VERSION ""

NS_ :

BS_:

BU_: PowertrainControlModule AtmosphericSensor SafetyRestraintSystem2 Aftertreatment_2_GasOutlet Aftertreatment_2_GasIntake DieselParticulateFilterControl Turbocharger SafetyRestraintSystem1 CabDisplay2 Aftertreatment_1_GasOutlet Aftertreatment_1_GasIntake OnBoardDataLogger OffBoardDiagnosticTool2 OffBoardDiagnosticTool1 FileServer ParkingBrakeController SeatController2 FanDriveController SteeringColumnUnit CommunicationUnitRadio CommunicationUnitSatellite CommunicationUnitCellular PropulsionBatteryCharger ChassisController2 ChassisController1 EngineValveControl AuxiliaryHeater2 AuxiliaryHeater1 ClutchUnit RampControl InformationSystem1 SuspensionSystemController2 OilSensor VehicleDynamicStability ExhaustEmissionController TransmissionDisplay2 TransmissionDisplay1 ClimateControl2 WaterPumpController RearAxleSteeringController LightingOperatorControl SeatController1 IgnitionController2 IgnitionController1 TirePressureController CabController2 CabController1 PneumaticSystemController SuspensionSystemController1 HydraulicPumpController EnduranceBrakingSystem RetarderExhaustEngine2 OnBoardDiagnosticUnit HeadwayController RetarderExhaustEngine1 CabDisplay1 ManagementComputer VirtualTerminal OffVehicleGateway PowerTakeOffFront HitchControl AuxiliaryValveControl BodyController TractorTrailerBridge1 StarterSystem ElectricalSystem VehicleSecurity VehicleNavigation AerodynamicControl ElectricalChargingSystem ClimateControl1 TripRecorder InstrumentCluster SuspensionDriveAxle2 SuspensionDriveAxle1 SuspensionSteerAxle SteeringController FuelSystem CruiseControl RetarderDriveline RetarderEngine BrakesDriveAxle2 BrakesDriveAxle1 BrakesSystemController BrakesSteerAxle AxleDrive2 AxleDrive1 AxleSteering PowerTakeOff ShiftConsoleSecondary ShiftConsolePrimary Transmission2 Transmission1 Engine2 Engine1

BO_ 2364712446 HVESP16MS1: 8 Vector__XXX
 SG_ Module32OperationalStatus : 62|2@1+ (1,0) [0|3] "" Vector__XXX
 SG_ Module31OperationalStatus : 60|2@1+ (1,0) [0|3] "" Vector__XXX
 SG_ Module30OperationalStatus : 58|2@1+ (1,0) [0|3] "" Vector__XXX
 SG_ Module29OperationalStatus : 56|2@1+ (1,0) [0|3] "" Vector__XXX
 SG_ Module28OperationalStatus : 54|2@1+ (1,0) [0|3] "" Vector__XXX
 SG_ Module27OperationalStatus : 52|2@1+ (1,0) [0|3] "" Vector__XXX
 SG_ Module26OperationalStatus : 50|2@1+ (1,0) [0|3] "" Vector__XXX
 SG_ Module25OperationalStatus : 48|2@1+ (1,0) [0|3] "" Vector__XXX
 SG_ Module24OperationalStatus : 46|2@1+ (1,0) [0|3] "" Vector__XXX
 SG_ Module23OperationalStatus : 44|2@1+ (1,0) [0|3] "" Vector__XXX
 SG_ Module22OperationalStatus : 42|2@1+ (1,0) [0|3] "" Vector__XXX
 SG_ Module21OperationalStatus : 40|2@1+ (1,0) [0|3] "" Vector__XXX
 SG_ Module20OperationalStatus : 38|2@1+ (1,0) [0|3] "" Vector__XXX
 SG_ Module19OperationalStatus : 36|2@1+ (1,0) [0|3] "" Vector__XXX
 SG_ Module18OperationalStatus : 34|2@1+ (1,0) [0|3] "" Vector__XXX
 SG_ Module17OperationalStatus : 32|2@1+ (1,0) [0|3] "" Vector__XXX
 SG_ Module16OperationalStatus : 30|2@1+ (1,0) [0|3] "" Vector__XXX
 SG_ Module15OperationalStatus : 28|2@1+ (1,0) [0|3] "" Vector__XXX
 SG_ Module14OperationalStatus : 26|2@1+ (1,0) [0|3] "" Vector__XXX
 SG_ Module13OperationalStatus : 24|2@1+ (1,0) [0|3] "" Vector__XXX
 SG_ Module12OperationalStatus : 22|2@1+ (1,0) [0|3] "" Vector__XXX
 SG_ Module11OperationalStatus : 20|2@1+ (1,0) [0|3] "" Vector__XXX
 SG_ Module10OperationalStatus : 18|2@1+ (1,0) [0|3] "" Vector__XXX
 SG_ Module9OperationalStatus : 16|2@1+ (1,0) [0|3] "" Vector__XXX
 SG_ Module8OperationalStatus : 14|2@1+ (1,0) [0|3] "" Vector__XXX
 SG_ Module7OperationalStatus : 12|2@1+ (1,0) [0|3] "" Vector__XXX
 SG_ Module6OperationalStatus : 10|2@1+ (1,0) [0|3] "" Vector__XXX
 SG_ Module5OperationalStatus : 8|2@1+ (1,0) [0|3] "" Vector__XXX
 SG_ Module4OperationalStatus : 6|2@1+ (1,0) [0|3] "" Vector__XXX
 SG_ Module3OperationalStatus : 4|2@1+ (1,0) [0|3] "" Vector__XXX
 SG_ Module2OperationalStatus : 2|2@1+ (1,0) [0|3] "" Vector__XXX
 SG_ Module1OperationalStatus : 0|2@1+ (1,0) [0|3] "" Vector__XXX

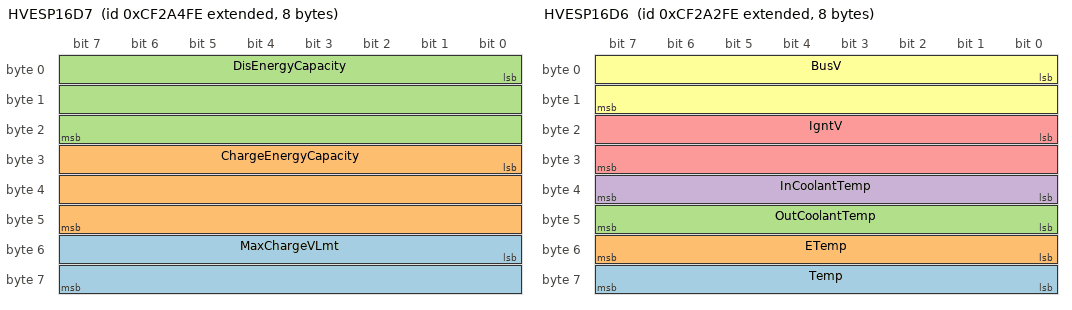
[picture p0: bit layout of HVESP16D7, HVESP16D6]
BO_ 2364712190 HVESP16D7: 8 Vector__XXX
 SG_ MaxChargeVLmt : 48|16@1+ (0.05,0) [0|3212.75] "V" Vector__XXX
 SG_ ChargeEnergyCapacity : 24|24@1+ (0.001,0) [0|16449.535] "kWh" Vector__XXX
 SG_ DisEnergyCapacity : 0|24@1+ (0.001,0) [0|16449.535] "kWh" Vector__XXX

BO_ 2364711934 HVESP16S1: 8 Vector__XXX
 SG_ Status1CRC : 56|8@1+ (1,0) [0|255] "" Vector__XXX
 SG_ Status1Counter : 52|4@1+ (1,0) [0|15] "" Vector__XXX
 SG_ OperationalStatus : 44|4@1+ (1,0) [0|15] "" Vector__XXX
 SG_ HVBusConnectionStatus : 40|4@1+ (1,0) [0|15] "" Vector__XXX
 SG_ InternalChargerStatus : 32|2@1+ (1,0) [0|3] "" Vector__XXX
 SG_ CellBalancingActive : 30|2@1+ (1,0) [0|3] "" Vector__XXX
 SG_ CellBalanceStatus : 28|2@1+ (1,0) [0|3] "" Vector__XXX
 SG_ StOfChargeStatus : 24|4@1+ (1,0) [0|15] "" Vector__XXX
 SG_ InertiaSwStatus : 22|2@1+ (1,0) [0|3] "" Vector__XXX
 SG_ HVILStatus : 20|2@1+ (1,0) [0|3] "" Vector__XXX
 SG_ HVBusPassiveIsolTestStatus : 16|4@1+ (1,0) [0|15] "" Vector__XXX
 SG_ HVBusActiveIsolTestStatus : 12|4@1+ (1,0) [0|15] "" Vector__XXX
 SG_ CenterOfPackContactorSt : 10|2@1+ (1,0) [0|3] "" Vector__XXX
 SG_ HVBusPreChargeRelaySt : 8|2@1+ (1,0) [0|3] "" Vector__XXX
 SG_ HVBusDisconnectForewarning : 4|4@1+ (1,0) [0|15] "" Vector__XXX
 SG_ HVBusContactorSt16028 : 2|2@1+ (1,0) [0|3] "" Vector__XXX
 SG_ HVBusContactorSt : 0|2@1+ (1,0) [0|3] "" Vector__XXX

BO_ 2364711678 HVESP16D6: 8 Vector__XXX
 SG_ Temp : 56|8@1+ (1,-40) [-40|210] "°C" Vector__XXX
 SG_ ETemp : 48|8@1+ (1,-40) [-40|210] "°C" Vector__XXX
 SG_ OutCoolantTemp : 40|8@1+ (1,-40) [-40|210] "°C" Vector__XXX
 SG_ InCoolantTemp : 32|8@1+ (1,-40) [-40|210] "°C" Vector__XXX
 SG_ IgntV : 16|16@1+ (0.01,0) [0|642.55] "V" Vector__XXX
 SG_ BusV : 0|16@1+ (0.05,0) [0|3212.75] "V" Vector__XXX

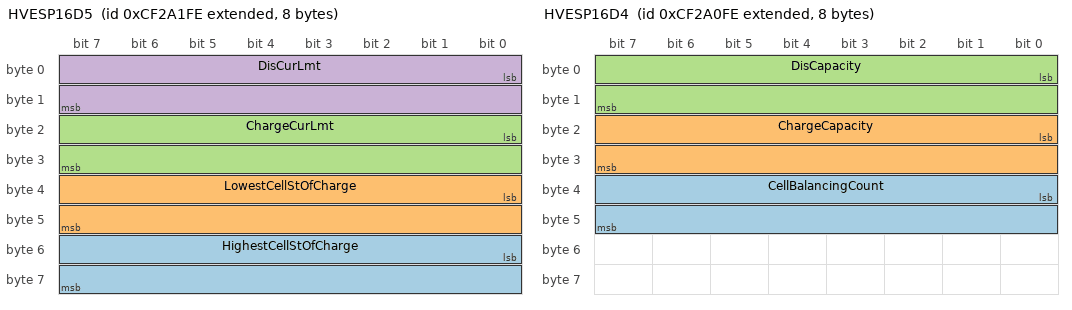
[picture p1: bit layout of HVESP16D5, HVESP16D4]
BO_ 2364711422 HVESP16D5: 8 Vector__XXX
 SG_ HighestCellStOfCharge : 48|16@1+ (0.0015625,0) [0|100.3984375] "%" Vector__XXX
 SG_ LowestCellStOfCharge : 32|16@1+ (0.0015625,0) [0|100.3984375] "%" Vector__XXX
 SG_ ChargeCurLmt : 16|16@1+ (0.05,-1600) [0|1612.75] "A" Vector__XXX
 SG_ DisCurLmt : 0|16@1+ (0.05,-1600) [-1600|0] "A" Vector__XXX

BO_ 2364711166 HVESP16D4: 8 Vector__XXX
 SG_ CellBalancingCount : 32|16@1+ (1,0) [0|64255] "" Vector__XXX
 SG_ ChargeCapacity : 16|16@1+ (0.01,0) [0|642.55] "Ah" Vector__XXX
 SG_ DisCapacity : 0|16@1+ (0.01,0) [0|642.55] "Ah" Vector__XXX

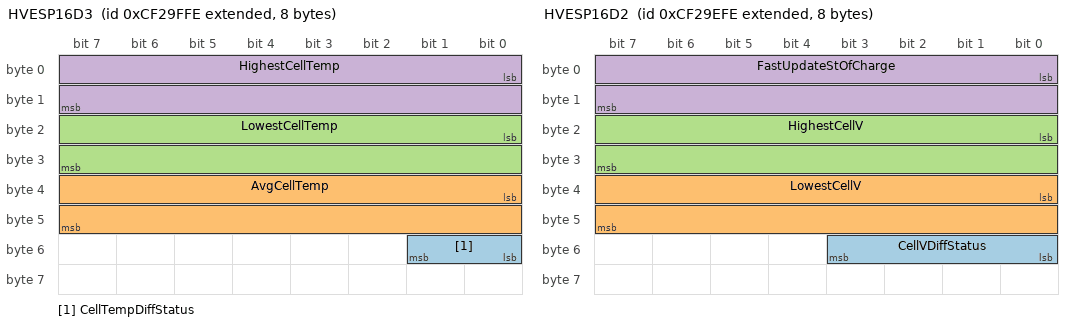
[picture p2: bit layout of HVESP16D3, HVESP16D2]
BO_ 2364710910 HVESP16D3: 8 Vector__XXX
 SG_ CellTempDiffStatus : 48|2@1+ (1,0) [0|3] "" Vector__XXX
 SG_ AvgCellTemp : 32|16@1+ (0.03125,-273) [-273|1734.96875] "°C" Vector__XXX
 SG_ LowestCellTemp : 16|16@1+ (0.03125,-273) [-273|1734.96875] "°C" Vector__XXX
 SG_ HighestCellTemp : 0|16@1+ (0.03125,-273) [-273|1734.96875] "°C" Vector__XXX

BO_ 2364710654 HVESP16D2: 8 Vector__XXX
 SG_ CellVDiffStatus : 48|4@1+ (1,0) [0|15] "" Vector__XXX
 SG_ LowestCellV : 32|16@1+ (0.001,0) [0|64.255] "V" Vector__XXX
 SG_ HighestCellV : 16|16@1+ (0.001,0) [0|64.255] "V" Vector__XXX
 SG_ FastUpdateStOfCharge : 0|16@1+ (0.0015625,0) [0|100.3984375] "%" Vector__XXX

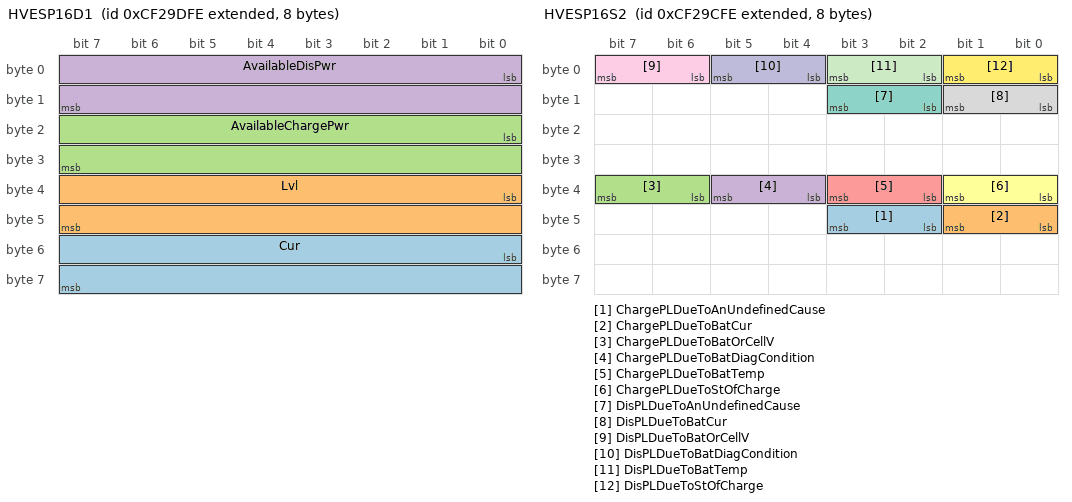
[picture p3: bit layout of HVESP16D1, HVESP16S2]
BO_ 2364710398 HVESP16D1: 8 Vector__XXX
 SG_ Cur : 48|16@1+ (0.05,-1600) [-1600|1612.75] "A" Vector__XXX
 SG_ Lvl : 32|16@1+ (0.05,0) [0|3212.75] "V" Vector__XXX
 SG_ AvailableChargePwr : 16|16@1+ (0.05,0) [0|3212.75] "kW" Vector__XXX
 SG_ AvailableDisPwr : 0|16@1+ (0.05,0) [0|3212.75] "kW" Vector__XXX

BO_ 2364710142 HVESP16S2: 8 Vector__XXX
 SG_ ChargePLDueToAnUndefinedCause : 42|2@1+ (1,0) [0|3] "" Vector__XXX
 SG_ ChargePLDueToBatCur : 40|2@1+ (1,0) [0|3] "" Vector__XXX
 SG_ ChargePLDueToBatOrCellV : 38|2@1+ (1,0) [0|3] "" Vector__XXX
 SG_ ChargePLDueToBatDiagCondition : 36|2@1+ (1,0) [0|3] "" Vector__XXX
 SG_ ChargePLDueToBatTemp : 34|2@1+ (1,0) [0|3] "" Vector__XXX
 SG_ ChargePLDueToStOfCharge : 32|2@1+ (1,0) [0|3] "" Vector__XXX
 SG_ DisPLDueToAnUndefinedCause : 10|2@1+ (1,0) [0|3] "" Vector__XXX
 SG_ DisPLDueToBatCur : 8|2@1+ (1,0) [0|3] "" Vector__XXX
 SG_ DisPLDueToBatOrCellV : 6|2@1+ (1,0) [0|3] "" Vector__XXX
 SG_ DisPLDueToBatDiagCondition : 4|2@1+ (1,0) [0|3] "" Vector__XXX
 SG_ DisPLDueToBatTemp : 2|2@1+ (1,0) [0|3] "" Vector__XXX
 SG_ DisPLDueToStOfCharge : 0|2@1+ (1,0) [0|3] "" Vector__XXX

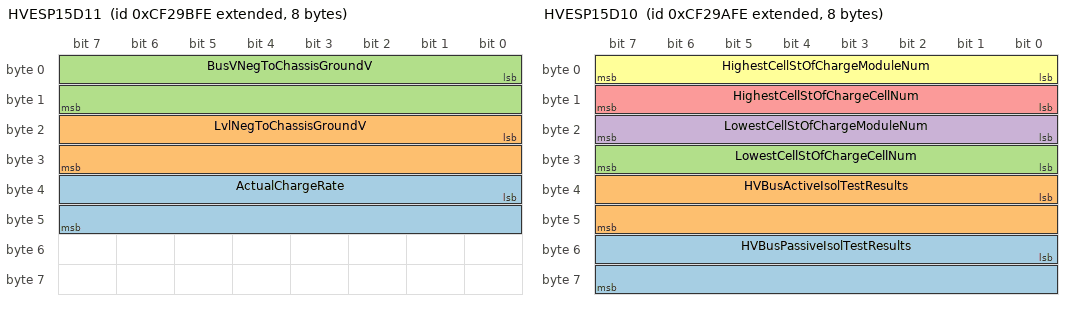
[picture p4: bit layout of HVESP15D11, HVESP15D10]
BO_ 2364709886 HVESP15D11: 8 Vector__XXX
 SG_ ActualChargeRate : 32|16@1+ (0.05,0) [0|3212.75] "kW" Vector__XXX
 SG_ LvlNegToChassisGroundV : 16|16@1+ (0.05,0) [0|3212.75] "V" Vector__XXX
 SG_ BusVNegToChassisGroundV : 0|16@1+ (0.05,0) [0|3212.75] "V" Vector__XXX

BO_ 2364709630 HVESP15D10: 8 Vector__XXX
 SG_ HVBusPassiveIsolTestResults : 48|16@1+ (0.1,0) [0|6425.5] "Ohm/V" Vector__XXX
 SG_ HVBusActiveIsolTestResults : 32|16@1+ (0.1,0) [0|6425.5] "Ohm/V" Vector__XXX
 SG_ LowestCellStOfChargeCellNum : 24|8@1+ (1,0) [0|250] "" Vector__XXX
 SG_ LowestCellStOfChargeModuleNum : 16|8@1+ (1,0) [0|250] "" Vector__XXX
 SG_ HighestCellStOfChargeCellNum : 8|8@1+ (1,0) [0|250] "" Vector__XXX
 SG_ HighestCellStOfChargeModuleNum : 0|8@1+ (1,0) [0|250] "" Vector__XXX

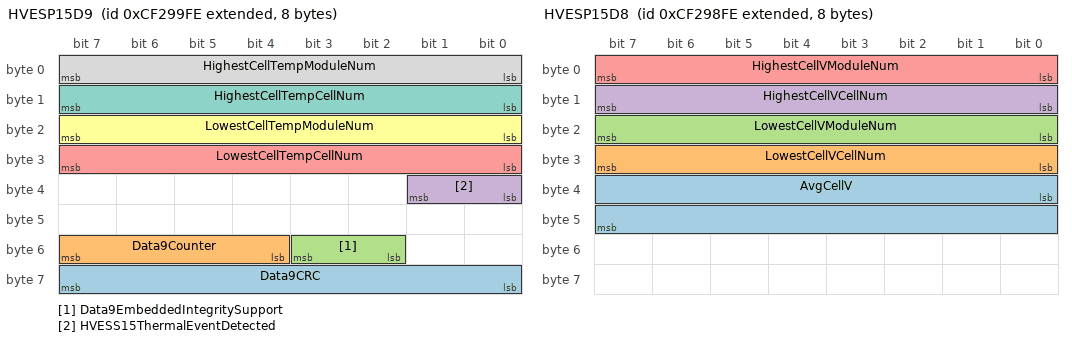
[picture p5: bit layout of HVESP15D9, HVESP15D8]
BO_ 2364709374 HVESP15D9: 8 Vector__XXX
 SG_ Data9CRC : 56|8@1+ (1,0) [0|255] "" Vector__XXX
 SG_ Data9Counter : 52|4@1+ (1,0) [0|15] "" Vector__XXX
 SG_ Data9EmbeddedIntegritySupport : 50|2@1+ (1,0) [0|3] "" Vector__XXX
 SG_ HVESS15ThermalEventDetected : 32|2@1+ (1,0) [0|3] "" Vector__XXX
 SG_ LowestCellTempCellNum : 24|8@1+ (1,0) [0|250] "" Vector__XXX
 SG_ LowestCellTempModuleNum : 16|8@1+ (1,0) [0|250] "" Vector__XXX
 SG_ HighestCellTempCellNum : 8|8@1+ (1,0) [0|250] "" Vector__XXX
 SG_ HighestCellTempModuleNum : 0|8@1+ (1,0) [0|250] "" Vector__XXX

BO_ 2364709118 HVESP15D8: 8 Vector__XXX
 SG_ AvgCellV : 32|16@1+ (0.001,0) [0|64.255] "V" Vector__XXX
 SG_ LowestCellVCellNum : 24|8@1+ (1,0) [0|250] "" Vector__XXX
 SG_ LowestCellVModuleNum : 16|8@1+ (1,0) [0|250] "" Vector__XXX
 SG_ HighestCellVCellNum : 8|8@1+ (1,0) [0|250] "" Vector__XXX
 SG_ HighestCellVModuleNum : 0|8@1+ (1,0) [0|250] "" Vector__XXX

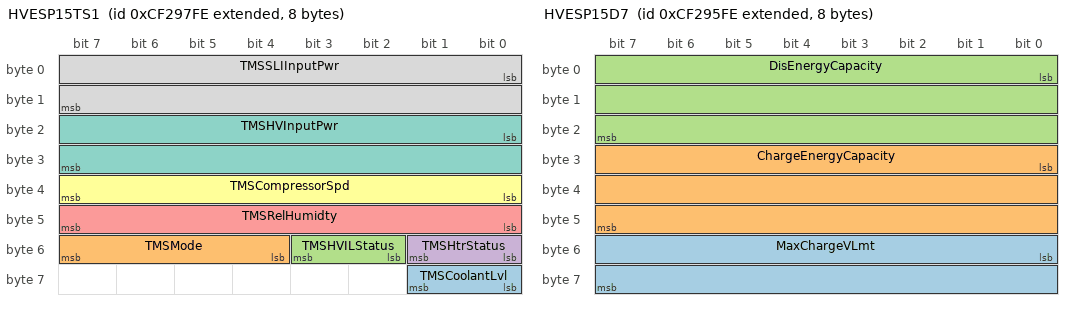
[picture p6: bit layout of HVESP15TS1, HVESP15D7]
BO_ 2364708862 HVESP15TS1: 8 Vector__XXX
 SG_ TMSCoolantLvl : 56|2@1+ (1,0) [0|3] "" Vector__XXX
 SG_ TMSMode : 52|4@1+ (1,0) [0|15] "" Vector__XXX
 SG_ TMSHVILStatus : 50|2@1+ (1,0) [0|3] "" Vector__XXX
 SG_ TMSHtrStatus : 48|2@1+ (1,0) [0|3] "" Vector__XXX
 SG_ TMSRelHumidty : 40|8@1+ (0.4,0) [0|100] "%" Vector__XXX
 SG_ TMSCompressorSpd : 32|8@1+ (32,0) [0|8000] "rpm" Vector__XXX
 SG_ TMSHVInputPwr : 16|16@1+ (0.5,0) [0|32127.5] "W" Vector__XXX
 SG_ TMSSLIInputPwr : 0|16@1+ (0.5,0) [0|32127.5] "W" Vector__XXX

BO_ 2364708606 HVESP15MS1: 8 Vector__XXX
 SG_ Module32OperationalStatus : 62|2@1+ (1,0) [0|3] "" Vector__XXX
 SG_ Module31OperationalStatus : 60|2@1+ (1,0) [0|3] "" Vector__XXX
 SG_ Module30OperationalStatus : 58|2@1+ (1,0) [0|3] "" Vector__XXX
 SG_ Module29OperationalStatus : 56|2@1+ (1,0) [0|3] "" Vector__XXX
 SG_ Module28OperationalStatus : 54|2@1+ (1,0) [0|3] "" Vector__XXX
 SG_ Module27OperationalStatus : 52|2@1+ (1,0) [0|3] "" Vector__XXX
 SG_ Module26OperationalStatus : 50|2@1+ (1,0) [0|3] "" Vector__XXX
 SG_ Module25OperationalStatus : 48|2@1+ (1,0) [0|3] "" Vector__XXX
 SG_ Module24OperationalStatus : 46|2@1+ (1,0) [0|3] "" Vector__XXX
 SG_ Module23OperationalStatus : 44|2@1+ (1,0) [0|3] "" Vector__XXX
 SG_ Module22OperationalStatus : 42|2@1+ (1,0) [0|3] "" Vector__XXX
 SG_ Module21OperationalStatus : 40|2@1+ (1,0) [0|3] "" Vector__XXX
 SG_ Module20OperationalStatus : 38|2@1+ (1,0) [0|3] "" Vector__XXX
 SG_ Module19OperationalStatus : 36|2@1+ (1,0) [0|3] "" Vector__XXX
 SG_ Module18OperationalStatus : 34|2@1+ (1,0) [0|3] "" Vector__XXX
 SG_ Module17OperationalStatus : 32|2@1+ (1,0) [0|3] "" Vector__XXX
 SG_ Module16OperationalStatus : 30|2@1+ (1,0) [0|3] "" Vector__XXX
 SG_ Module15OperationalStatus : 28|2@1+ (1,0) [0|3] "" Vector__XXX
 SG_ Module14OperationalStatus : 26|2@1+ (1,0) [0|3] "" Vector__XXX
 SG_ Module13OperationalStatus : 24|2@1+ (1,0) [0|3] "" Vector__XXX
 SG_ Module12OperationalStatus : 22|2@1+ (1,0) [0|3] "" Vector__XXX
 SG_ Module11OperationalStatus : 20|2@1+ (1,0) [0|3] "" Vector__XXX
 SG_ Module10OperationalStatus : 18|2@1+ (1,0) [0|3] "" Vector__XXX
 SG_ Module9OperationalStatus : 16|2@1+ (1,0) [0|3] "" Vector__XXX
 SG_ Module8OperationalStatus : 14|2@1+ (1,0) [0|3] "" Vector__XXX
 SG_ Module7OperationalStatus : 12|2@1+ (1,0) [0|3] "" Vector__XXX
 SG_ Module6OperationalStatus : 10|2@1+ (1,0) [0|3] "" Vector__XXX
 SG_ Module5OperationalStatus : 8|2@1+ (1,0) [0|3] "" Vector__XXX
 SG_ Module4OperationalStatus : 6|2@1+ (1,0) [0|3] "" Vector__XXX
 SG_ Module3OperationalStatus : 4|2@1+ (1,0) [0|3] "" Vector__XXX
 SG_ Module2OperationalStatus : 2|2@1+ (1,0) [0|3] "" Vector__XXX
 SG_ Module1OperationalStatus : 0|2@1+ (1,0) [0|3] "" Vector__XXX

BO_ 2364708350 HVESP15D7: 8 Vector__XXX
 SG_ MaxChargeVLmt : 48|16@1+ (0.05,0) [0|3212.75] "V" Vector__XXX
 SG_ ChargeEnergyCapacity : 24|24@1+ (0.001,0) [0|16449.535] "kWh" Vector__XXX
 SG_ DisEnergyCapacity : 0|24@1+ (0.001,0) [0|16449.535] "kWh" Vector__XXX

BO_ 2364708094 HVESP15S1: 8 Vector__XXX
 SG_ Status1CRC : 56|8@1+ (1,0) [0|255] "" Vector__XXX
 SG_ Status1Counter : 52|4@1+ (1,0) [0|15] "" Vector__XXX
 SG_ OperationalStatus : 44|4@1+ (1,0) [0|15] "" Vector__XXX
 SG_ HVBusConnectionStatus : 40|4@1+ (1,0) [0|15] "" Vector__XXX
 SG_ InternalChargerStatus : 32|2@1+ (1,0) [0|3] "" Vector__XXX
 SG_ CellBalancingActive : 30|2@1+ (1,0) [0|3] "" Vector__XXX
 SG_ CellBalanceStatus : 28|2@1+ (1,0) [0|3] "" Vector__XXX
 SG_ StOfChargeStatus : 24|4@1+ (1,0) [0|15] "" Vector__XXX
 SG_ InertiaSwStatus : 22|2@1+ (1,0) [0|3] "" Vector__XXX
 SG_ HVILStatus : 20|2@1+ (1,0) [0|3] "" Vector__XXX
 SG_ HVBusPassiveIsolTestStatus : 16|4@1+ (1,0) [0|15] "" Vector__XXX
 SG_ HVBusActiveIsolTestStatus : 12|4@1+ (1,0) [0|15] "" Vector__XXX
 SG_ CenterOfPackContactorSt : 10|2@1+ (1,0) [0|3] "" Vector__XXX
 SG_ HVBusPreChargeRelaySt : 8|2@1+ (1,0) [0|3] "" Vector__XXX
 SG_ HVBusDisconnectForewarning : 4|4@1+ (1,0) [0|15] "" Vector__XXX
 SG_ HVBusContactorSt15886 : 2|2@1+ (1,0) [0|3] "" Vector__XXX
 SG_ HVBusContactorSt : 0|2@1+ (1,0) [0|3] "" Vector__XXX

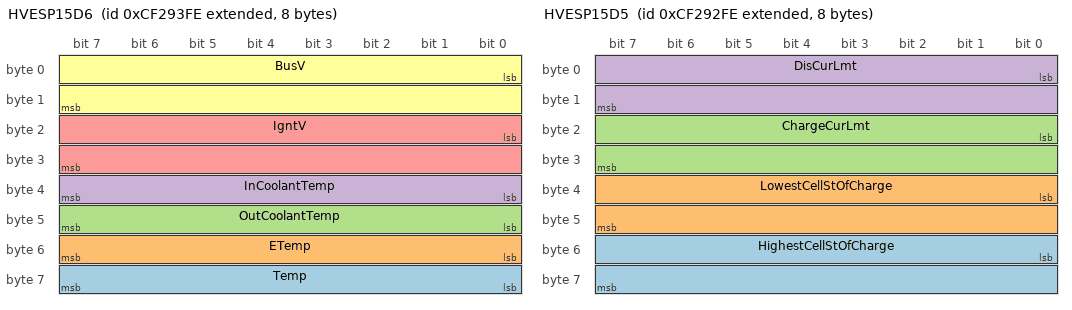
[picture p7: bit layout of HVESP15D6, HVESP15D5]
BO_ 2364707838 HVESP15D6: 8 Vector__XXX
 SG_ Temp : 56|8@1+ (1,-40) [-40|210] "°C" Vector__XXX
 SG_ ETemp : 48|8@1+ (1,-40) [-40|210] "°C" Vector__XXX
 SG_ OutCoolantTemp : 40|8@1+ (1,-40) [-40|210] "°C" Vector__XXX
 SG_ InCoolantTemp : 32|8@1+ (1,-40) [-40|210] "°C" Vector__XXX
 SG_ IgntV : 16|16@1+ (0.01,0) [0|642.55] "V" Vector__XXX
 SG_ BusV : 0|16@1+ (0.05,0) [0|3212.75] "V" Vector__XXX

BO_ 2364707582 HVESP15D5: 8 Vector__XXX
 SG_ HighestCellStOfCharge : 48|16@1+ (0.0015625,0) [0|100.3984375] "%" Vector__XXX
 SG_ LowestCellStOfCharge : 32|16@1+ (0.0015625,0) [0|100.3984375] "%" Vector__XXX
 SG_ ChargeCurLmt : 16|16@1+ (0.05,-1600) [0|1612.75] "A" Vector__XXX
 SG_ DisCurLmt : 0|16@1+ (0.05,-1600) [-1600|0] "A" Vector__XXX

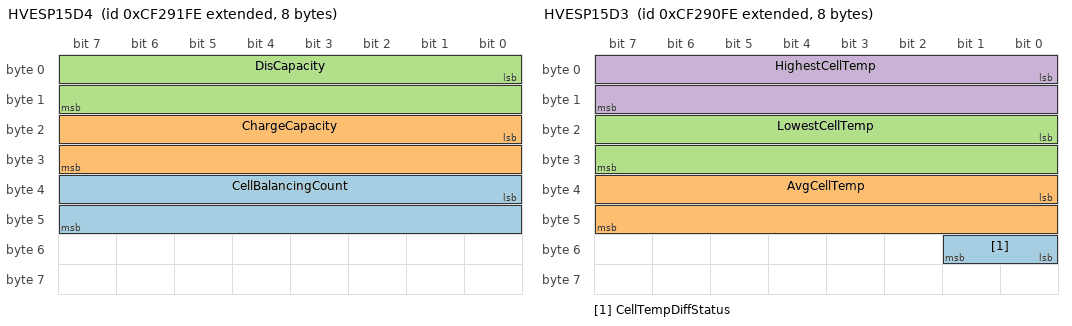
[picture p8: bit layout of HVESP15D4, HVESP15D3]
BO_ 2364707326 HVESP15D4: 8 Vector__XXX
 SG_ CellBalancingCount : 32|16@1+ (1,0) [0|64255] "" Vector__XXX
 SG_ ChargeCapacity : 16|16@1+ (0.01,0) [0|642.55] "Ah" Vector__XXX
 SG_ DisCapacity : 0|16@1+ (0.01,0) [0|642.55] "Ah" Vector__XXX

BO_ 2364707070 HVESP15D3: 8 Vector__XXX
 SG_ CellTempDiffStatus : 48|2@1+ (1,0) [0|3] "" Vector__XXX
 SG_ AvgCellTemp : 32|16@1+ (0.03125,-273) [-273|1734.96875] "°C" Vector__XXX
 SG_ LowestCellTemp : 16|16@1+ (0.03125,-273) [-273|1734.96875] "°C" Vector__XXX
 SG_ HighestCellTemp : 0|16@1+ (0.03125,-273) [-273|1734.96875] "°C" Vector__XXX

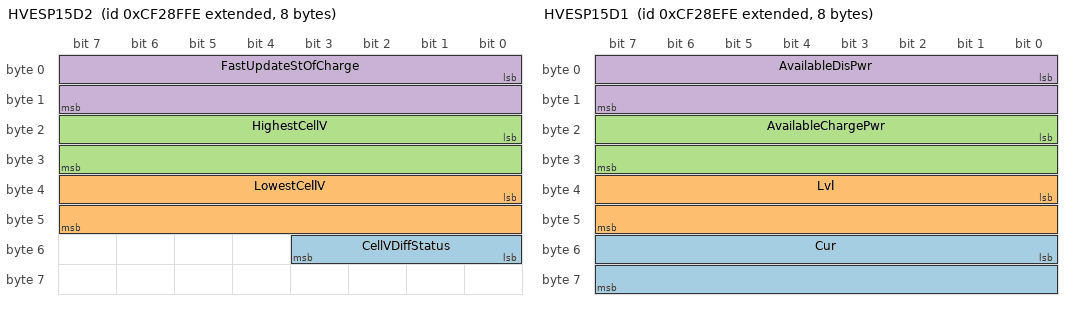
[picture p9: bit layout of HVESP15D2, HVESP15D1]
BO_ 2364706814 HVESP15D2: 8 Vector__XXX
 SG_ CellVDiffStatus : 48|4@1+ (1,0) [0|15] "" Vector__XXX
 SG_ LowestCellV : 32|16@1+ (0.001,0) [0|64.255] "V" Vector__XXX
 SG_ HighestCellV : 16|16@1+ (0.001,0) [0|64.255] "V" Vector__XXX
 SG_ FastUpdateStOfCharge : 0|16@1+ (0.0015625,0) [0|100.3984375] "%" Vector__XXX

BO_ 2364706558 HVESP15D1: 8 Vector__XXX
 SG_ Cur : 48|16@1+ (0.05,-1600) [-1600|1612.75] "A" Vector__XXX
 SG_ Lvl : 32|16@1+ (0.05,0) [0|3212.75] "V" Vector__XXX
 SG_ AvailableChargePwr : 16|16@1+ (0.05,0) [0|3212.75] "kW" Vector__XXX
 SG_ AvailableDisPwr : 0|16@1+ (0.05,0) [0|3212.75] "kW" Vector__XXX

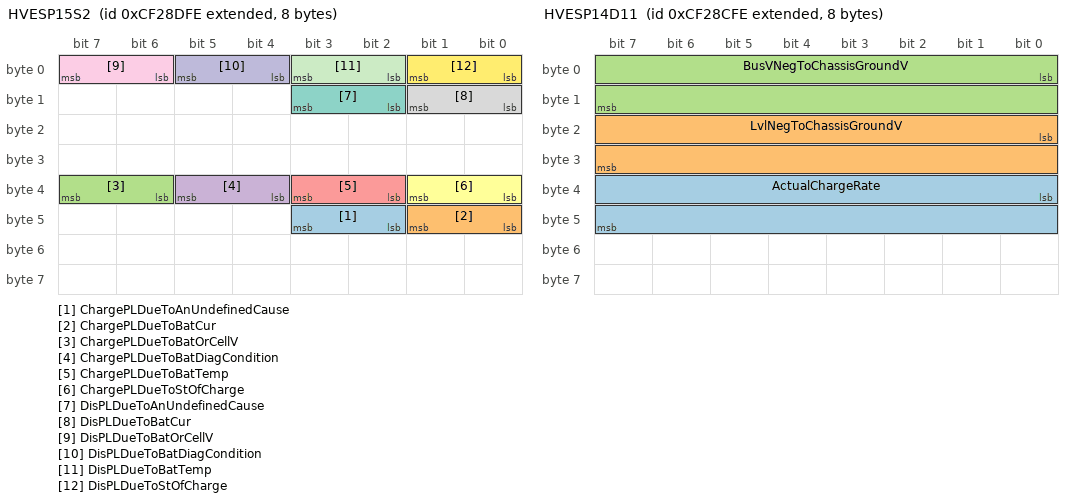
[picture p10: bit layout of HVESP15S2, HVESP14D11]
BO_ 2364706302 HVESP15S2: 8 Vector__XXX
 SG_ ChargePLDueToAnUndefinedCause : 42|2@1+ (1,0) [0|3] "" Vector__XXX
 SG_ ChargePLDueToBatCur : 40|2@1+ (1,0) [0|3] "" Vector__XXX
 SG_ ChargePLDueToBatOrCellV : 38|2@1+ (1,0) [0|3] "" Vector__XXX
 SG_ ChargePLDueToBatDiagCondition : 36|2@1+ (1,0) [0|3] "" Vector__XXX
 SG_ ChargePLDueToBatTemp : 34|2@1+ (1,0) [0|3] "" Vector__XXX
 SG_ ChargePLDueToStOfCharge : 32|2@1+ (1,0) [0|3] "" Vector__XXX
 SG_ DisPLDueToAnUndefinedCause : 10|2@1+ (1,0) [0|3] "" Vector__XXX
 SG_ DisPLDueToBatCur : 8|2@1+ (1,0) [0|3] "" Vector__XXX
 SG_ DisPLDueToBatOrCellV : 6|2@1+ (1,0) [0|3] "" Vector__XXX
 SG_ DisPLDueToBatDiagCondition : 4|2@1+ (1,0) [0|3] "" Vector__XXX
 SG_ DisPLDueToBatTemp : 2|2@1+ (1,0) [0|3] "" Vector__XXX
 SG_ DisPLDueToStOfCharge : 0|2@1+ (1,0) [0|3] "" Vector__XXX

BO_ 2364706046 HVESP14D11: 8 Vector__XXX
 SG_ ActualChargeRate : 32|16@1+ (0.05,0) [0|3212.75] "kW" Vector__XXX
 SG_ LvlNegToChassisGroundV : 16|16@1+ (0.05,0) [0|3212.75] "V" Vector__XXX
 SG_ BusVNegToChassisGroundV : 0|16@1+ (0.05,0) [0|3212.75] "V" Vector__XXX

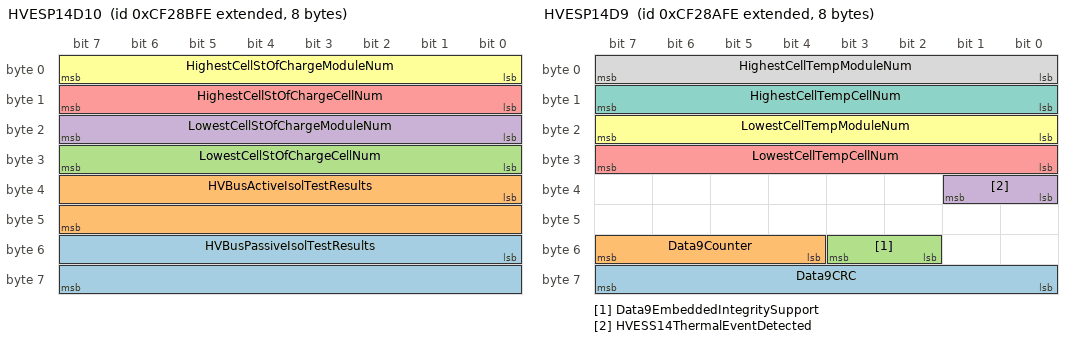
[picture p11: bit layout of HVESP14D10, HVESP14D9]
BO_ 2364705790 HVESP14D10: 8 Vector__XXX
 SG_ HVBusPassiveIsolTestResults : 48|16@1+ (0.1,0) [0|6425.5] "Ohm/V" Vector__XXX
 SG_ HVBusActiveIsolTestResults : 32|16@1+ (0.1,0) [0|6425.5] "Ohm/V" Vector__XXX
 SG_ LowestCellStOfChargeCellNum : 24|8@1+ (1,0) [0|250] "" Vector__XXX
 SG_ LowestCellStOfChargeModuleNum : 16|8@1+ (1,0) [0|250] "" Vector__XXX
 SG_ HighestCellStOfChargeCellNum : 8|8@1+ (1,0) [0|250] "" Vector__XXX
 SG_ HighestCellStOfChargeModuleNum : 0|8@1+ (1,0) [0|250] "" Vector__XXX

BO_ 2364705534 HVESP14D9: 8 Vector__XXX
 SG_ Data9CRC : 56|8@1+ (1,0) [0|255] "" Vector__XXX
 SG_ Data9Counter : 52|4@1+ (1,0) [0|15] "" Vector__XXX
 SG_ Data9EmbeddedIntegritySupport : 50|2@1+ (1,0) [0|3] "" Vector__XXX
 SG_ HVESS14ThermalEventDetected : 32|2@1+ (1,0) [0|3] "" Vector__XXX
 SG_ LowestCellTempCellNum : 24|8@1+ (1,0) [0|250] "" Vector__XXX
 SG_ LowestCellTempModuleNum : 16|8@1+ (1,0) [0|250] "" Vector__XXX
 SG_ HighestCellTempCellNum : 8|8@1+ (1,0) [0|250] "" Vector__XXX
 SG_ HighestCellTempModuleNum : 0|8@1+ (1,0) [0|250] "" Vector__XXX

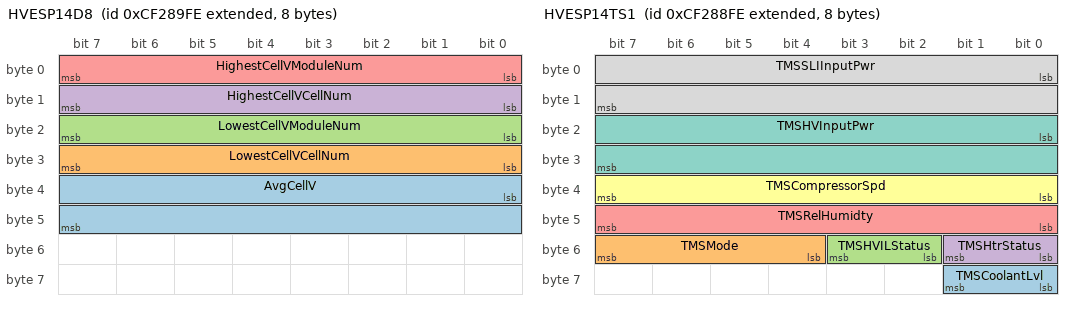
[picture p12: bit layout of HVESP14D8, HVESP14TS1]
BO_ 2364705278 HVESP14D8: 8 Vector__XXX
 SG_ AvgCellV : 32|16@1+ (0.001,0) [0|64.255] "V" Vector__XXX
 SG_ LowestCellVCellNum : 24|8@1+ (1,0) [0|250] "" Vector__XXX
 SG_ LowestCellVModuleNum : 16|8@1+ (1,0) [0|250] "" Vector__XXX
 SG_ HighestCellVCellNum : 8|8@1+ (1,0) [0|250] "" Vector__XXX
 SG_ HighestCellVModuleNum : 0|8@1+ (1,0) [0|250] "" Vector__XXX

BO_ 2364705022 HVESP14TS1: 8 Vector__XXX
 SG_ TMSCoolantLvl : 56|2@1+ (1,0) [0|3] "" Vector__XXX
 SG_ TMSMode : 52|4@1+ (1,0) [0|15] "" Vector__XXX
 SG_ TMSHVILStatus : 50|2@1+ (1,0) [0|3] "" Vector__XXX
 SG_ TMSHtrStatus : 48|2@1+ (1,0) [0|3] "" Vector__XXX
 SG_ TMSRelHumidty : 40|8@1+ (0.4,0) [0|100] "%" Vector__XXX
 SG_ TMSCompressorSpd : 32|8@1+ (32,0) [0|8000] "rpm" Vector__XXX
 SG_ TMSHVInputPwr : 16|16@1+ (0.5,0) [0|32127.5] "W" Vector__XXX
 SG_ TMSSLIInputPwr : 0|16@1+ (0.5,0) [0|32127.5] "W" Vector__XXX

BO_ 2364704766 HVESP14MS1: 8 Vector__XXX
 SG_ Module32OperationalStatus : 62|2@1+ (1,0) [0|3] "" Vector__XXX
 SG_ Module31OperationalStatus : 60|2@1+ (1,0) [0|3] "" Vector__XXX
 SG_ Module30OperationalStatus : 58|2@1+ (1,0) [0|3] "" Vector__XXX
 SG_ Module29OperationalStatus : 56|2@1+ (1,0) [0|3] "" Vector__XXX
 SG_ Module28OperationalStatus : 54|2@1+ (1,0) [0|3] "" Vector__XXX
 SG_ Module27OperationalStatus : 52|2@1+ (1,0) [0|3] "" Vector__XXX
 SG_ Module26OperationalStatus : 50|2@1+ (1,0) [0|3] "" Vector__XXX
 SG_ Module25OperationalStatus : 48|2@1+ (1,0) [0|3] "" Vector__XXX
 SG_ Module24OperationalStatus : 46|2@1+ (1,0) [0|3] "" Vector__XXX
 SG_ Module23OperationalStatus : 44|2@1+ (1,0) [0|3] "" Vector__XXX
 SG_ Module22OperationalStatus : 42|2@1+ (1,0) [0|3] "" Vector__XXX
 SG_ Module21OperationalStatus : 40|2@1+ (1,0) [0|3] "" Vector__XXX
 SG_ Module20OperationalStatus : 38|2@1+ (1,0) [0|3] "" Vector__XXX
 SG_ Module19OperationalStatus : 36|2@1+ (1,0) [0|3] "" Vector__XXX
 SG_ Module18OperationalStatus : 34|2@1+ (1,0) [0|3] "" Vector__XXX
 SG_ Module17OperationalStatus : 32|2@1+ (1,0) [0|3] "" Vector__XXX
 SG_ Module16OperationalStatus : 30|2@1+ (1,0) [0|3] "" Vector__XXX
 SG_ Module15OperationalStatus : 28|2@1+ (1,0) [0|3] "" Vector__XXX
 SG_ Module14OperationalStatus : 26|2@1+ (1,0) [0|3] "" Vector__XXX
 SG_ Module13OperationalStatus : 24|2@1+ (1,0) [0|3] "" Vector__XXX
 SG_ Module12OperationalStatus : 22|2@1+ (1,0) [0|3] "" Vector__XXX
 SG_ Module11OperationalStatus : 20|2@1+ (1,0) [0|3] "" Vector__XXX
 SG_ Module10OperationalStatus : 18|2@1+ (1,0) [0|3] "" Vector__XXX
 SG_ Module9OperationalStatus : 16|2@1+ (1,0) [0|3] "" Vector__XXX
 SG_ Module8OperationalStatus : 14|2@1+ (1,0) [0|3] "" Vector__XXX
 SG_ Module7OperationalStatus : 12|2@1+ (1,0) [0|3] "" Vector__XXX
 SG_ Module6OperationalStatus : 10|2@1+ (1,0) [0|3] "" Vector__XXX
 SG_ Module5OperationalStatus : 8|2@1+ (1,0) [0|3] "" Vector__XXX
 SG_ Module4OperationalStatus : 6|2@1+ (1,0) [0|3] "" Vector__XXX
 SG_ Module3OperationalStatus : 4|2@1+ (1,0) [0|3] "" Vector__XXX
 SG_ Module2OperationalStatus : 2|2@1+ (1,0) [0|3] "" Vector__XXX
 SG_ Module1OperationalStatus : 0|2@1+ (1,0) [0|3] "" Vector__XXX

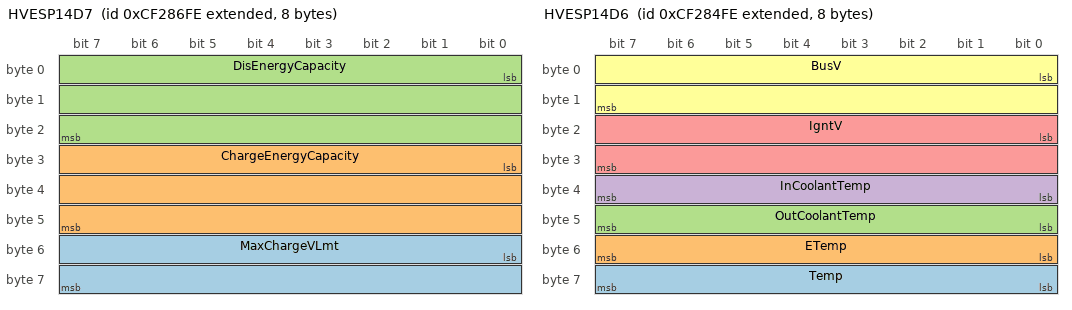
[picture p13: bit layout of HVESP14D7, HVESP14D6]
BO_ 2364704510 HVESP14D7: 8 Vector__XXX
 SG_ MaxChargeVLmt : 48|16@1+ (0.05,0) [0|3212.75] "V" Vector__XXX
 SG_ ChargeEnergyCapacity : 24|24@1+ (0.001,0) [0|16449.535] "kWh" Vector__XXX
 SG_ DisEnergyCapacity : 0|24@1+ (0.001,0) [0|16449.535] "kWh" Vector__XXX

BO_ 2364704254 HVESP14S1: 8 Vector__XXX
 SG_ Status1CRC : 56|8@1+ (1,0) [0|255] "" Vector__XXX
 SG_ Status1Counter : 52|4@1+ (1,0) [0|15] "" Vector__XXX
 SG_ OperationalStatus : 44|4@1+ (1,0) [0|15] "" Vector__XXX
 SG_ HVBusConnectionStatus : 40|4@1+ (1,0) [0|15] "" Vector__XXX
 SG_ InternalChargerStatus : 32|2@1+ (1,0) [0|3] "" Vector__XXX
 SG_ CellBalancingActive : 30|2@1+ (1,0) [0|3] "" Vector__XXX
 SG_ CellBalanceStatus : 28|2@1+ (1,0) [0|3] "" Vector__XXX
 SG_ StOfChargeStatus : 24|4@1+ (1,0) [0|15] "" Vector__XXX
 SG_ InertiaSwStatus : 22|2@1+ (1,0) [0|3] "" Vector__XXX
 SG_ HVILStatus : 20|2@1+ (1,0) [0|3] "" Vector__XXX
 SG_ HVBusPassiveIsolTestStatus : 16|4@1+ (1,0) [0|15] "" Vector__XXX
 SG_ HVBusActiveIsolTestStatus : 12|4@1+ (1,0) [0|15] "" Vector__XXX
 SG_ CenterOfPackContactorSt : 10|2@1+ (1,0) [0|3] "" Vector__XXX
 SG_ HVBusPreChargeRelaySt : 8|2@1+ (1,0) [0|3] "" Vector__XXX
 SG_ HVBusDisconnectForewarning : 4|4@1+ (1,0) [0|15] "" Vector__XXX
 SG_ HVBusContactorSt15744 : 2|2@1+ (1,0) [0|3] "" Vector__XXX
 SG_ HVBusContactorSt : 0|2@1+ (1,0) [0|3] "" Vector__XXX

BO_ 2364703998 HVESP14D6: 8 Vector__XXX
 SG_ Temp : 56|8@1+ (1,-40) [-40|210] "°C" Vector__XXX
 SG_ ETemp : 48|8@1+ (1,-40) [-40|210] "°C" Vector__XXX
 SG_ OutCoolantTemp : 40|8@1+ (1,-40) [-40|210] "°C" Vector__XXX
 SG_ InCoolantTemp : 32|8@1+ (1,-40) [-40|210] "°C" Vector__XXX
 SG_ IgntV : 16|16@1+ (0.01,0) [0|642.55] "V" Vector__XXX
 SG_ BusV : 0|16@1+ (0.05,0) [0|3212.75] "V" Vector__XXX

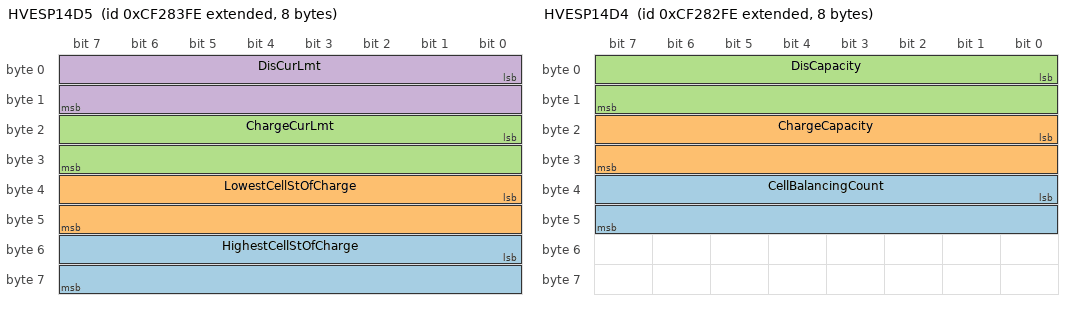
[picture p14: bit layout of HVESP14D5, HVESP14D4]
BO_ 2364703742 HVESP14D5: 8 Vector__XXX
 SG_ HighestCellStOfCharge : 48|16@1+ (0.0015625,0) [0|100.3984375] "%" Vector__XXX
 SG_ LowestCellStOfCharge : 32|16@1+ (0.0015625,0) [0|100.3984375] "%" Vector__XXX
 SG_ ChargeCurLmt : 16|16@1+ (0.05,-1600) [0|1612.75] "A" Vector__XXX
 SG_ DisCurLmt : 0|16@1+ (0.05,-1600) [-1600|0] "A" Vector__XXX

BO_ 2364703486 HVESP14D4: 8 Vector__XXX
 SG_ CellBalancingCount : 32|16@1+ (1,0) [0|64255] "" Vector__XXX
 SG_ ChargeCapacity : 16|16@1+ (0.01,0) [0|642.55] "Ah" Vector__XXX
 SG_ DisCapacity : 0|16@1+ (0.01,0) [0|642.55] "Ah" Vector__XXX

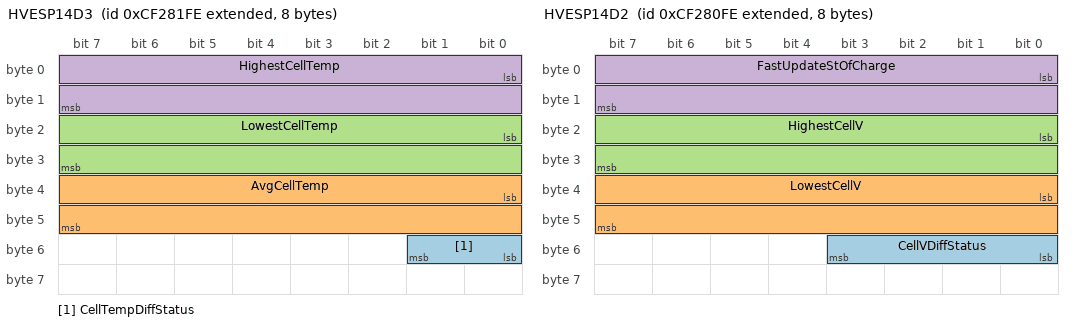
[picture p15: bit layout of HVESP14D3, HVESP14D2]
BO_ 2364703230 HVESP14D3: 8 Vector__XXX
 SG_ CellTempDiffStatus : 48|2@1+ (1,0) [0|3] "" Vector__XXX
 SG_ AvgCellTemp : 32|16@1+ (0.03125,-273) [-273|1734.96875] "°C" Vector__XXX
 SG_ LowestCellTemp : 16|16@1+ (0.03125,-273) [-273|1734.96875] "°C" Vector__XXX
 SG_ HighestCellTemp : 0|16@1+ (0.03125,-273) [-273|1734.96875] "°C" Vector__XXX

BO_ 2364702974 HVESP14D2: 8 Vector__XXX
 SG_ CellVDiffStatus : 48|4@1+ (1,0) [0|15] "" Vector__XXX
 SG_ LowestCellV : 32|16@1+ (0.001,0) [0|64.255] "V" Vector__XXX
 SG_ HighestCellV : 16|16@1+ (0.001,0) [0|64.255] "V" Vector__XXX
 SG_ FastUpdateStOfCharge : 0|16@1+ (0.0015625,0) [0|100.3984375] "%" Vector__XXX

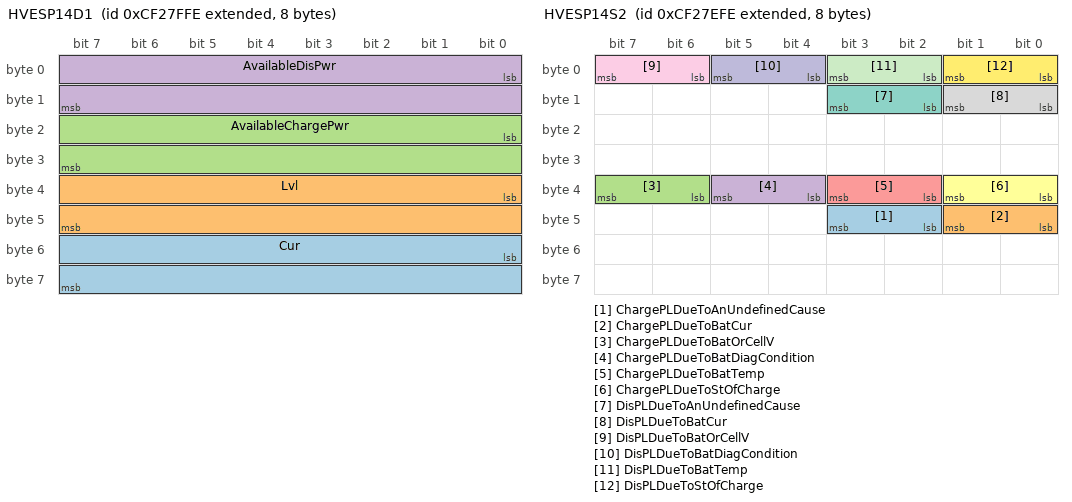
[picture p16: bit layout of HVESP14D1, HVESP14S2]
BO_ 2364702718 HVESP14D1: 8 Vector__XXX
 SG_ Cur : 48|16@1+ (0.05,-1600) [-1600|1612.75] "A" Vector__XXX
 SG_ Lvl : 32|16@1+ (0.05,0) [0|3212.75] "V" Vector__XXX
 SG_ AvailableChargePwr : 16|16@1+ (0.05,0) [0|3212.75] "kW" Vector__XXX
 SG_ AvailableDisPwr : 0|16@1+ (0.05,0) [0|3212.75] "kW" Vector__XXX

BO_ 2364702462 HVESP14S2: 8 Vector__XXX
 SG_ ChargePLDueToAnUndefinedCause : 42|2@1+ (1,0) [0|3] "" Vector__XXX
 SG_ ChargePLDueToBatCur : 40|2@1+ (1,0) [0|3] "" Vector__XXX
 SG_ ChargePLDueToBatOrCellV : 38|2@1+ (1,0) [0|3] "" Vector__XXX
 SG_ ChargePLDueToBatDiagCondition : 36|2@1+ (1,0) [0|3] "" Vector__XXX
 SG_ ChargePLDueToBatTemp : 34|2@1+ (1,0) [0|3] "" Vector__XXX
 SG_ ChargePLDueToStOfCharge : 32|2@1+ (1,0) [0|3] "" Vector__XXX
 SG_ DisPLDueToAnUndefinedCause : 10|2@1+ (1,0) [0|3] "" Vector__XXX
 SG_ DisPLDueToBatCur : 8|2@1+ (1,0) [0|3] "" Vector__XXX
 SG_ DisPLDueToBatOrCellV : 6|2@1+ (1,0) [0|3] "" Vector__XXX
 SG_ DisPLDueToBatDiagCondition : 4|2@1+ (1,0) [0|3] "" Vector__XXX
 SG_ DisPLDueToBatTemp : 2|2@1+ (1,0) [0|3] "" Vector__XXX
 SG_ DisPLDueToStOfCharge : 0|2@1+ (1,0) [0|3] "" Vector__XXX

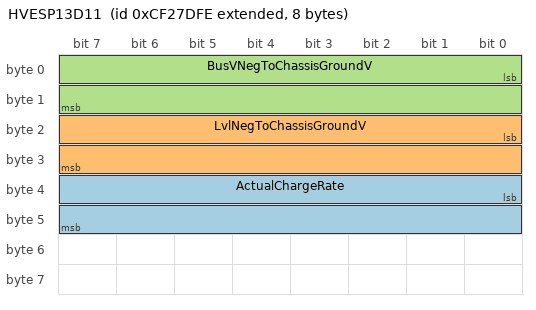
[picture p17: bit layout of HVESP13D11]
BO_ 2364702206 HVESP13D11: 8 Vector__XXX
 SG_ ActualChargeRate : 32|16@1+ (0.05,0) [0|3212.75] "kW" Vector__XXX
 SG_ LvlNegToChassisGroundV : 16|16@1+ (0.05,0) [0|3212.75] "V" Vector__XXX
 SG_ BusVNegToChassisGroundV : 0|16@1+ (0.05,0) [0|3212.75] "V" Vector__XXX

CM_ BO_ 2364712446 "High Voltage Energy Storage Pack 16 Module Status 1
Module Status message 1 for High Voltage Energy Storage Pack 16.";
CM_ SG_ 2364712446 Module32OperationalStatus "Operational Status of Module 32 in this High Voltage Energy Storage Pack Instance.  Not Operational is used when the module is initializing or not able to function (e.g. internal module level monitors have failed).  Operational indicates that the ...";
CM_ SG_ 2364712446 Module31OperationalStatus "Operational Status of Module 31 in this High Voltage Energy Storage Pack Instance.  Not Operational is used when the module is initializing or not able to function (e.g. internal module level monitors have failed).  Operational indicates that the ...";
CM_ SG_ 2364712446 Module30OperationalStatus "Operational Status of Module 30 in this High Voltage Energy Storage Pack Instance.  Not Operational is used when the module is initializing or not able to function (e.g. internal module level monitors have failed).  Operational indicates that the ...";
CM_ SG_ 2364712446 Module29OperationalStatus "Operational Status of Module 29 in this High Voltage Energy Storage Pack Instance.  Not Operational is used when the module is initializing or not able to function (e.g. internal module level monitors have failed).  Operational indicates that the ...";
CM_ SG_ 2364712446 Module28OperationalStatus "Operational Status of Module 28 in this High Voltage Energy Storage Pack Instance.  Not Operational is used when the module is initializing or not able to function (e.g. internal module level monitors have failed).  Operational indicates that the ...";
CM_ SG_ 2364712446 Module27OperationalStatus "Operational Status of Module 27 in this High Voltage Energy Storage Pack Instance.  Not Operational is used when the module is initializing or not able to function (e.g. internal module level monitors have failed).  Operational indicates that the ...";
CM_ SG_ 2364712446 Module26OperationalStatus "Operational Status of Module 26 in this High Voltage Energy Storage Pack Instance.  Not Operational is used when the module is initializing or not able to function (e.g. internal module level monitors have failed).  Operational indicates that the ...";
CM_ SG_ 2364712446 Module25OperationalStatus "Operational Status of Module 25 in this High Voltage Energy Storage Pack Instance.  Not Operational is used when the module is initializing or not able to function (e.g. internal module level monitors have failed).  Operational indicates that the ...";
CM_ SG_ 2364712446 Module24OperationalStatus "Operational Status of Module 24 in this High Voltage Energy Storage Pack Instance.  Not Operational is used when the module is initializing or not able to function (e.g. internal module level monitors have failed).  Operational indicates that the ...";
CM_ SG_ 2364712446 Module23OperationalStatus "Operational Status of Module 23 in this High Voltage Energy Storage Pack Instance.  Not Operational is used when the module is initializing or not able to function (e.g. internal module level monitors have failed).  Operational indicates that the ...";
CM_ SG_ 2364712446 Module22OperationalStatus "Operational Status of Module 22 in this High Voltage Energy Storage Pack Instance.  Not Operational is used when the module is initializing or not able to function (e.g. internal module level monitors have failed).  Operational indicates that the ...";
CM_ SG_ 2364712446 Module21OperationalStatus "Operational Status of Module 21 in this High Voltage Energy Storage Pack Instance.  Not Operational is used when the module is initializing or not able to function (e.g. internal module level monitors have failed).  Operational indicates that the ...";
CM_ SG_ 2364712446 Module20OperationalStatus "Operational Status of Module 20 in this High Voltage Energy Storage Pack Instance.  Not Operational is used when the module is initializing or not able to function (e.g. internal module level monitors have failed).  Operational indicates that the ...";
CM_ SG_ 2364712446 Module19OperationalStatus "Operational Status of Module 19 in this High Voltage Energy Storage Pack Instance.  Not Operational is used when the module is initializing or not able to function (e.g. internal module level monitors have failed).  Operational indicates that the ...";
CM_ SG_ 2364712446 Module18OperationalStatus "Operational Status of Module 18 in this High Voltage Energy Storage Pack Instance.  Not Operational is used when the module is initializing or not able to function (e.g. internal module level monitors have failed).  Operational indicates that the ...";
CM_ SG_ 2364712446 Module17OperationalStatus "Operational Status of Module 17 in this High Voltage Energy Storage Pack Instance.  Not Operational is used when the module is initializing or not able to function (e.g. internal module level monitors have failed).  Operational indicates that the ...";
CM_ SG_ 2364712446 Module16OperationalStatus "Operational Status of Module 16 in this High Voltage Energy Storage Pack Instance.  Not Operational is used when the module is initializing or not able to function (e.g. internal module level monitors have failed).  Operational indicates that the ...";
CM_ SG_ 2364712446 Module15OperationalStatus "Operational Status of Module 15 in this High Voltage Energy Storage Pack Instance.  Not Operational is used when the module is initializing or not able to function (e.g. internal module level monitors have failed).  Operational indicates that the ...";
CM_ SG_ 2364712446 Module14OperationalStatus "Operational Status of Module 14 in this High Voltage Energy Storage Pack Instance.  Not Operational is used when the module is initializing or not able to function (e.g. internal module level monitors have failed).  Operational indicates that the ...";
CM_ SG_ 2364712446 Module13OperationalStatus "Operational Status of Module 13 in this High Voltage Energy Storage Pack Instance.  Not Operational is used when the module is initializing or not able to function (e.g. internal module level monitors have failed).  Operational indicates that the ...";
CM_ SG_ 2364712446 Module12OperationalStatus "Operational Status of Module 12 in this High Voltage Energy Storage Pack Instance.  Not Operational is used when the module is initializing or not able to function (e.g. internal module level monitors have failed).  Operational indicates that the ...";
CM_ SG_ 2364712446 Module11OperationalStatus "Operational Status of Module 11 in this High Voltage Energy Storage Pack Instance.  Not Operational is used when the module is initializing or not able to function (e.g. internal module level monitors have failed).  Operational indicates that the ...";
CM_ SG_ 2364712446 Module10OperationalStatus "Operational Status of Module 10 in this High Voltage Energy Storage Pack Instance.  Not Operational is used when the module is initializing or not able to function (e.g. internal module level monitors have failed).  Operational indicates that the ...";
CM_ SG_ 2364712446 Module9OperationalStatus "Operational Status of Module 9 in this High Voltage Energy Storage Pack Instance.  Not Operational is used when the module is initializing or not able to function (e.g. internal module level monitors have failed).  Operational indicates that the ...";
CM_ SG_ 2364712446 Module8OperationalStatus "Operational Status of Module 8 in this High Voltage Energy Storage Pack Instance.  Not Operational is used when the module is initializing or not able to function (e.g. internal module level monitors have failed).  Operational indicates that the ...";
CM_ SG_ 2364712446 Module7OperationalStatus "Operational Status of Module 7 in this High Voltage Energy Storage Pack Instance.  Not Operational is used when the module is initializing or not able to function (e.g. internal module level monitors have failed).  Operational indicates that the ...";
CM_ SG_ 2364712446 Module6OperationalStatus "Operational Status of Module 6 in this High Voltage Energy Storage Pack Instance.  Not Operational is used when the module is initializing or not able to function (e.g. internal module level monitors have failed).  Operational indicates that the ...";
CM_ SG_ 2364712446 Module5OperationalStatus "Operational Status of Module 5 in this High Voltage Energy Storage Pack Instance.  Not Operational is used when the module is initializing or not able to function (e.g. internal module level monitors have failed).  Operational indicates that the ...";
CM_ SG_ 2364712446 Module4OperationalStatus "Operational Status of Module 4 in this High Voltage Energy Storage Pack Instance.  Not Operational is used when the module is initializing or not able to function (e.g. internal module level monitors have failed).  Operational indicates that the ...";
CM_ SG_ 2364712446 Module3OperationalStatus "Operational Status of Module 3 in this High Voltage Energy Storage Pack Instance.  Not Operational is used when the module is initializing or not able to function (e.g. internal module level monitors have failed).  Operational indicates that the ...";
CM_ SG_ 2364712446 Module2OperationalStatus "Operational Status of Module 2 in this High Voltage Energy Storage Pack Instance.  Not Operational is used when the module is initializing or not able to function (e.g. internal module level monitors have failed).  Operational indicates that the ...";
CM_ SG_ 2364712446 Module1OperationalStatus "Operational Status of Module 1 in this High Voltage Energy Storage Pack Instance.  Not Operational is used when the module is initializing or not able to function (e.g. internal module level monitors have failed).  Operational indicates that the ...";
CM_ BO_ 2364712190 "High Voltage Energy Storage Pack 16 Data 7
Data set 7 (electrical) for High Voltage Energy Storage Pack 16.";
CM_ SG_ 2364712190 MaxChargeVLmt "The maximum voltage level not to be exceeded while charging this High Voltage Energy Storage Pack instance. If this parameter is not supported, the maximum charge voltage should be limited to SPN 16113 (HVESP16 Recommended Maximum Operating ...";
CM_ SG_ 2364712190 ChargeEnergyCapacity "The amount of unused electrical energy storage available to be filled by charging this High Voltage Energy Storage Pack instance, i.e. “how much empty space is remaining in the tank”. See SPN 16015 (HVESP16 Charge Capacity) for Ampere-hours (Ah).
 ...";
CM_ SG_ 2364712190 DisEnergyCapacity "The amount of stored electrical energy in this High Voltage Energy Storage Pack instance that is available for use by the hybrid system, i.e. “how full is the tank”. See SPN 16014 (HVESP16 Discharge Capacity) for Ampere-hours (Ah).
This parameter ...";
CM_ BO_ 2364711934 "High Voltage Energy Storage Pack 16 Status 1
Status data set 1 for High Voltage Energy Storage Pack 16.";
CM_ SG_ 2364711934 Status1CRC "The CRC is defined as follows:
• Length: 8 bits
• Polynomial: x^8+x^5+x^3+x^2+x+1
• Initial Value: FFh
• Input Data Reflection: Not reflected
• Result Data Reflection: Not reflected
• XOR value: FFh
SAE makes no claim of the functional safety ...";
CM_ SG_ 2364711934 Status1Counter "The message counter is used to detect situations where the transmitting ECU malfunction repeats the same frame all the time. The receiver of the information may use the counter parameter to detect this situation. The transmitting device will ...";
CM_ SG_ 2364711934 OperationalStatus "Provides feedback on where this High Voltage Energy Storage Pack instance is in its operating spectrum, and includes feedback in response to the Operation Consent [i.e. SPN 15985 (HVESP16 Operation Consent)] and Power Down Command [i.e. SPN 15980 ...";
CM_ SG_ 2364711934 HVBusConnectionStatus "This parameter provides high level feedback on this High Voltage Energy Storage Pack instance high voltage bus connection. For specific contactor information, see SPN 16027 (HVESP16 High-Voltage Bus (Positive) Contactor State), SPN 16028 (HVESP16 ...";
CM_ SG_ 2364711934 InternalChargerStatus "Indicates that the charger in this HVES instance is on.  External chargers may use the External Energy Source Connection Status (SPN 7898) and related SPs.
This parameter is for one of multiple packs in an HVESS. If there is only one pack in the ...";
CM_ SG_ 2364711934 CellBalancingActive "Indicates whether or not the cells in this High Voltage Energy Storage Pack instance are currently being balanced.
This parameter is for one of multiple packs in an HVESS.  If there is only one pack in the system, the HVESS parameters should be ...";
CM_ SG_ 2364711934 CellBalanceStatus "Indicates whether or not the cells in this High Voltage Energy Storage Pack instance are balanced.
This parameter is for one of multiple packs in an HVESS.  If there is only one pack in the system, the HVESS parameters should be used. If there are ...";
CM_ SG_ 2364711934 StOfChargeStatus "Status of this High Voltage Energy Storage Pack instance State of Charge (SOC).  Note:  A given HVES controller may not support all of the states.
This parameter is for one of multiple packs in an HVESS.  If there is only one pack in the system, ...";
CM_ SG_ 2364711934 InertiaSwStatus "Switch indicating that an impact has been sensed by this High Voltage Energy Storage Pack instance. The impact indication may require action by another controller, or by this HVES instance itself.  For example, a controller may elect to take this ...";
CM_ SG_ 2364711934 HVILStatus "Status of the High Voltage Interlock Loop from the viewpoint of this High Voltage Energy Storage Pack instance.
This parameter is for one of multiple packs in an HVESS. If there is only one pack in the system, the HVESS parameters should be used ...";
CM_ SG_ 2364711934 HVBusPassiveIsolTestStatus "Status of the high-voltage bus electrical passive isolation test as performed by this High Voltage Energy Storage Pack instance.
This parameter is for one of multiple packs in an HVESS. If there is only one pack in the system, the HVESS parameters ...";
CM_ SG_ 2364711934 HVBusActiveIsolTestStatus "Status of the high-voltage bus electrical active isolation test as performed by this High Voltage Energy Storage Pack instance.
This parameter is for one of multiple packs in an HVESS. If there is only one pack in the system, the HVESS parameters ...";
CM_ SG_ 2364711934 CenterOfPackContactorSt "Position of the center high-voltage contactor. When this contactor is closed, the positive half of this High Voltage Energy Storage Pack instance is connected to the negative half. If a system controls the positive, negative, and center contactors ...";
CM_ SG_ 2364711934 HVBusPreChargeRelaySt "Position of the high-voltage bus contactor pre-charge relay.  When this relay is closed, this High Voltage Energy Storage Pack instance is bringing the high-voltage bus up to its operating level.
This parameter is for one of multiple packs in an ...";
CM_ SG_ 2364711934 HVBusDisconnectForewarning "Indicates that this High Voltage Energy Storage Pack instance is about to disconnect from the high voltage bus due to unacceptable conditions.
This parameter is for one of multiple packs in an HVESS. If there is only one pack in the system, the ...";
CM_ SG_ 2364711934 HVBusContactorSt16028 "Position of this High Voltage Energy Storage Pack instance negative side bus contactor. When this contactor is closed, the negative side of this HVES instance is connected to the negative side of the high-voltage bus. If a system controls the ...";
CM_ SG_ 2364711934 HVBusContactorSt "Position of this High Voltage Energy Storage Pack instance positive side bus contactor.  When this contactor is closed, the positive side of this HVES instance is connected to the positive side of the high-voltage bus.  In systems where all ...";
CM_ BO_ 2364711678 "High Voltage Energy Storage Pack 16 Data 6
Data set 6 (external or interface data) for High Voltage Energy Storage Pack 16.";
CM_ SG_ 2364711678 Temp "The temperature of this High Voltage Energy Storage Pack instance. The value may be determined from a unique sensor specifically for this purpose, or by aggregating various temperature sensor readings within the pack.
This parameter is for one of ...";
CM_ SG_ 2364711678 ETemp "The temperature of the electronics or control modules in this High Voltage Energy Storage Pack instance.  If there are multiple temperature sensors then this parameter would be set to the maximum sensor reading.
This parameter is for one of ...";
CM_ SG_ 2364711678 OutCoolantTemp "The temperature of liquid coolant as it exits this High Voltage Energy Storage Pack instance.
This parameter is for one of multiple packs in an HVESS.  If there is only one pack in the system, the HVESS parameters should be used. If there are ...";
CM_ SG_ 2364711678 InCoolantTemp "The temperature of liquid coolant as it enters this High Voltage Energy Storage Pack instance.
This parameter is for one of multiple packs in an HVESS.  If there is only one pack in the system, the HVESS parameters should be used. If there are ...";
CM_ SG_ 2364711678 IgntV "The voltage level at the ignition input of this High Voltage Energy Storage Pack controller.
This parameter is for one of multiple packs in an HVESS.  If there is only one pack in the system, the HVESS parameters should be used.  If there are ...";
CM_ SG_ 2364711678 BusV "The voltage level of the high voltage bus, as measured by this High Voltage Energy Storage Pack instance on the bus side (not the battery side) of its contactors.
This parameter is for one of multiple packs in an HVESS.  If there is only one pack ...";
CM_ BO_ 2364711422 "High Voltage Energy Storage Pack 16 Data 5
Data set 5 (electrical data) for High Voltage Energy Storage Pack 16.";
CM_ SG_ 2364711422 HighestCellStOfCharge "Indicates the state of charge of the highest-charged cell in this High Voltage Energy Storage Pack instance. 0% means no charge remaining, 100% means the cell is fully charged. If a single state of charge value covers more than one cell, the value ...";
CM_ SG_ 2364711422 LowestCellStOfCharge "Indicates the state of charge of the lowest-charged cell in this High Voltage Energy Storage Pack instance. 0% means no charge remaining, 100% means the cell is fully charged. If a single state of charge value covers more than one cell, the value in ...";
CM_ SG_ 2364711422 ChargeCurLmt "The maximum instantaneous current flow limit into this High Voltage Energy Storage Pack instance. This parameter is defined from the high voltage energy storage pack's point of view and should reflect the instantaneous capability of the pack.  The ...";
CM_ SG_ 2364711422 DisCurLmt "The maximum instantaneous current flow limit out of this High Voltage Energy Storage Pack instance. This parameter is defined from the high voltage energy storage pack's point of view and should reflect the instantaneous capability of the pack.  The ...";
CM_ BO_ 2364711166 "High Voltage Energy Storage Pack 16 Data 4
Data set 4 (electrical data) for High Voltage Energy Storage Pack 16.";
CM_ SG_ 2364711166 CellBalancingCount "The number of cells that are currently being balanced in this High Voltage Energy Storage Pack instance.
This parameter is for one of multiple packs in an HVESS.  If there is only one pack in the system, the HVESS parameters should be used.  If ...";
CM_ SG_ 2364711166 ChargeCapacity "The amount of unused electrical charge storage in this High Voltage Energy Storage Pack instance that is available to be filled by charging, i.e. “how much empty space is remaining in the tank”. See SPN 16045 (HVESP16 Charge Energy Capacity) for ...";
CM_ SG_ 2364711166 DisCapacity "The amount of stored electrical charge in this High Voltage Energy Storage Pack instance that is available for use by the hybrid system, i.e. “how full is the tank”. See SPN 16044 (HVESP16 Discharge Energy Capacity) for kilowatt-hours (kWh).
This ...";
CM_ BO_ 2364710910 "High Voltage Energy Storage Pack 16 Data 3
Data set 3 (thermal data) for High Voltage Energy Storage Pack 16.";
CM_ SG_ 2364710910 CellTempDiffStatus "Indicates whether or not the differential between the highest and lowest cell temperatures are within acceptable limits per this High Voltage Energy Storage Pack instance. The actual temperature differential can be calculated by subtracting SPN ...";
CM_ SG_ 2364710910 AvgCellTemp "The average temperature level of all cells in this High Voltage Energy Storage Pack instance.
This parameter is for one of multiple packs in an HVESS.  If there is only one pack in the system, the HVESS parameters should be used.  If there are ...";
CM_ SG_ 2364710910 LowestCellTemp "The lowest temperature level reported by any cell in this High Voltage Energy Storage Pack instance. If a single temperature sensor covers more than one cell, the value in this parameter is for the smallest group of cells measured. See SPN 16094 ...";
CM_ SG_ 2364710910 HighestCellTemp "The highest temperature level reported by any cell in this High Voltage Energy Storage Pack instance. If a single temperature sensor covers more than one cell, the value in this parameter is for the smallest group of cells measured. See SPN 16092 ...";
CM_ BO_ 2364710654 "High Voltage Energy Storage Pack 16 Data 2
Data set 2 (electrical data) for High Voltage Energy Storage Pack 16.";
CM_ SG_ 2364710654 CellVDiffStatus "Indicates whether or not the differential between the highest and lowest cell voltages are within acceptable limits, according to this High Voltage Energy Storage Pack instance. The actual voltage differential can be calculated by subtracting SPN ...";
CM_ SG_ 2364710654 LowestCellV "The lowest voltage level reported by any cell in this High Voltage Energy Storage Pack instance. If a single voltage sensor covers more than one cell, the value in this parameter is for the smallest group of cells measured. See SPN 16089 (HVESP16 ...";
CM_ SG_ 2364710654 HighestCellV "The highest voltage level reported by any cell in this High Voltage Energy Storage Pack instance. If a single voltage sensor covers more than one cell, the value in this parameter is for the smallest group of cells measured. See SPN 16087 (HVESP16 ...";
CM_ SG_ 2364710654 FastUpdateStOfCharge "Indicates this High Voltage Energy Storage Pack instance state of charge. 0% means no charge remaining, 100% means the system is fully charged in terms of physical limits of this energy storage pack instance. Acceptable state of charge upper and ...";
CM_ BO_ 2364710398 "High Voltage Energy Storage Pack 16 Data 1
Data set 1 (electrical data) for High Voltage Energy Storage Pack 16.";
CM_ SG_ 2364710398 Cur "The current in or out of this High Voltage Energy Storage Pack instance. This parameter should be synchronized with SPN 16004 (HVESP16 Voltage Level) such that a realized power value can be calculated. This parameter is defined from the high voltage ...";
CM_ SG_ 2364710398 Lvl "The voltage level of this High Voltage Energy Storage Pack instance. This parameter should be synchronized with SPN 16005 (HVESP16 Current) such that a realized power value can be calculated. If the HVES component physically contains the contactors ...";
CM_ SG_ 2364710398 AvailableChargePwr "The rate at which this High Voltage Energy Storage Pack instance can currently receive energy from a regenerative or recharging system.
This parameter is for one of multiple packs in an HVESS.  If there is only one pack in the system, the HVESS ...";
CM_ SG_ 2364710398 AvailableDisPwr "The rate at which this High Voltage Energy Storage Pack instance can currently provide energy for propulsion or other uses.
This parameter is for one of multiple packs in an HVESS.  If there is only one pack in the system, the HVESS parameters ...";
CM_ BO_ 2364710142 "High Voltage Energy Storage Pack 16 Status 2
Status data set 2 for High Voltage Energy Storage Pack 16.";
CM_ SG_ 2364710142 ChargePLDueToAnUndefinedCause "Indicates whether or not charge power of this HVES instance is being limited due to an undefined cause.
This parameter is for one of multiple packs in an HVESS.  If there is only one pack in the system, the HVESS parameters should be used. If there ...";
CM_ SG_ 2364710142 ChargePLDueToBatCur "Indicates whether or not charge power of this HVES instance is being limited due to battery current.
This parameter is for one of multiple packs in an HVESS.  If there is only one pack in the system, the HVESS parameters should be used. If there ...";
CM_ SG_ 2364710142 ChargePLDueToBatOrCellV "Indicates whether or not charge power of this HVES instance is being limited due to a battery or cell voltage level.
This parameter is for one of multiple packs in an HVESS.  If there is only one pack in the system, the HVESS parameters should be ...";
CM_ SG_ 2364710142 ChargePLDueToBatDiagCondition "Indicates whether or not charge power of this HVES instance is being limited due to a battery diagnostic condition.
This parameter is for one of multiple packs in an HVESS.  If there is only one pack in the system, the HVESS parameters should be ...";
CM_ SG_ 2364710142 ChargePLDueToBatTemp "Indicates whether or not charge power of this HVES instance is being limited due to battery temperature.
This parameter is for one of multiple packs in an HVESS.  If there is only one pack in the system, the HVESS parameters should be used. If ...";
CM_ SG_ 2364710142 ChargePLDueToStOfCharge "Indicates whether or not charge power of this HVES instance is being limited due to state of charge.
This parameter is for one of multiple packs in an HVESS.  If there is only one pack in the system, the HVESS parameters should be used. If there ...";
CM_ SG_ 2364710142 DisPLDueToAnUndefinedCause "Indicates whether or not discharge power of this HVES instance is being limited due to an undefined cause.
This parameter is for one of multiple packs in an HVESS.  If there is only one pack in the system, the HVESS parameters should be used. If ...";
CM_ SG_ 2364710142 DisPLDueToBatCur "Indicates whether or not discharge power of this HVES instance is being limited due to battery current.
This parameter is for one of multiple packs in an HVESS.  If there is only one pack in the system, the HVESS parameters should be used. If there ...";
CM_ SG_ 2364710142 DisPLDueToBatOrCellV "Indicates whether or not discharge power of this HVES instance is being limited due to a battery or cell voltage level.
This parameter is for one of multiple packs in an HVESS.  If there is only one pack in the system, the HVESS parameters should ...";
CM_ SG_ 2364710142 DisPLDueToBatDiagCondition "Indicates whether or not discharge power of this HVES instance is being limited due to a battery diagnostic condition.
This parameter is for one of multiple packs in an HVESS.  If there is only one pack in the system, the HVESS parameters should be ...";
CM_ SG_ 2364710142 DisPLDueToBatTemp "Indicates whether or not discharge power of this HVES instance is being limited due to battery temperature.
This parameter is for one of multiple packs in an HVESS.  If there is only one pack in the system, the HVESS parameters should be used. If ...";
CM_ SG_ 2364710142 DisPLDueToStOfCharge "Indicates whether or not discharge power of this HVES instance is being limited due to state of charge.
This parameter is for one of multiple packs in an HVESS.  If there is only one pack in the system, the HVESS parameters should be used. If there ...";
CM_ BO_ 2364709886 "High Voltage Energy Storage Pack 15 Data 11
Data set 11 (electrical data) for High Voltage Energy Storage Pack 15.";
CM_ SG_ 2364709886 ActualChargeRate "This signal represents the actual present charge rate of this High Voltage Energy Storage Pack instance.
This parameter is for one of multiple packs in an HVESS. If there is only one pack in the system, the HVESS parameters should be used. If there ...";
CM_ SG_ 2364709886 LvlNegToChassisGroundV "Voltage difference between the most negative terminal of the HVES battery and chassis measured at the battery side of any HVES contained output contactor.  This voltage may be used for system level monitoring of battery shorts to chassis within the ...";
CM_ SG_ 2364709886 BusVNegToChassisGroundV "Voltage difference between the most negative terminal of the HVES battery and chassis measured on the hybrid system bus side (not the battery side) of any HVES contained output contactor.  This voltage may be used for system level monitoring of ...";
CM_ BO_ 2364709630 "High Voltage Energy Storage Pack 15 Data 10
Data set 10 (electrical) for High Voltage Energy Storage Pack 15.";
CM_ SG_ 2364709630 HVBusPassiveIsolTestResults "The isolation resistance expressed in Ohms per Volt that resulted from the High-Voltage Bus Passive Isolation Test.
See SPN 15891 (HVESP15 High-Voltage Bus Passive Isolation Test Status) for test status and SPN 15840 (HVESP15 High-Voltage Bus ...";
CM_ SG_ 2364709630 HVBusActiveIsolTestResults "The isolation resistance expressed in Ohms per Volt that resulted from the High-Voltage Bus Active Isolation Test.
See SPN 15890 (HVESP15 High-Voltage Bus Active Isolation Test Status) for test status and SPN 15839 (HVESP15 High-Voltage Bus Active ...";
CM_ SG_ 2364709630 LowestCellStOfChargeCellNum "Identifies the location of SPN 15877 (HVESP15 Lowest Cell State of Charge) within SPN 15956 (HVESP15 Lowest Cell State of Charge Module Number).
This parameter is for one of multiple packs in an HVESS. If there is only one pack in the system, the ...";
CM_ SG_ 2364709630 LowestCellStOfChargeModuleNum "Identifies the location of the module containing SPN 15877 (HVESP15 Lowest Cell State of Charge).
This parameter is for one of multiple packs in an HVESS. If there is only one pack in the system, the HVESS parameters should be used. If there are ...";
CM_ SG_ 2364709630 HighestCellStOfChargeCellNum "Identifies the location of SPN 15878 (HVESP15 Highest Cell State of Charge) within SPN 15954 (HVESP15 Highest Cell State of Charge Module Number).
This parameter is for one of multiple packs in an HVESS. If there is only one pack in the system, the ...";
CM_ SG_ 2364709630 HighestCellStOfChargeModuleNum "Identifies the location of the module containing SPN 15878 (HVESP15 Highest Cell State of Charge).
This parameter is for one of multiple packs in an HVESS. If there is only one pack in the system, the HVESS parameters should be used. If there are ...";
CM_ BO_ 2364709374 "High Voltage Energy Storage Pack 15 Data 9
Data set 9 (thermal) for High Voltage Energy Storage Pack 15.";
CM_ SG_ 2364709374 Data9CRC "The CRC is defined as follows:
• Length: 8 bits
• Polynomial: x^8+x^5+x^3+x^2+x+1
• Initial Value: FFh
• Input Data Reflection: Not reflected
• Result Data Reflection: Not reflected
• XOR value: FFh
SAE makes no claim of the functional safety ...";
CM_ SG_ 2364709374 Data9Counter "The message counter is used to detect situations where the transmitting ECU malfunction repeats the same frame all the time. The receiver of the information may use the counter parameter to detect this situation. The transmitting device will ...";
CM_ SG_ 2364709374 Data9EmbeddedIntegritySupport "Indicates SPN 23018 (HVESP15 Data 9 CRC) and SPN 23017 (HVESP15 Data 9 Counter) are supported by the sender.
00b = Embedded CRC and Counter are supported by the sender
01b = Protection is supported using J1939-76 SHM
10b = Reserved
11b = CRC and ...";
CM_ SG_ 2364709374 HVESS15ThermalEventDetected "A sensor has detected the presence of a thermal event at or near High Voltage Energy Storage Pack instance.
00b = No Thermal Event Detected
01b = Thermal Event Detected
10b = Error
11b = Not available
This parameter is for one of multiple packs ...";
CM_ SG_ 2364709374 LowestCellTempCellNum "Identifies the location of SPN 15869 (HVESP15 Lowest Cell Temperature) within SPN 15952 (HVESP15 Lowest Cell Temperature Module Number).
This parameter is for one of multiple packs in an HVESS. If there is only one pack in the system, the HVESS ...";
CM_ SG_ 2364709374 LowestCellTempModuleNum "Identifies the location of the module containing SPN 15869 (HVESP15 Lowest Cell Temperature).
This parameter is for one of multiple packs in an HVESS. If there is only one pack in the system, the HVESS parameters should be used. If there are ...";
CM_ SG_ 2364709374 HighestCellTempCellNum "Identifies the location of SPN 15868 (HVESP15 Highest Cell Temperature) within SPN 15950 (HVESP15 Highest Cell Temperature Module Number).
This parameter is for one of multiple packs in an HVESS. If there is only one pack in the system, the HVESS ...";
CM_ SG_ 2364709374 HighestCellTempModuleNum "Identifies the location of the module containing SPN 15868 (HVESP15 Highest Cell Temperature).
This parameter is for one of multiple packs in an HVESS. If there is only one pack in the system, the HVESS parameters should be used. If there are ...";
CM_ BO_ 2364709118 "High Voltage Energy Storage Pack 15 Data 8
Data set 8 (electrical data) for High Voltage Energy Storage Pack 15.";
CM_ SG_ 2364709118 AvgCellV "The average cell voltage in this High Voltage Energy Storage Pack instance.
This parameter is for one of multiple packs in an HVESS.  If there is only one pack in the system, the HVESS parameters should be used. If there are multiple packs in the ...";
CM_ SG_ 2364709118 LowestCellVCellNum "Identifies the location of SPN 15866 (HVESP15 Lowest Cell Voltage) within SPN 15947 (HVESP15 Lowest Cell Voltage Module Number).
This parameter is for one of multiple packs in an HVESS. If there is only one pack in the system, the HVESS parameters ...";
CM_ SG_ 2364709118 LowestCellVModuleNum "Identifies the location of the module containing SPN 15866 (HVESP15 Lowest Cell Voltage).
This parameter is for one of multiple packs in an HVESS. If there is only one pack in the system, the HVESS parameters should be used. If there are multiple ...";
CM_ SG_ 2364709118 HighestCellVCellNum "Identifies the location of SPN 15865 (HVESP15 Highest Cell Voltage) within SPN 15945 (HVESP15 Highest Cell Voltage Module Number).
This parameter is for one of multiple packs in an HVESS. If there is only one pack in the system, the HVESS ...";
CM_ SG_ 2364709118 HighestCellVModuleNum "Identifies the location of the module containing SPN 15865 (HVESP15 Highest Cell Voltage).
This parameter is for one of multiple packs in an HVESS. If there is only one pack in the system, the HVESS parameters should be used. If there are multiple ...";
CM_ BO_ 2364708862 "High Voltage Energy Storage Pack 15 Thermal Management System Status 1
Collection of data the High Voltage Energy Storage Pack 15 Thermal Management System sends to the Hybrid Controller.";
CM_ SG_ 2364708862 TMSCoolantLvl "Indicates the coolant level in this HVES Thermal Management System (TMS).
This parameter is for one of multiple packs in an HVESS.  If there is only one pack in the system, the HVESS parameters should be used. If there are multiple packs in the ...";
CM_ SG_ 2364708862 TMSMode "Indicates the operating mode of the Thermal Management System.  The heat transfer medium may be (e.g. liquid or air).  The cooling system may be fans, liquid coolant, or a combination of mediums.  The system may include an air and/or liquid ...";
CM_ SG_ 2364708862 TMSHVILStatus "In multiple HVES configurations, this is the status of the High Voltage Interlock Loop from the viewpoint of this Thermal Management System.
00b = HVIL Closed
01b = HVIL Open
10b = Error
11b = Not Available
This parameter is for one of multiple ...";
CM_ SG_ 2364708862 TMSHtrStatus "The state of this High Voltage Energy Storage Pack heater
This parameter is for one of multiple packs in an HVESS.  If there is only one pack in the system, the HVESS parameters should be used. If there are multiple packs in the system, then both ...";
CM_ SG_ 2364708862 TMSRelHumidty "When this High Voltage Energy Storage Pack Thermal Management System is equipped with a relative humidity sensor, this is the  measured Relative Humidity.
This parameter is for one of multiple packs in an HVESS.  If there is only one pack in the ...";
CM_ SG_ 2364708862 TMSCompressorSpd "When this High Voltage Energy Storage Pack Thermal Management System is equipped with an active cooling system (e.g. air conditioner), this is the Compressor Speed.
This parameter is for one of multiple packs in an HVESS.  If there is only one pack ...";
CM_ SG_ 2364708862 TMSHVInputPwr "This is the high-voltage power consumed by this HVES Thermal Management System (TMS).
This parameter is for one of multiple packs in an HVESS.  If there is only one pack in the system, the HVESS parameters should be used. If there are multiple ...";
CM_ SG_ 2364708862 TMSSLIInputPwr "This is the low-voltage power consumed by this HVES Thermal Management System (TMS).
This parameter is for one of multiple packs in an HVESS.  If there is only one pack in the system, the HVESS parameters should be used.  If there are multiple ...";
CM_ BO_ 2364708606 "High Voltage Energy Storage Pack 15 Module Status 1
Module Status message 1 for High Voltage Energy Storage Pack 15.";
CM_ SG_ 2364708606 Module32OperationalStatus "Operational Status of Module 32 in this High Voltage Energy Storage Pack Instance.  Not Operational is used when the module is initializing or not able to function (e.g. internal module level monitors have failed).  Operational indicates that the ...";
CM_ SG_ 2364708606 Module31OperationalStatus "Operational Status of Module 31 in this High Voltage Energy Storage Pack Instance.  Not Operational is used when the module is initializing or not able to function (e.g. internal module level monitors have failed).  Operational indicates that the ...";
CM_ SG_ 2364708606 Module30OperationalStatus "Operational Status of Module 30 in this High Voltage Energy Storage Pack Instance.  Not Operational is used when the module is initializing or not able to function (e.g. internal module level monitors have failed).  Operational indicates that the ...";
CM_ SG_ 2364708606 Module29OperationalStatus "Operational Status of Module 29 in this High Voltage Energy Storage Pack Instance.  Not Operational is used when the module is initializing or not able to function (e.g. internal module level monitors have failed).  Operational indicates that the ...";
CM_ SG_ 2364708606 Module28OperationalStatus "Operational Status of Module 28 in this High Voltage Energy Storage Pack Instance.  Not Operational is used when the module is initializing or not able to function (e.g. internal module level monitors have failed).  Operational indicates that the ...";
CM_ SG_ 2364708606 Module27OperationalStatus "Operational Status of Module 27 in this High Voltage Energy Storage Pack Instance.  Not Operational is used when the module is initializing or not able to function (e.g. internal module level monitors have failed).  Operational indicates that the ...";
CM_ SG_ 2364708606 Module26OperationalStatus "Operational Status of Module 26 in this High Voltage Energy Storage Pack Instance.  Not Operational is used when the module is initializing or not able to function (e.g. internal module level monitors have failed).  Operational indicates that the ...";
CM_ SG_ 2364708606 Module25OperationalStatus "Operational Status of Module 25 in this High Voltage Energy Storage Pack Instance.  Not Operational is used when the module is initializing or not able to function (e.g. internal module level monitors have failed).  Operational indicates that the ...";
CM_ SG_ 2364708606 Module24OperationalStatus "Operational Status of Module 24 in this High Voltage Energy Storage Pack Instance.  Not Operational is used when the module is initializing or not able to function (e.g. internal module level monitors have failed).  Operational indicates that the ...";
CM_ SG_ 2364708606 Module23OperationalStatus "Operational Status of Module 23 in this High Voltage Energy Storage Pack Instance.  Not Operational is used when the module is initializing or not able to function (e.g. internal module level monitors have failed).  Operational indicates that the ...";
CM_ SG_ 2364708606 Module22OperationalStatus "Operational Status of Module 22 in this High Voltage Energy Storage Pack Instance.  Not Operational is used when the module is initializing or not able to function (e.g. internal module level monitors have failed).  Operational indicates that the ...";
CM_ SG_ 2364708606 Module21OperationalStatus "Operational Status of Module 21 in this High Voltage Energy Storage Pack Instance.  Not Operational is used when the module is initializing or not able to function (e.g. internal module level monitors have failed).  Operational indicates that the ...";
CM_ SG_ 2364708606 Module20OperationalStatus "Operational Status of Module 20 in this High Voltage Energy Storage Pack Instance.  Not Operational is used when the module is initializing or not able to function (e.g. internal module level monitors have failed).  Operational indicates that the ...";
CM_ SG_ 2364708606 Module19OperationalStatus "Operational Status of Module 19 in this High Voltage Energy Storage Pack Instance.  Not Operational is used when the module is initializing or not able to function (e.g. internal module level monitors have failed).  Operational indicates that the ...";
CM_ SG_ 2364708606 Module18OperationalStatus "Operational Status of Module 18 in this High Voltage Energy Storage Pack Instance.  Not Operational is used when the module is initializing or not able to function (e.g. internal module level monitors have failed).  Operational indicates that the ...";
CM_ SG_ 2364708606 Module17OperationalStatus "Operational Status of Module 17 in this High Voltage Energy Storage Pack Instance.  Not Operational is used when the module is initializing or not able to function (e.g. internal module level monitors have failed).  Operational indicates that the ...";
CM_ SG_ 2364708606 Module16OperationalStatus "Operational Status of Module 16 in this High Voltage Energy Storage Pack Instance.  Not Operational is used when the module is initializing or not able to function (e.g. internal module level monitors have failed).  Operational indicates that the ...";
CM_ SG_ 2364708606 Module15OperationalStatus "Operational Status of Module 15 in this High Voltage Energy Storage Pack Instance.  Not Operational is used when the module is initializing or not able to function (e.g. internal module level monitors have failed).  Operational indicates that the ...";
CM_ SG_ 2364708606 Module14OperationalStatus "Operational Status of Module 14 in this High Voltage Energy Storage Pack Instance.  Not Operational is used when the module is initializing or not able to function (e.g. internal module level monitors have failed).  Operational indicates that the ...";
CM_ SG_ 2364708606 Module13OperationalStatus "Operational Status of Module 13 in this High Voltage Energy Storage Pack Instance.  Not Operational is used when the module is initializing or not able to function (e.g. internal module level monitors have failed).  Operational indicates that the ...";
CM_ SG_ 2364708606 Module12OperationalStatus "Operational Status of Module 12 in this High Voltage Energy Storage Pack Instance.  Not Operational is used when the module is initializing or not able to function (e.g. internal module level monitors have failed).  Operational indicates that the ...";
CM_ SG_ 2364708606 Module11OperationalStatus "Operational Status of Module 11 in this High Voltage Energy Storage Pack Instance.  Not Operational is used when the module is initializing or not able to function (e.g. internal module level monitors have failed).  Operational indicates that the ...";
CM_ SG_ 2364708606 Module10OperationalStatus "Operational Status of Module 10 in this High Voltage Energy Storage Pack Instance.  Not Operational is used when the module is initializing or not able to function (e.g. internal module level monitors have failed).  Operational indicates that the ...";
CM_ SG_ 2364708606 Module9OperationalStatus "Operational Status of Module 9 in this High Voltage Energy Storage Pack Instance.  Not Operational is used when the module is initializing or not able to function (e.g. internal module level monitors have failed).  Operational indicates that the ...";
CM_ SG_ 2364708606 Module8OperationalStatus "Operational Status of Module 8 in this High Voltage Energy Storage Pack Instance.  Not Operational is used when the module is initializing or not able to function (e.g. internal module level monitors have failed).  Operational indicates that the ...";
CM_ SG_ 2364708606 Module7OperationalStatus "Operational Status of Module 7 in this High Voltage Energy Storage Pack Instance.  Not Operational is used when the module is initializing or not able to function (e.g. internal module level monitors have failed).  Operational indicates that the ...";
CM_ SG_ 2364708606 Module6OperationalStatus "Operational Status of Module 6 in this High Voltage Energy Storage Pack Instance.  Not Operational is used when the module is initializing or not able to function (e.g. internal module level monitors have failed).  Operational indicates that the ...";
CM_ SG_ 2364708606 Module5OperationalStatus "Operational Status of Module 5 in this High Voltage Energy Storage Pack Instance.  Not Operational is used when the module is initializing or not able to function (e.g. internal module level monitors have failed).  Operational indicates that the ...";
CM_ SG_ 2364708606 Module4OperationalStatus "Operational Status of Module 4 in this High Voltage Energy Storage Pack Instance.  Not Operational is used when the module is initializing or not able to function (e.g. internal module level monitors have failed).  Operational indicates that the ...";
CM_ SG_ 2364708606 Module3OperationalStatus "Operational Status of Module 3 in this High Voltage Energy Storage Pack Instance.  Not Operational is used when the module is initializing or not able to function (e.g. internal module level monitors have failed).  Operational indicates that the ...";
CM_ SG_ 2364708606 Module2OperationalStatus "Operational Status of Module 2 in this High Voltage Energy Storage Pack Instance.  Not Operational is used when the module is initializing or not able to function (e.g. internal module level monitors have failed).  Operational indicates that the ...";
CM_ SG_ 2364708606 Module1OperationalStatus "Operational Status of Module 1 in this High Voltage Energy Storage Pack Instance.  Not Operational is used when the module is initializing or not able to function (e.g. internal module level monitors have failed).  Operational indicates that the ...";
CM_ BO_ 2364708350 "High Voltage Energy Storage Pack 15 Data 7
Data set 7 (electrical) for High Voltage Energy Storage Pack 15.";
CM_ SG_ 2364708350 MaxChargeVLmt "The maximum voltage level not to be exceeded while charging this High Voltage Energy Storage Pack instance. If this parameter is not supported, the maximum charge voltage should be limited to SPN 15971 (HVESP15 Recommended Maximum Operating ...";
CM_ SG_ 2364708350 ChargeEnergyCapacity "The amount of unused electrical energy storage available to be filled by charging this High Voltage Energy Storage Pack instance, i.e. “how much empty space is remaining in the tank”. See SPN 15873 (HVESP15 Charge Capacity) for Ampere-hours (Ah).
 ...";
CM_ SG_ 2364708350 DisEnergyCapacity "The amount of stored electrical energy in this High Voltage Energy Storage Pack instance that is available for use by the hybrid system, i.e. “how full is the tank”. See SPN 15872 (HVESP15 Discharge Capacity) for Ampere-hours (Ah).
This parameter ...";
CM_ BO_ 2364708094 "High Voltage Energy Storage Pack 15 Status 1
Status data set 1 for High Voltage Energy Storage Pack 15.";
CM_ SG_ 2364708094 Status1CRC "The CRC is defined as follows:
• Length: 8 bits
• Polynomial: x^8+x^5+x^3+x^2+x+1
• Initial Value: FFh
• Input Data Reflection: Not reflected
• Result Data Reflection: Not reflected
• XOR value: FFh
SAE makes no claim of the functional safety ...";
CM_ SG_ 2364708094 Status1Counter "The message counter is used to detect situations where the transmitting ECU malfunction repeats the same frame all the time. The receiver of the information may use the counter parameter to detect this situation. The transmitting device will ...";
CM_ SG_ 2364708094 OperationalStatus "Provides feedback on where this High Voltage Energy Storage Pack instance is in its operating spectrum, and includes feedback in response to the Operation Consent [i.e. SPN 15843 (HVESP15 Operation Consent)] and Power Down Command [i.e. SPN 15838 ...";
CM_ SG_ 2364708094 HVBusConnectionStatus "This parameter provides high level feedback on this High Voltage Energy Storage Pack instance high voltage bus connection. For specific contactor information, see SPN 15885 (HVESP15 High-Voltage Bus (Positive) Contactor State), SPN 15886 (HVESP15 ...";
CM_ SG_ 2364708094 InternalChargerStatus "Indicates that the charger in this HVES instance is on.  External chargers may use the External Energy Source Connection Status (SPN 7898) and related SPs.
This parameter is for one of multiple packs in an HVESS. If there is only one pack in the ...";
CM_ SG_ 2364708094 CellBalancingActive "Indicates whether or not the cells in this High Voltage Energy Storage Pack instance are currently being balanced.
This parameter is for one of multiple packs in an HVESS.  If there is only one pack in the system, the HVESS parameters should be ...";
CM_ SG_ 2364708094 CellBalanceStatus "Indicates whether or not the cells in this High Voltage Energy Storage Pack instance are balanced.
This parameter is for one of multiple packs in an HVESS.  If there is only one pack in the system, the HVESS parameters should be used. If there are ...";
CM_ SG_ 2364708094 StOfChargeStatus "Status of this High Voltage Energy Storage Pack instance State of Charge (SOC).  Note:  A given HVES controller may not support all of the states.
This parameter is for one of multiple packs in an HVESS.  If there is only one pack in the system, ...";
CM_ SG_ 2364708094 InertiaSwStatus "Switch indicating that an impact has been sensed by this High Voltage Energy Storage Pack instance. The impact indication may require action by another controller, or by this HVES instance itself.  For example, a controller may elect to take this ...";
CM_ SG_ 2364708094 HVILStatus "Status of the High Voltage Interlock Loop from the viewpoint of this High Voltage Energy Storage Pack instance.
This parameter is for one of multiple packs in an HVESS. If there is only one pack in the system, the HVESS parameters should be used ...";
CM_ SG_ 2364708094 HVBusPassiveIsolTestStatus "Status of the high-voltage bus electrical passive isolation test as performed by this High Voltage Energy Storage Pack instance.
This parameter is for one of multiple packs in an HVESS. If there is only one pack in the system, the HVESS parameters ...";
CM_ SG_ 2364708094 HVBusActiveIsolTestStatus "Status of the high-voltage bus electrical active isolation test as performed by this High Voltage Energy Storage Pack instance.
This parameter is for one of multiple packs in an HVESS. If there is only one pack in the system, the HVESS parameters ...";
CM_ SG_ 2364708094 CenterOfPackContactorSt "Position of the center high-voltage contactor. When this contactor is closed, the positive half of this High Voltage Energy Storage Pack instance is connected to the negative half. If a system controls the positive, negative, and center contactors ...";
CM_ SG_ 2364708094 HVBusPreChargeRelaySt "Position of the high-voltage bus contactor pre-charge relay.  When this relay is closed, this High Voltage Energy Storage Pack instance is bringing the high-voltage bus up to its operating level.
This parameter is for one of multiple packs in an ...";
CM_ SG_ 2364708094 HVBusDisconnectForewarning "Indicates that this High Voltage Energy Storage Pack instance is about to disconnect from the high voltage bus due to unacceptable conditions.
This parameter is for one of multiple packs in an HVESS. If there is only one pack in the system, the ...";
CM_ SG_ 2364708094 HVBusContactorSt15886 "Position of this High Voltage Energy Storage Pack instance negative side bus contactor. When this contactor is closed, the negative side of this HVES instance is connected to the negative side of the high-voltage bus. If a system controls the ...";
CM_ SG_ 2364708094 HVBusContactorSt "Position of this High Voltage Energy Storage Pack instance positive side bus contactor.  When this contactor is closed, the positive side of this HVES instance is connected to the positive side of the high-voltage bus.  In systems where all ...";
CM_ BO_ 2364707838 "High Voltage Energy Storage Pack 15 Data 6
Data set 6 (external or interface data) for High Voltage Energy Storage Pack 15.";
CM_ SG_ 2364707838 Temp "The temperature of this High Voltage Energy Storage Pack instance. The value may be determined from a unique sensor specifically for this purpose, or by aggregating various temperature sensor readings within the pack.
This parameter is for one of ...";
CM_ SG_ 2364707838 ETemp "The temperature of the electronics or control modules in this High Voltage Energy Storage Pack instance.  If there are multiple temperature sensors then this parameter would be set to the maximum sensor reading.
This parameter is for one of ...";
CM_ SG_ 2364707838 OutCoolantTemp "The temperature of liquid coolant as it exits this High Voltage Energy Storage Pack instance.
This parameter is for one of multiple packs in an HVESS.  If there is only one pack in the system, the HVESS parameters should be used. If there are ...";
CM_ SG_ 2364707838 InCoolantTemp "The temperature of liquid coolant as it enters this High Voltage Energy Storage Pack instance.
This parameter is for one of multiple packs in an HVESS.  If there is only one pack in the system, the HVESS parameters should be used. If there are ...";
CM_ SG_ 2364707838 IgntV "The voltage level at the ignition input of this High Voltage Energy Storage Pack controller.
This parameter is for one of multiple packs in an HVESS.  If there is only one pack in the system, the HVESS parameters should be used.  If there are ...";
CM_ SG_ 2364707838 BusV "The voltage level of the high voltage bus, as measured by this High Voltage Energy Storage Pack instance on the bus side (not the battery side) of its contactors.
This parameter is for one of multiple packs in an HVESS.  If there is only one pack ...";
CM_ BO_ 2364707582 "High Voltage Energy Storage Pack 15 Data 5
Data set 5 (electrical data) for High Voltage Energy Storage Pack 15.";
CM_ SG_ 2364707582 HighestCellStOfCharge "Indicates the state of charge of the highest-charged cell in this High Voltage Energy Storage Pack instance. 0% means no charge remaining, 100% means the cell is fully charged. If a single state of charge value covers more than one cell, the value ...";
CM_ SG_ 2364707582 LowestCellStOfCharge "Indicates the state of charge of the lowest-charged cell in this High Voltage Energy Storage Pack instance. 0% means no charge remaining, 100% means the cell is fully charged. If a single state of charge value covers more than one cell, the value in ...";
CM_ SG_ 2364707582 ChargeCurLmt "The maximum instantaneous current flow limit into this High Voltage Energy Storage Pack instance. This parameter is defined from the high voltage energy storage pack's point of view and should reflect the instantaneous capability of the pack.  The ...";
CM_ SG_ 2364707582 DisCurLmt "The maximum instantaneous current flow limit out of this High Voltage Energy Storage Pack instance. This parameter is defined from the high voltage energy storage pack's point of view and should reflect the instantaneous capability of the pack.  The ...";
CM_ BO_ 2364707326 "High Voltage Energy Storage Pack 15 Data 4
Data set 4 (electrical data) for High Voltage Energy Storage Pack 15.";
CM_ SG_ 2364707326 CellBalancingCount "The number of cells that are currently being balanced in this High Voltage Energy Storage Pack instance.
This parameter is for one of multiple packs in an HVESS.  If there is only one pack in the system, the HVESS parameters should be used.  If ...";
CM_ SG_ 2364707326 ChargeCapacity "The amount of unused electrical charge storage in this High Voltage Energy Storage Pack instance that is available to be filled by charging, i.e. “how much empty space is remaining in the tank”. See SPN 15903 (HVESP15 Charge Energy Capacity) for ...";
CM_ SG_ 2364707326 DisCapacity "The amount of stored electrical charge in this High Voltage Energy Storage Pack instance that is available for use by the hybrid system, i.e. “how full is the tank”. See SPN 15902 (HVESP15 Discharge Energy Capacity) for kilowatt-hours (kWh).
This ...";
CM_ BO_ 2364707070 "High Voltage Energy Storage Pack 15 Data 3
Data set 3 (thermal data) for High Voltage Energy Storage Pack 15.";
CM_ SG_ 2364707070 CellTempDiffStatus "Indicates whether or not the differential between the highest and lowest cell temperatures are within acceptable limits per this High Voltage Energy Storage Pack instance. The actual temperature differential can be calculated by subtracting SPN ...";
CM_ SG_ 2364707070 AvgCellTemp "The average temperature level of all cells in this High Voltage Energy Storage Pack instance.
This parameter is for one of multiple packs in an HVESS.  If there is only one pack in the system, the HVESS parameters should be used.  If there are ...";
CM_ SG_ 2364707070 LowestCellTemp "The lowest temperature level reported by any cell in this High Voltage Energy Storage Pack instance. If a single temperature sensor covers more than one cell, the value in this parameter is for the smallest group of cells measured. See SPN 15952 ...";
CM_ SG_ 2364707070 HighestCellTemp "The highest temperature level reported by any cell in this High Voltage Energy Storage Pack instance. If a single temperature sensor covers more than one cell, the value in this parameter is for the smallest group of cells measured. See SPN 15950 ...";
CM_ BO_ 2364706814 "High Voltage Energy Storage Pack 15 Data 2
Data set 2 (electrical data) for High Voltage Energy Storage Pack 15.";
CM_ SG_ 2364706814 CellVDiffStatus "Indicates whether or not the differential between the highest and lowest cell voltages are within acceptable limits, according to this High Voltage Energy Storage Pack instance. The actual voltage differential can be calculated by subtracting SPN ...";
CM_ SG_ 2364706814 LowestCellV "The lowest voltage level reported by any cell in this High Voltage Energy Storage Pack instance. If a single voltage sensor covers more than one cell, the value in this parameter is for the smallest group of cells measured. See SPN 15947 (HVESP15 ...";
CM_ SG_ 2364706814 HighestCellV "The highest voltage level reported by any cell in this High Voltage Energy Storage Pack instance. If a single voltage sensor covers more than one cell, the value in this parameter is for the smallest group of cells measured. See SPN 15945 (HVESP15 ...";
CM_ SG_ 2364706814 FastUpdateStOfCharge "Indicates this High Voltage Energy Storage Pack instance state of charge. 0% means no charge remaining, 100% means the system is fully charged in terms of physical limits of this energy storage pack instance. Acceptable state of charge upper and ...";
CM_ BO_ 2364706558 "High Voltage Energy Storage Pack 15 Data 1
Data set 1 (electrical data) for High Voltage Energy Storage Pack 15.";
CM_ SG_ 2364706558 Cur "The current in or out of this High Voltage Energy Storage Pack instance. This parameter should be synchronized with SPN 15862 (HVESP15 Voltage Level) such that a realized power value can be calculated. This parameter is defined from the high voltage ...";
CM_ SG_ 2364706558 Lvl "The voltage level of this High Voltage Energy Storage Pack instance. This parameter should be synchronized with SPN 15863 (HVESP15 Current) such that a realized power value can be calculated. If the HVES component physically contains the contactors ...";
CM_ SG_ 2364706558 AvailableChargePwr "The rate at which this High Voltage Energy Storage Pack instance can currently receive energy from a regenerative or recharging system.
This parameter is for one of multiple packs in an HVESS.  If there is only one pack in the system, the HVESS ...";
CM_ SG_ 2364706558 AvailableDisPwr "The rate at which this High Voltage Energy Storage Pack instance can currently provide energy for propulsion or other uses.
This parameter is for one of multiple packs in an HVESS.  If there is only one pack in the system, the HVESS parameters ...";
CM_ BO_ 2364706302 "High Voltage Energy Storage Pack 15 Status 2
Status data set 2 for High Voltage Energy Storage Pack 15.";
CM_ SG_ 2364706302 ChargePLDueToAnUndefinedCause "Indicates whether or not charge power of this HVES instance is being limited due to an undefined cause.
This parameter is for one of multiple packs in an HVESS.  If there is only one pack in the system, the HVESS parameters should be used. If there ...";
CM_ SG_ 2364706302 ChargePLDueToBatCur "Indicates whether or not charge power of this HVES instance is being limited due to battery current.
This parameter is for one of multiple packs in an HVESS.  If there is only one pack in the system, the HVESS parameters should be used. If there ...";
CM_ SG_ 2364706302 ChargePLDueToBatOrCellV "Indicates whether or not charge power of this HVES instance is being limited due to a battery or cell voltage level.
This parameter is for one of multiple packs in an HVESS.  If there is only one pack in the system, the HVESS parameters should be ...";
CM_ SG_ 2364706302 ChargePLDueToBatDiagCondition "Indicates whether or not charge power of this HVES instance is being limited due to a battery diagnostic condition.
This parameter is for one of multiple packs in an HVESS.  If there is only one pack in the system, the HVESS parameters should be ...";
CM_ SG_ 2364706302 ChargePLDueToBatTemp "Indicates whether or not charge power of this HVES instance is being limited due to battery temperature.
This parameter is for one of multiple packs in an HVESS.  If there is only one pack in the system, the HVESS parameters should be used. If ...";
CM_ SG_ 2364706302 ChargePLDueToStOfCharge "Indicates whether or not charge power of this HVES instance is being limited due to state of charge.
This parameter is for one of multiple packs in an HVESS.  If there is only one pack in the system, the HVESS parameters should be used. If there ...";
CM_ SG_ 2364706302 DisPLDueToAnUndefinedCause "Indicates whether or not discharge power of this HVES instance is being limited due to an undefined cause.
This parameter is for one of multiple packs in an HVESS.  If there is only one pack in the system, the HVESS parameters should be used. If ...";
CM_ SG_ 2364706302 DisPLDueToBatCur "Indicates whether or not discharge power of this HVES instance is being limited due to battery current.
This parameter is for one of multiple packs in an HVESS.  If there is only one pack in the system, the HVESS parameters should be used. If there ...";
CM_ SG_ 2364706302 DisPLDueToBatOrCellV "Indicates whether or not discharge power of this HVES instance is being limited due to a battery or cell voltage level.
This parameter is for one of multiple packs in an HVESS.  If there is only one pack in the system, the HVESS parameters should ...";
CM_ SG_ 2364706302 DisPLDueToBatDiagCondition "Indicates whether or not discharge power of this HVES instance is being limited due to a battery diagnostic condition.
This parameter is for one of multiple packs in an HVESS.  If there is only one pack in the system, the HVESS parameters should be ...";
CM_ SG_ 2364706302 DisPLDueToBatTemp "Indicates whether or not discharge power of this HVES instance is being limited due to battery temperature.
This parameter is for one of multiple packs in an HVESS.  If there is only one pack in the system, the HVESS parameters should be used. If ...";
CM_ SG_ 2364706302 DisPLDueToStOfCharge "Indicates whether or not discharge power of this HVES instance is being limited due to state of charge.
This parameter is for one of multiple packs in an HVESS.  If there is only one pack in the system, the HVESS parameters should be used. If there ...";
CM_ BO_ 2364706046 "High Voltage Energy Storage Pack 14 Data 11
Data set 11 (electrical data) for High Voltage Energy Storage Pack 14.";
CM_ SG_ 2364706046 ActualChargeRate "This signal represents the actual present charge rate of this High Voltage Energy Storage Pack instance.
This parameter is for one of multiple packs in an HVESS. If there is only one pack in the system, the HVESS parameters should be used. If there ...";
CM_ SG_ 2364706046 LvlNegToChassisGroundV "Voltage difference between the most negative terminal of the HVES battery and chassis measured at the battery side of any HVES contained output contactor.  This voltage may be used for system level monitoring of battery shorts to chassis within the ...";
CM_ SG_ 2364706046 BusVNegToChassisGroundV "Voltage difference between the most negative terminal of the HVES battery and chassis measured on the hybrid system bus side (not the battery side) of any HVES contained output contactor.  This voltage may be used for system level monitoring of ...";
CM_ BO_ 2364705790 "High Voltage Energy Storage Pack 14 Data 10
Data set 10 (electrical) for High Voltage Energy Storage Pack 14.";
CM_ SG_ 2364705790 HVBusPassiveIsolTestResults "The isolation resistance expressed in Ohms per Volt that resulted from the High-Voltage Bus Passive Isolation Test.
See SPN 15749 (HVESP14 High-Voltage Bus Passive Isolation Test Status) for test status and SPN 15698 (HVESP14 High-Voltage Bus ...";
CM_ SG_ 2364705790 HVBusActiveIsolTestResults "The isolation resistance expressed in Ohms per Volt that resulted from the High-Voltage Bus Active Isolation Test.
See SPN 15748 (HVESP14 High-Voltage Bus Active Isolation Test Status) for test status and SPN 15697 (HVESP14 High-Voltage Bus Active ...";
CM_ SG_ 2364705790 LowestCellStOfChargeCellNum "Identifies the location of SPN 15735 (HVESP14 Lowest Cell State of Charge) within SPN 15814 (HVESP14 Lowest Cell State of Charge Module Number).
This parameter is for one of multiple packs in an HVESS. If there is only one pack in the system, the ...";
CM_ SG_ 2364705790 LowestCellStOfChargeModuleNum "Identifies the location of the module containing SPN 15735 (HVESP14 Lowest Cell State of Charge).
This parameter is for one of multiple packs in an HVESS. If there is only one pack in the system, the HVESS parameters should be used. If there are ...";
CM_ SG_ 2364705790 HighestCellStOfChargeCellNum "Identifies the location of SPN 15736 (HVESP14 Highest Cell State of Charge) within SPN 15812 (HVESP14 Highest Cell State of Charge Module Number).
This parameter is for one of multiple packs in an HVESS. If there is only one pack in the system, the ...";
CM_ SG_ 2364705790 HighestCellStOfChargeModuleNum "Identifies the location of the module containing SPN 15736 (HVESP14 Highest Cell State of Charge).
This parameter is for one of multiple packs in an HVESS. If there is only one pack in the system, the HVESS parameters should be used. If there are ...";
CM_ BO_ 2364705534 "High Voltage Energy Storage Pack 14 Data 9
Data set 9 (thermal) for High Voltage Energy Storage Pack 14.";
CM_ SG_ 2364705534 Data9CRC "The CRC is defined as follows:
• Length: 8 bits
• Polynomial: x^8+x^5+x^3+x^2+x+1
• Initial Value: FFh
• Input Data Reflection: Not reflected
• Result Data Reflection: Not reflected
• XOR value: FFh
SAE makes no claim of the functional safety ...";
CM_ SG_ 2364705534 Data9Counter "The message counter is used to detect situations where the transmitting ECU malfunction repeats the same frame all the time. The receiver of the information may use the counter parameter to detect this situation. The transmitting device will ...";
CM_ SG_ 2364705534 Data9EmbeddedIntegritySupport "Indicates SPN 23015 (HVESP14 Data 9 CRC) and SPN 23014 (HVESP14 Data 9 Counter) are supported by the sender.
00b = Embedded CRC and Counter are supported by the sender
01b = Protection is supported using J1939-76 SHM
10b = Reserved
11b = CRC and ...";
CM_ SG_ 2364705534 HVESS14ThermalEventDetected "A sensor has detected the presence of a thermal event at or near High Voltage Energy Storage Pack instance.
00b = No Thermal Event Detected
01b = Thermal Event Detected
10b = Error
11b = Not available
This parameter is for one of multiple packs ...";
CM_ SG_ 2364705534 LowestCellTempCellNum "Identifies the location of SPN 15727 (HVESP14 Lowest Cell Temperature) within SPN 15810 (HVESP14 Lowest Cell Temperature Module Number).
This parameter is for one of multiple packs in an HVESS. If there is only one pack in the system, the HVESS ...";
CM_ SG_ 2364705534 LowestCellTempModuleNum "Identifies the location of the module containing SPN 15727 (HVESP14 Lowest Cell Temperature).
This parameter is for one of multiple packs in an HVESS. If there is only one pack in the system, the HVESS parameters should be used. If there are ...";
CM_ SG_ 2364705534 HighestCellTempCellNum "Identifies the location of SPN 15726 (HVESP14 Highest Cell Temperature) within SPN 15808 (HVESP14 Highest Cell Temperature Module Number).
This parameter is for one of multiple packs in an HVESS. If there is only one pack in the system, the HVESS ...";
CM_ SG_ 2364705534 HighestCellTempModuleNum "Identifies the location of the module containing SPN 15726 (HVESP14 Highest Cell Temperature).
This parameter is for one of multiple packs in an HVESS. If there is only one pack in the system, the HVESS parameters should be used. If there are ...";
CM_ BO_ 2364705278 "High Voltage Energy Storage Pack 14 Data 8
Data set 8 (electrical data) for High Voltage Energy Storage Pack 14.";
CM_ SG_ 2364705278 AvgCellV "The average cell voltage in this High Voltage Energy Storage Pack instance.
This parameter is for one of multiple packs in an HVESS.  If there is only one pack in the system, the HVESS parameters should be used. If there are multiple packs in the ...";
CM_ SG_ 2364705278 LowestCellVCellNum "Identifies the location of SPN 15724 (HVESP14 Lowest Cell Voltage) within SPN 15805 (HVESP14 Lowest Cell Voltage Module Number).
This parameter is for one of multiple packs in an HVESS. If there is only one pack in the system, the HVESS parameters ...";
CM_ SG_ 2364705278 LowestCellVModuleNum "Identifies the location of the module containing SPN 15724 (HVESP14 Lowest Cell Voltage).
This parameter is for one of multiple packs in an HVESS. If there is only one pack in the system, the HVESS parameters should be used. If there are multiple ...";
CM_ SG_ 2364705278 HighestCellVCellNum "Identifies the location of SPN 15723 (HVESP14 Highest Cell Voltage) within SPN 15803 (HVESP14 Highest Cell Voltage Module Number).
This parameter is for one of multiple packs in an HVESS. If there is only one pack in the system, the HVESS ...";
CM_ SG_ 2364705278 HighestCellVModuleNum "Identifies the location of the module containing SPN 15723 (HVESP14 Highest Cell Voltage).
This parameter is for one of multiple packs in an HVESS. If there is only one pack in the system, the HVESS parameters should be used. If there are multiple ...";
CM_ BO_ 2364705022 "High Voltage Energy Storage Pack 14 Thermal Management System Status 1
Collection of data the High Voltage Energy Storage Pack 14 Thermal Management System sends to the Hybrid Controller.";
CM_ SG_ 2364705022 TMSCoolantLvl "Indicates the coolant level in this HVES Thermal Management System (TMS).
This parameter is for one of multiple packs in an HVESS.  If there is only one pack in the system, the HVESS parameters should be used. If there are multiple packs in the ...";
CM_ SG_ 2364705022 TMSMode "Indicates the operating mode of the Thermal Management System.  The heat transfer medium may be (e.g. liquid or air).  The cooling system may be fans, liquid coolant, or a combination of mediums.  The system may include an air and/or liquid ...";
CM_ SG_ 2364705022 TMSHVILStatus "In multiple HVES configurations, this is the status of the High Voltage Interlock Loop from the viewpoint of this Thermal Management System.
00b = HVIL Closed
01b = HVIL Open
10b = Error
11b = Not Available
This parameter is for one of multiple ...";
CM_ SG_ 2364705022 TMSHtrStatus "The state of this High Voltage Energy Storage Pack heater
This parameter is for one of multiple packs in an HVESS.  If there is only one pack in the system, the HVESS parameters should be used. If there are multiple packs in the system, then both ...";
CM_ SG_ 2364705022 TMSRelHumidty "When this High Voltage Energy Storage Pack Thermal Management System is equipped with a relative humidity sensor, this is the  measured Relative Humidity.
This parameter is for one of multiple packs in an HVESS.  If there is only one pack in the ...";
CM_ SG_ 2364705022 TMSCompressorSpd "When this High Voltage Energy Storage Pack Thermal Management System is equipped with an active cooling system (e.g. air conditioner), this is the Compressor Speed.
This parameter is for one of multiple packs in an HVESS.  If there is only one pack ...";
CM_ SG_ 2364705022 TMSHVInputPwr "This is the high-voltage power consumed by this HVES Thermal Management System (TMS).
This parameter is for one of multiple packs in an HVESS.  If there is only one pack in the system, the HVESS parameters should be used. If there are multiple ...";
CM_ SG_ 2364705022 TMSSLIInputPwr "This is the low-voltage power consumed by this HVES Thermal Management System (TMS).
This parameter is for one of multiple packs in an HVESS.  If there is only one pack in the system, the HVESS parameters should be used.  If there are multiple ...";
CM_ BO_ 2364704766 "High Voltage Energy Storage Pack 14 Module Status 1
Module Status message 1 for High Voltage Energy Storage Pack 14.";
CM_ SG_ 2364704766 Module32OperationalStatus "Operational Status of Module 32 in this High Voltage Energy Storage Pack Instance.  Not Operational is used when the module is initializing or not able to function (e.g. internal module level monitors have failed).  Operational indicates that the ...";
CM_ SG_ 2364704766 Module31OperationalStatus "Operational Status of Module 31 in this High Voltage Energy Storage Pack Instance.  Not Operational is used when the module is initializing or not able to function (e.g. internal module level monitors have failed).  Operational indicates that the ...";
CM_ SG_ 2364704766 Module30OperationalStatus "Operational Status of Module 30 in this High Voltage Energy Storage Pack Instance.  Not Operational is used when the module is initializing or not able to function (e.g. internal module level monitors have failed).  Operational indicates that the ...";
CM_ SG_ 2364704766 Module29OperationalStatus "Operational Status of Module 29 in this High Voltage Energy Storage Pack Instance.  Not Operational is used when the module is initializing or not able to function (e.g. internal module level monitors have failed).  Operational indicates that the ...";
CM_ SG_ 2364704766 Module28OperationalStatus "Operational Status of Module 28 in this High Voltage Energy Storage Pack Instance.  Not Operational is used when the module is initializing or not able to function (e.g. internal module level monitors have failed).  Operational indicates that the ...";
CM_ SG_ 2364704766 Module27OperationalStatus "Operational Status of Module 27 in this High Voltage Energy Storage Pack Instance.  Not Operational is used when the module is initializing or not able to function (e.g. internal module level monitors have failed).  Operational indicates that the ...";
CM_ SG_ 2364704766 Module26OperationalStatus "Operational Status of Module 26 in this High Voltage Energy Storage Pack Instance.  Not Operational is used when the module is initializing or not able to function (e.g. internal module level monitors have failed).  Operational indicates that the ...";
CM_ SG_ 2364704766 Module25OperationalStatus "Operational Status of Module 25 in this High Voltage Energy Storage Pack Instance.  Not Operational is used when the module is initializing or not able to function (e.g. internal module level monitors have failed).  Operational indicates that the ...";
CM_ SG_ 2364704766 Module24OperationalStatus "Operational Status of Module 24 in this High Voltage Energy Storage Pack Instance.  Not Operational is used when the module is initializing or not able to function (e.g. internal module level monitors have failed).  Operational indicates that the ...";
CM_ SG_ 2364704766 Module23OperationalStatus "Operational Status of Module 23 in this High Voltage Energy Storage Pack Instance.  Not Operational is used when the module is initializing or not able to function (e.g. internal module level monitors have failed).  Operational indicates that the ...";
CM_ SG_ 2364704766 Module22OperationalStatus "Operational Status of Module 22 in this High Voltage Energy Storage Pack Instance.  Not Operational is used when the module is initializing or not able to function (e.g. internal module level monitors have failed).  Operational indicates that the ...";
CM_ SG_ 2364704766 Module21OperationalStatus "Operational Status of Module 21 in this High Voltage Energy Storage Pack Instance.  Not Operational is used when the module is initializing or not able to function (e.g. internal module level monitors have failed).  Operational indicates that the ...";
CM_ SG_ 2364704766 Module20OperationalStatus "Operational Status of Module 20 in this High Voltage Energy Storage Pack Instance.  Not Operational is used when the module is initializing or not able to function (e.g. internal module level monitors have failed).  Operational indicates that the ...";
CM_ SG_ 2364704766 Module19OperationalStatus "Operational Status of Module 19 in this High Voltage Energy Storage Pack Instance.  Not Operational is used when the module is initializing or not able to function (e.g. internal module level monitors have failed).  Operational indicates that the ...";
CM_ SG_ 2364704766 Module18OperationalStatus "Operational Status of Module 18 in this High Voltage Energy Storage Pack Instance.  Not Operational is used when the module is initializing or not able to function (e.g. internal module level monitors have failed).  Operational indicates that the ...";
CM_ SG_ 2364704766 Module17OperationalStatus "Operational Status of Module 17 in this High Voltage Energy Storage Pack Instance.  Not Operational is used when the module is initializing or not able to function (e.g. internal module level monitors have failed).  Operational indicates that the ...";
CM_ SG_ 2364704766 Module16OperationalStatus "Operational Status of Module 16 in this High Voltage Energy Storage Pack Instance.  Not Operational is used when the module is initializing or not able to function (e.g. internal module level monitors have failed).  Operational indicates that the ...";
CM_ SG_ 2364704766 Module15OperationalStatus "Operational Status of Module 15 in this High Voltage Energy Storage Pack Instance.  Not Operational is used when the module is initializing or not able to function (e.g. internal module level monitors have failed).  Operational indicates that the ...";
CM_ SG_ 2364704766 Module14OperationalStatus "Operational Status of Module 14 in this High Voltage Energy Storage Pack Instance.  Not Operational is used when the module is initializing or not able to function (e.g. internal module level monitors have failed).  Operational indicates that the ...";
CM_ SG_ 2364704766 Module13OperationalStatus "Operational Status of Module 13 in this High Voltage Energy Storage Pack Instance.  Not Operational is used when the module is initializing or not able to function (e.g. internal module level monitors have failed).  Operational indicates that the ...";
CM_ SG_ 2364704766 Module12OperationalStatus "Operational Status of Module 12 in this High Voltage Energy Storage Pack Instance.  Not Operational is used when the module is initializing or not able to function (e.g. internal module level monitors have failed).  Operational indicates that the ...";
CM_ SG_ 2364704766 Module11OperationalStatus "Operational Status of Module 11 in this High Voltage Energy Storage Pack Instance.  Not Operational is used when the module is initializing or not able to function (e.g. internal module level monitors have failed).  Operational indicates that the ...";
CM_ SG_ 2364704766 Module10OperationalStatus "Operational Status of Module 10 in this High Voltage Energy Storage Pack Instance.  Not Operational is used when the module is initializing or not able to function (e.g. internal module level monitors have failed).  Operational indicates that the ...";
CM_ SG_ 2364704766 Module9OperationalStatus "Operational Status of Module 9 in this High Voltage Energy Storage Pack Instance.  Not Operational is used when the module is initializing or not able to function (e.g. internal module level monitors have failed).  Operational indicates that the ...";
CM_ SG_ 2364704766 Module8OperationalStatus "Operational Status of Module 8 in this High Voltage Energy Storage Pack Instance.  Not Operational is used when the module is initializing or not able to function (e.g. internal module level monitors have failed).  Operational indicates that the ...";
CM_ SG_ 2364704766 Module7OperationalStatus "Operational Status of Module 7 in this High Voltage Energy Storage Pack Instance.  Not Operational is used when the module is initializing or not able to function (e.g. internal module level monitors have failed).  Operational indicates that the ...";
CM_ SG_ 2364704766 Module6OperationalStatus "Operational Status of Module 6 in this High Voltage Energy Storage Pack Instance.  Not Operational is used when the module is initializing or not able to function (e.g. internal module level monitors have failed).  Operational indicates that the ...";
CM_ SG_ 2364704766 Module5OperationalStatus "Operational Status of Module 5 in this High Voltage Energy Storage Pack Instance.  Not Operational is used when the module is initializing or not able to function (e.g. internal module level monitors have failed).  Operational indicates that the ...";
CM_ SG_ 2364704766 Module4OperationalStatus "Operational Status of Module 4 in this High Voltage Energy Storage Pack Instance.  Not Operational is used when the module is initializing or not able to function (e.g. internal module level monitors have failed).  Operational indicates that the ...";
CM_ SG_ 2364704766 Module3OperationalStatus "Operational Status of Module 3 in this High Voltage Energy Storage Pack Instance.  Not Operational is used when the module is initializing or not able to function (e.g. internal module level monitors have failed).  Operational indicates that the ...";
CM_ SG_ 2364704766 Module2OperationalStatus "Operational Status of Module 2 in this High Voltage Energy Storage Pack Instance.  Not Operational is used when the module is initializing or not able to function (e.g. internal module level monitors have failed).  Operational indicates that the ...";
CM_ SG_ 2364704766 Module1OperationalStatus "Operational Status of Module 1 in this High Voltage Energy Storage Pack Instance.  Not Operational is used when the module is initializing or not able to function (e.g. internal module level monitors have failed).  Operational indicates that the ...";
CM_ BO_ 2364704510 "High Voltage Energy Storage Pack 14 Data 7
Data set 7 (electrical) for High Voltage Energy Storage Pack 14.";
CM_ SG_ 2364704510 MaxChargeVLmt "The maximum voltage level not to be exceeded while charging this High Voltage Energy Storage Pack instance. If this parameter is not supported, the maximum charge voltage should be limited to SPN 15829 (HVESP14 Recommended Maximum Operating ...";
CM_ SG_ 2364704510 ChargeEnergyCapacity "The amount of unused electrical energy storage available to be filled by charging this High Voltage Energy Storage Pack instance, i.e. “how much empty space is remaining in the tank”. See SPN 15731 (HVESP14 Charge Capacity) for Ampere-hours (Ah).
 ...";
CM_ SG_ 2364704510 DisEnergyCapacity "The amount of stored electrical energy in this High Voltage Energy Storage Pack instance that is available for use by the hybrid system, i.e. “how full is the tank”. See SPN 15730 (HVESP14 Discharge Capacity) for Ampere-hours (Ah).
This parameter ...";
CM_ BO_ 2364704254 "High Voltage Energy Storage Pack 14 Status 1
Status data set 1 for High Voltage Energy Storage Pack 14.";
CM_ SG_ 2364704254 Status1CRC "The CRC is defined as follows:
• Length: 8 bits
• Polynomial: x^8+x^5+x^3+x^2+x+1
• Initial Value: FFh
• Input Data Reflection: Not reflected
• Result Data Reflection: Not reflected
• XOR value: FFh
SAE makes no claim of the functional safety ...";
CM_ SG_ 2364704254 Status1Counter "The message counter is used to detect situations where the transmitting ECU malfunction repeats the same frame all the time. The receiver of the information may use the counter parameter to detect this situation. The transmitting device will ...";
CM_ SG_ 2364704254 OperationalStatus "Provides feedback on where this High Voltage Energy Storage Pack instance is in its operating spectrum, and includes feedback in response to the Operation Consent [i.e. SPN 15701 (HVESP14 Operation Consent)] and Power Down Command [i.e. SPN 15696 ...";
CM_ SG_ 2364704254 HVBusConnectionStatus "This parameter provides high level feedback on this High Voltage Energy Storage Pack instance high voltage bus connection. For specific contactor information, see SPN 15743 (HVESP14 High-Voltage Bus (Positive) Contactor State), SPN 15744 (HVESP14 ...";
CM_ SG_ 2364704254 InternalChargerStatus "Indicates that the charger in this HVES instance is on.  External chargers may use the External Energy Source Connection Status (SPN 7898) and related SPs.
This parameter is for one of multiple packs in an HVESS. If there is only one pack in the ...";
CM_ SG_ 2364704254 CellBalancingActive "Indicates whether or not the cells in this High Voltage Energy Storage Pack instance are currently being balanced.
This parameter is for one of multiple packs in an HVESS.  If there is only one pack in the system, the HVESS parameters should be ...";
CM_ SG_ 2364704254 CellBalanceStatus "Indicates whether or not the cells in this High Voltage Energy Storage Pack instance are balanced.
This parameter is for one of multiple packs in an HVESS.  If there is only one pack in the system, the HVESS parameters should be used. If there are ...";
CM_ SG_ 2364704254 StOfChargeStatus "Status of this High Voltage Energy Storage Pack instance State of Charge (SOC).  Note:  A given HVES controller may not support all of the states.
This parameter is for one of multiple packs in an HVESS.  If there is only one pack in the system, ...";
CM_ SG_ 2364704254 InertiaSwStatus "Switch indicating that an impact has been sensed by this High Voltage Energy Storage Pack instance. The impact indication may require action by another controller, or by this HVES instance itself.  For example, a controller may elect to take this ...";
CM_ SG_ 2364704254 HVILStatus "Status of the High Voltage Interlock Loop from the viewpoint of this High Voltage Energy Storage Pack instance.
This parameter is for one of multiple packs in an HVESS. If there is only one pack in the system, the HVESS parameters should be used ...";
CM_ SG_ 2364704254 HVBusPassiveIsolTestStatus "Status of the high-voltage bus electrical passive isolation test as performed by this High Voltage Energy Storage Pack instance.
This parameter is for one of multiple packs in an HVESS. If there is only one pack in the system, the HVESS parameters ...";
CM_ SG_ 2364704254 HVBusActiveIsolTestStatus "Status of the high-voltage bus electrical active isolation test as performed by this High Voltage Energy Storage Pack instance.
This parameter is for one of multiple packs in an HVESS. If there is only one pack in the system, the HVESS parameters ...";
CM_ SG_ 2364704254 CenterOfPackContactorSt "Position of the center high-voltage contactor. When this contactor is closed, the positive half of this High Voltage Energy Storage Pack instance is connected to the negative half. If a system controls the positive, negative, and center contactors ...";
CM_ SG_ 2364704254 HVBusPreChargeRelaySt "Position of the high-voltage bus contactor pre-charge relay.  When this relay is closed, this High Voltage Energy Storage Pack instance is bringing the high-voltage bus up to its operating level.
This parameter is for one of multiple packs in an ...";
CM_ SG_ 2364704254 HVBusDisconnectForewarning "Indicates that this High Voltage Energy Storage Pack instance is about to disconnect from the high voltage bus due to unacceptable conditions.
This parameter is for one of multiple packs in an HVESS. If there is only one pack in the system, the ...";
CM_ SG_ 2364704254 HVBusContactorSt15744 "Position of this High Voltage Energy Storage Pack instance negative side bus contactor. When this contactor is closed, the negative side of this HVES instance is connected to the negative side of the high-voltage bus. If a system controls the ...";
CM_ SG_ 2364704254 HVBusContactorSt "Position of this High Voltage Energy Storage Pack instance positive side bus contactor.  When this contactor is closed, the positive side of this HVES instance is connected to the positive side of the high-voltage bus.  In systems where all ...";
CM_ BO_ 2364703998 "High Voltage Energy Storage Pack 14 Data 6
Data set 6 (external or interface data) for High Voltage Energy Storage Pack 14.";
CM_ SG_ 2364703998 Temp "The temperature of this High Voltage Energy Storage Pack instance. The value may be determined from a unique sensor specifically for this purpose, or by aggregating various temperature sensor readings within the pack.
This parameter is for one of ...";
CM_ SG_ 2364703998 ETemp "The temperature of the electronics or control modules in this High Voltage Energy Storage Pack instance.  If there are multiple temperature sensors then this parameter would be set to the maximum sensor reading.
This parameter is for one of ...";
CM_ SG_ 2364703998 OutCoolantTemp "The temperature of liquid coolant as it exits this High Voltage Energy Storage Pack instance.
This parameter is for one of multiple packs in an HVESS.  If there is only one pack in the system, the HVESS parameters should be used. If there are ...";
CM_ SG_ 2364703998 InCoolantTemp "The temperature of liquid coolant as it enters this High Voltage Energy Storage Pack instance.
This parameter is for one of multiple packs in an HVESS.  If there is only one pack in the system, the HVESS parameters should be used. If there are ...";
CM_ SG_ 2364703998 IgntV "The voltage level at the ignition input of this High Voltage Energy Storage Pack controller.
This parameter is for one of multiple packs in an HVESS.  If there is only one pack in the system, the HVESS parameters should be used.  If there are ...";
CM_ SG_ 2364703998 BusV "The voltage level of the high voltage bus, as measured by this High Voltage Energy Storage Pack instance on the bus side (not the battery side) of its contactors.
This parameter is for one of multiple packs in an HVESS.  If there is only one pack ...";
CM_ BO_ 2364703742 "High Voltage Energy Storage Pack 14 Data 5
Data set 5 (electrical data) for High Voltage Energy Storage Pack 14.";
CM_ SG_ 2364703742 HighestCellStOfCharge "Indicates the state of charge of the highest-charged cell in this High Voltage Energy Storage Pack instance. 0% means no charge remaining, 100% means the cell is fully charged. If a single state of charge value covers more than one cell, the value ...";
CM_ SG_ 2364703742 LowestCellStOfCharge "Indicates the state of charge of the lowest-charged cell in this High Voltage Energy Storage Pack instance. 0% means no charge remaining, 100% means the cell is fully charged. If a single state of charge value covers more than one cell, the value in ...";
CM_ SG_ 2364703742 ChargeCurLmt "The maximum instantaneous current flow limit into this High Voltage Energy Storage Pack instance. This parameter is defined from the high voltage energy storage pack's point of view and should reflect the instantaneous capability of the pack.  The ...";
CM_ SG_ 2364703742 DisCurLmt "The maximum instantaneous current flow limit out of this High Voltage Energy Storage Pack instance. This parameter is defined from the high voltage energy storage pack's point of view and should reflect the instantaneous capability of the pack.  The ...";
CM_ BO_ 2364703486 "High Voltage Energy Storage Pack 14 Data 4
Data set 4 (electrical data) for High Voltage Energy Storage Pack 14.";
CM_ SG_ 2364703486 CellBalancingCount "The number of cells that are currently being balanced in this High Voltage Energy Storage Pack instance.
This parameter is for one of multiple packs in an HVESS.  If there is only one pack in the system, the HVESS parameters should be used.  If ...";
CM_ SG_ 2364703486 ChargeCapacity "The amount of unused electrical charge storage in this High Voltage Energy Storage Pack instance that is available to be filled by charging, i.e. “how much empty space is remaining in the tank”. See SPN 15761 (HVESP14 Charge Energy Capacity) for ...";
CM_ SG_ 2364703486 DisCapacity "The amount of stored electrical charge in this High Voltage Energy Storage Pack instance that is available for use by the hybrid system, i.e. “how full is the tank”. See SPN 15760 (HVESP14 Discharge Energy Capacity) for kilowatt-hours (kWh).
This ...";
CM_ BO_ 2364703230 "High Voltage Energy Storage Pack 14 Data 3
Data set 3 (thermal data) for High Voltage Energy Storage Pack 14.";
CM_ SG_ 2364703230 CellTempDiffStatus "Indicates whether or not the differential between the highest and lowest cell temperatures are within acceptable limits per this High Voltage Energy Storage Pack instance. The actual temperature differential can be calculated by subtracting SPN ...";
CM_ SG_ 2364703230 AvgCellTemp "The average temperature level of all cells in this High Voltage Energy Storage Pack instance.
This parameter is for one of multiple packs in an HVESS.  If there is only one pack in the system, the HVESS parameters should be used.  If there are ...";
CM_ SG_ 2364703230 LowestCellTemp "The lowest temperature level reported by any cell in this High Voltage Energy Storage Pack instance. If a single temperature sensor covers more than one cell, the value in this parameter is for the smallest group of cells measured. See SPN 15810 ...";
CM_ SG_ 2364703230 HighestCellTemp "The highest temperature level reported by any cell in this High Voltage Energy Storage Pack instance. If a single temperature sensor covers more than one cell, the value in this parameter is for the smallest group of cells measured. See SPN 15808 ...";
CM_ BO_ 2364702974 "High Voltage Energy Storage Pack 14 Data 2
Data set 2 (electrical data) for High Voltage Energy Storage Pack 14.";
CM_ SG_ 2364702974 CellVDiffStatus "Indicates whether or not the differential between the highest and lowest cell voltages are within acceptable limits, according to this High Voltage Energy Storage Pack instance. The actual voltage differential can be calculated by subtracting SPN ...";
CM_ SG_ 2364702974 LowestCellV "The lowest voltage level reported by any cell in this High Voltage Energy Storage Pack instance. If a single voltage sensor covers more than one cell, the value in this parameter is for the smallest group of cells measured. See SPN 15805 (HVESP14 ...";
CM_ SG_ 2364702974 HighestCellV "The highest voltage level reported by any cell in this High Voltage Energy Storage Pack instance. If a single voltage sensor covers more than one cell, the value in this parameter is for the smallest group of cells measured. See SPN 15803 (HVESP14 ...";
CM_ SG_ 2364702974 FastUpdateStOfCharge "Indicates this High Voltage Energy Storage Pack instance state of charge. 0% means no charge remaining, 100% means the system is fully charged in terms of physical limits of this energy storage pack instance. Acceptable state of charge upper and ...";
CM_ BO_ 2364702718 "High Voltage Energy Storage Pack 14 Data 1
Data set 1 (electrical data) for High Voltage Energy Storage Pack 14.";
CM_ SG_ 2364702718 Cur "The current in or out of this High Voltage Energy Storage Pack instance. This parameter should be synchronized with SPN 15720 (HVESP14 Voltage Level) such that a realized power value can be calculated. This parameter is defined from the high voltage ...";
CM_ SG_ 2364702718 Lvl "The voltage level of this High Voltage Energy Storage Pack instance. This parameter should be synchronized with SPN 15721 (HVESP14 Current) such that a realized power value can be calculated. If the HVES component physically contains the contactors ...";
CM_ SG_ 2364702718 AvailableChargePwr "The rate at which this High Voltage Energy Storage Pack instance can currently receive energy from a regenerative or recharging system.
This parameter is for one of multiple packs in an HVESS.  If there is only one pack in the system, the HVESS ...";
CM_ SG_ 2364702718 AvailableDisPwr "The rate at which this High Voltage Energy Storage Pack instance can currently provide energy for propulsion or other uses.
This parameter is for one of multiple packs in an HVESS.  If there is only one pack in the system, the HVESS parameters ...";
CM_ BO_ 2364702462 "High Voltage Energy Storage Pack 14 Status 2
Status data set 2 for High Voltage Energy Storage Pack 14.";
CM_ SG_ 2364702462 ChargePLDueToAnUndefinedCause "Indicates whether or not charge power of this HVES instance is being limited due to an undefined cause.
This parameter is for one of multiple packs in an HVESS.  If there is only one pack in the system, the HVESS parameters should be used. If there ...";
CM_ SG_ 2364702462 ChargePLDueToBatCur "Indicates whether or not charge power of this HVES instance is being limited due to battery current.
This parameter is for one of multiple packs in an HVESS.  If there is only one pack in the system, the HVESS parameters should be used. If there ...";
CM_ SG_ 2364702462 ChargePLDueToBatOrCellV "Indicates whether or not charge power of this HVES instance is being limited due to a battery or cell voltage level.
This parameter is for one of multiple packs in an HVESS.  If there is only one pack in the system, the HVESS parameters should be ...";
CM_ SG_ 2364702462 ChargePLDueToBatDiagCondition "Indicates whether or not charge power of this HVES instance is being limited due to a battery diagnostic condition.
This parameter is for one of multiple packs in an HVESS.  If there is only one pack in the system, the HVESS parameters should be ...";
CM_ SG_ 2364702462 ChargePLDueToBatTemp "Indicates whether or not charge power of this HVES instance is being limited due to battery temperature.
This parameter is for one of multiple packs in an HVESS.  If there is only one pack in the system, the HVESS parameters should be used. If ...";
CM_ SG_ 2364702462 ChargePLDueToStOfCharge "Indicates whether or not charge power of this HVES instance is being limited due to state of charge.
This parameter is for one of multiple packs in an HVESS.  If there is only one pack in the system, the HVESS parameters should be used. If there ...";
CM_ SG_ 2364702462 DisPLDueToAnUndefinedCause "Indicates whether or not discharge power of this HVES instance is being limited due to an undefined cause.
This parameter is for one of multiple packs in an HVESS.  If there is only one pack in the system, the HVESS parameters should be used. If ...";
CM_ SG_ 2364702462 DisPLDueToBatCur "Indicates whether or not discharge power of this HVES instance is being limited due to battery current.
This parameter is for one of multiple packs in an HVESS.  If there is only one pack in the system, the HVESS parameters should be used. If there ...";
CM_ SG_ 2364702462 DisPLDueToBatOrCellV "Indicates whether or not discharge power of this HVES instance is being limited due to a battery or cell voltage level.
This parameter is for one of multiple packs in an HVESS.  If there is only one pack in the system, the HVESS parameters should ...";
CM_ SG_ 2364702462 DisPLDueToBatDiagCondition "Indicates whether or not discharge power of this HVES instance is being limited due to a battery diagnostic condition.
This parameter is for one of multiple packs in an HVESS.  If there is only one pack in the system, the HVESS parameters should be ...";
CM_ SG_ 2364702462 DisPLDueToBatTemp "Indicates whether or not discharge power of this HVES instance is being limited due to battery temperature.
This parameter is for one of multiple packs in an HVESS.  If there is only one pack in the system, the HVESS parameters should be used. If ...";
CM_ SG_ 2364702462 DisPLDueToStOfCharge "Indicates whether or not discharge power of this HVES instance is being limited due to state of charge.
This parameter is for one of multiple packs in an HVESS.  If there is only one pack in the system, the HVESS parameters should be used. If there ...";
CM_ BO_ 2364702206 "High Voltage Energy Storage Pack 13 Data 11
Data set 11 (electrical data) for High Voltage Energy Storage Pack 13.";
CM_ SG_ 2364702206 ActualChargeRate "This signal represents the actual present charge rate of this High Voltage Energy Storage Pack instance.
This parameter is for one of multiple packs in an HVESS. If there is only one pack in the system, the HVESS parameters should be used. If there ...";
CM_ SG_ 2364702206 LvlNegToChassisGroundV "Voltage difference between the most negative terminal of the HVES battery and chassis measured at the battery side of any HVES contained output contactor.  This voltage may be used for system level monitoring of battery shorts to chassis within the ...";
CM_ SG_ 2364702206 BusVNegToChassisGroundV "Voltage difference between the most negative terminal of the HVES battery and chassis measured on the hybrid system bus side (not the battery side) of any HVES contained output contactor.  This voltage may be used for system level monitoring of ...";
BA_DEF_ SG_  "GenSigInactiveValue" INT 0 0;
BA_DEF_ SG_  "SigType" ENUM  "Default","Range","RangeSigned","ASCII","Discrete","Control","ReferencePGN","DTC","StringDelimiter","StringLength","StringLengthControl","MessageCounter","MessageChecksum";
BA_DEF_ SG_  "GenSigStartValue" INT 0 2147483647;
BA_DEF_ SG_  "GenSigSendType" ENUM  "Cyclic","OnWrite","OnWriteWithRepetition","OnChange","OnChangeWithRepetition","IfActive","IfActiveWithRepetition","NoSigSendType";
BA_DEF_ SG_  "GenSigILSupport" ENUM  "No","Yes";
BA_DEF_ SG_  "SPN" INT 0 524287;
BA_DEF_ BO_  "J1939CPgSendTimeout" INT -1 3600000;
BA_DEF_ BO_  "J1939CPgTOS" INT 0 7;
BA_DEF_ BO_  "J1939PgAppearanceOnBus" ENUM  "Default","CAN_Extended","CANFD_Extended";
BA_DEF_ BO_  "FsJ1939UseCrcAndCounter" STRING ;
BA_DEF_ BO_  "TpJ1939VarDlc" ENUM  "No","Yes";
BA_DEF_ BO_  "GenMsgNrOfRepetition" INT 0 1000000;
BA_DEF_ BO_  "GenMsgCycleTimeFast" INT 0 3600000;
BA_DEF_ BO_  "GenMsgFastOnStart" INT 0 100000;
BA_DEF_ BO_  "GenMsgStartDelayTime" INT 0 100000;
BA_DEF_ BO_  "GenMsgILSupport" ENUM  "No","Yes";
BA_DEF_ BO_  "GenMsgDelayTime" INT 0 1000;
BA_DEF_ BO_  "GenMsgRequestable" INT 0 1;
BA_DEF_ BO_  "GenMsgSendType" ENUM  "cyclic","NotUsed","NotUsed","NotUsed","NotUsed","NotUsed","NotUsed","IfActive","noMsgSendType";
BA_DEF_ BO_  "VFrameFormat" ENUM  "StandardCAN","ExtendedCAN","reserved","J1939PG","reserved","reserved","reserved","reserved","reserved","reserved","reserved","reserved","reserved","reserved","StandardCAN_FD","ExtendedCAN_FD";
BA_DEF_ BO_  "SingleFrame" INT 0 1;
BA_DEF_ BO_  "GenMsgCycleTime" INT 0 3600000;
BA_DEF_ SG_  "SystemSignalLongSymbol" STRING ;
BA_DEF_DEF_  "GenSigInactiveValue" 0;
BA_DEF_DEF_  "SigType" "Default";
BA_DEF_DEF_  "GenSigStartValue" 0;
BA_DEF_DEF_  "GenSigSendType" "NoSigSendType";
BA_DEF_DEF_  "GenSigILSupport" "Yes";
BA_DEF_DEF_  "SPN" 0;
BA_DEF_DEF_  "J1939CPgSendTimeout" -1;
BA_DEF_DEF_  "J1939CPgTOS" 2;
BA_DEF_DEF_  "J1939PgAppearanceOnBus" "Default";
BA_DEF_DEF_  "FsJ1939UseCrcAndCounter" "";
BA_DEF_DEF_  "TpJ1939VarDlc" "No";
BA_DEF_DEF_  "GenMsgNrOfRepetition" 0;
BA_DEF_DEF_  "GenMsgCycleTimeFast" 0;
BA_DEF_DEF_  "GenMsgFastOnStart" 0;
BA_DEF_DEF_  "GenMsgStartDelayTime" 0;
BA_DEF_DEF_  "GenMsgILSupport" "Yes";
BA_DEF_DEF_  "GenMsgDelayTime" 0;
BA_DEF_DEF_  "GenMsgRequestable" 1;
BA_DEF_DEF_  "GenMsgSendType" "noMsgSendType";
BA_DEF_DEF_  "VFrameFormat" "J1939PG";
BA_DEF_DEF_  "SingleFrame" 1;
BA_DEF_DEF_  "GenMsgCycleTime" 0;
BA_DEF_DEF_  "SystemSignalLongSymbol" "";
BA_ "GenMsgSendType" BO_ 2364712446 0;
BA_ "GenMsgCycleTime" BO_ 2364712446 100;
BA_ "GenMsgSendType" BO_ 2364712190 0;
BA_ "GenMsgCycleTime" BO_ 2364712190 100;
BA_ "FsJ1939UseCrcAndCounter" BO_ 2364711934 "Aa";
BA_ "GenMsgDelayTime" BO_ 2364711934 20;
BA_ "GenMsgSendType" BO_ 2364711934 0;
BA_ "GenMsgCycleTime" BO_ 2364711934 100;
BA_ "GenMsgSendType" BO_ 2364711678 0;
BA_ "GenMsgCycleTime" BO_ 2364711678 100;
BA_ "GenMsgSendType" BO_ 2364711422 0;
BA_ "GenMsgCycleTime" BO_ 2364711422 20;
BA_ "GenMsgSendType" BO_ 2364711166 0;
BA_ "GenMsgCycleTime" BO_ 2364711166 100;
BA_ "GenMsgSendType" BO_ 2364710910 0;
BA_ "GenMsgCycleTime" BO_ 2364710910 20;
BA_ "GenMsgSendType" BO_ 2364710654 0;
BA_ "GenMsgCycleTime" BO_ 2364710654 20;
BA_ "GenMsgSendType" BO_ 2364710398 0;
BA_ "GenMsgCycleTime" BO_ 2364710398 20;
BA_ "GenMsgSendType" BO_ 2364710142 0;
BA_ "GenMsgCycleTime" BO_ 2364710142 100;
BA_ "GenMsgSendType" BO_ 2364709886 0;
BA_ "GenMsgCycleTime" BO_ 2364709886 100;
BA_ "GenMsgSendType" BO_ 2364709630 0;
BA_ "GenMsgCycleTime" BO_ 2364709630 100;
BA_ "FsJ1939UseCrcAndCounter" BO_ 2364709374 "Aa";
BA_ "GenMsgSendType" BO_ 2364709374 0;
BA_ "GenMsgCycleTime" BO_ 2364709374 100;
BA_ "GenMsgSendType" BO_ 2364709118 0;
BA_ "GenMsgCycleTime" BO_ 2364709118 100;
BA_ "GenMsgSendType" BO_ 2364708862 0;
BA_ "GenMsgCycleTime" BO_ 2364708862 100;
BA_ "GenMsgSendType" BO_ 2364708606 0;
BA_ "GenMsgCycleTime" BO_ 2364708606 100;
BA_ "GenMsgSendType" BO_ 2364708350 0;
BA_ "GenMsgCycleTime" BO_ 2364708350 100;
BA_ "FsJ1939UseCrcAndCounter" BO_ 2364708094 "Aa";
BA_ "GenMsgDelayTime" BO_ 2364708094 20;
BA_ "GenMsgSendType" BO_ 2364708094 0;
BA_ "GenMsgCycleTime" BO_ 2364708094 100;
BA_ "GenMsgSendType" BO_ 2364707838 0;
BA_ "GenMsgCycleTime" BO_ 2364707838 100;
BA_ "GenMsgSendType" BO_ 2364707582 0;
BA_ "GenMsgCycleTime" BO_ 2364707582 20;
BA_ "GenMsgSendType" BO_ 2364707326 0;
BA_ "GenMsgCycleTime" BO_ 2364707326 100;
BA_ "GenMsgSendType" BO_ 2364707070 0;
BA_ "GenMsgCycleTime" BO_ 2364707070 20;
BA_ "GenMsgSendType" BO_ 2364706814 0;
BA_ "GenMsgCycleTime" BO_ 2364706814 20;
BA_ "GenMsgSendType" BO_ 2364706558 0;
BA_ "GenMsgCycleTime" BO_ 2364706558 20;
BA_ "GenMsgSendType" BO_ 2364706302 0;
BA_ "GenMsgCycleTime" BO_ 2364706302 100;
BA_ "GenMsgSendType" BO_ 2364706046 0;
BA_ "GenMsgCycleTime" BO_ 2364706046 100;
BA_ "GenMsgSendType" BO_ 2364705790 0;
BA_ "GenMsgCycleTime" BO_ 2364705790 100;
BA_ "FsJ1939UseCrcAndCounter" BO_ 2364705534 "Aa";
BA_ "GenMsgSendType" BO_ 2364705534 0;
BA_ "GenMsgCycleTime" BO_ 2364705534 100;
BA_ "GenMsgSendType" BO_ 2364705278 0;
BA_ "GenMsgCycleTime" BO_ 2364705278 100;
BA_ "GenMsgSendType" BO_ 2364705022 0;
BA_ "GenMsgCycleTime" BO_ 2364705022 100;
BA_ "GenMsgSendType" BO_ 2364704766 0;
BA_ "GenMsgCycleTime" BO_ 2364704766 100;
BA_ "GenMsgSendType" BO_ 2364704510 0;
BA_ "GenMsgCycleTime" BO_ 2364704510 100;
BA_ "FsJ1939UseCrcAndCounter" BO_ 2364704254 "Aa";
BA_ "GenMsgDelayTime" BO_ 2364704254 20;
BA_ "GenMsgSendType" BO_ 2364704254 0;
BA_ "GenMsgCycleTime" BO_ 2364704254 100;
BA_ "GenMsgSendType" BO_ 2364703998 0;
BA_ "GenMsgCycleTime" BO_ 2364703998 100;
BA_ "GenMsgSendType" BO_ 2364703742 0;
BA_ "GenMsgCycleTime" BO_ 2364703742 20;
BA_ "GenMsgSendType" BO_ 2364703486 0;
BA_ "GenMsgCycleTime" BO_ 2364703486 100;
BA_ "GenMsgSendType" BO_ 2364703230 0;
BA_ "GenMsgCycleTime" BO_ 2364703230 20;
BA_ "GenMsgSendType" BO_ 2364702974 0;
BA_ "GenMsgCycleTime" BO_ 2364702974 20;
BA_ "GenMsgSendType" BO_ 2364702718 0;
BA_ "GenMsgCycleTime" BO_ 2364702718 20;
BA_ "GenMsgSendType" BO_ 2364702462 0;
BA_ "GenMsgCycleTime" BO_ 2364702462 100;
BA_ "GenMsgSendType" BO_ 2364702206 0;
BA_ "GenMsgCycleTime" BO_ 2364702206 100;
BA_ "SigType" SG_ 2364712446 Module32OperationalStatus 5;
BA_ "SPN" SG_ 2364712446 Module32OperationalStatus 16078;
BA_ "SigType" SG_ 2364712446 Module31OperationalStatus 5;
BA_ "SPN" SG_ 2364712446 Module31OperationalStatus 16077;
BA_ "SigType" SG_ 2364712446 Module30OperationalStatus 5;
BA_ "SPN" SG_ 2364712446 Module30OperationalStatus 16076;
BA_ "SigType" SG_ 2364712446 Module29OperationalStatus 5;
BA_ "SPN" SG_ 2364712446 Module29OperationalStatus 16075;
BA_ "SigType" SG_ 2364712446 Module28OperationalStatus 5;
BA_ "SPN" SG_ 2364712446 Module28OperationalStatus 16074;
BA_ "SigType" SG_ 2364712446 Module27OperationalStatus 5;
BA_ "SPN" SG_ 2364712446 Module27OperationalStatus 16073;
BA_ "SigType" SG_ 2364712446 Module26OperationalStatus 5;
BA_ "SPN" SG_ 2364712446 Module26OperationalStatus 16072;
BA_ "SigType" SG_ 2364712446 Module25OperationalStatus 5;
BA_ "SPN" SG_ 2364712446 Module25OperationalStatus 16071;
BA_ "SigType" SG_ 2364712446 Module24OperationalStatus 5;
BA_ "SPN" SG_ 2364712446 Module24OperationalStatus 16070;
BA_ "SigType" SG_ 2364712446 Module23OperationalStatus 5;
BA_ "SPN" SG_ 2364712446 Module23OperationalStatus 16069;
BA_ "SigType" SG_ 2364712446 Module22OperationalStatus 5;
BA_ "SPN" SG_ 2364712446 Module22OperationalStatus 16068;
BA_ "SigType" SG_ 2364712446 Module21OperationalStatus 5;
BA_ "SPN" SG_ 2364712446 Module21OperationalStatus 16067;
BA_ "SigType" SG_ 2364712446 Module20OperationalStatus 5;
BA_ "SPN" SG_ 2364712446 Module20OperationalStatus 16066;
BA_ "SigType" SG_ 2364712446 Module19OperationalStatus 5;
BA_ "SPN" SG_ 2364712446 Module19OperationalStatus 16065;
BA_ "SigType" SG_ 2364712446 Module18OperationalStatus 5;
BA_ "SPN" SG_ 2364712446 Module18OperationalStatus 16064;
BA_ "SigType" SG_ 2364712446 Module17OperationalStatus 5;
BA_ "SPN" SG_ 2364712446 Module17OperationalStatus 16063;
BA_ "SigType" SG_ 2364712446 Module16OperationalStatus 5;
BA_ "SPN" SG_ 2364712446 Module16OperationalStatus 16062;
BA_ "SigType" SG_ 2364712446 Module15OperationalStatus 5;
BA_ "SPN" SG_ 2364712446 Module15OperationalStatus 16061;
BA_ "SigType" SG_ 2364712446 Module14OperationalStatus 5;
BA_ "SPN" SG_ 2364712446 Module14OperationalStatus 16060;
BA_ "SigType" SG_ 2364712446 Module13OperationalStatus 5;
BA_ "SPN" SG_ 2364712446 Module13OperationalStatus 16059;
BA_ "SigType" SG_ 2364712446 Module12OperationalStatus 5;
BA_ "SPN" SG_ 2364712446 Module12OperationalStatus 16058;
BA_ "SigType" SG_ 2364712446 Module11OperationalStatus 5;
BA_ "SPN" SG_ 2364712446 Module11OperationalStatus 16057;
BA_ "SigType" SG_ 2364712446 Module10OperationalStatus 5;
BA_ "SPN" SG_ 2364712446 Module10OperationalStatus 16056;
BA_ "SigType" SG_ 2364712446 Module9OperationalStatus 5;
BA_ "SPN" SG_ 2364712446 Module9OperationalStatus 16055;
BA_ "SigType" SG_ 2364712446 Module8OperationalStatus 5;
BA_ "SPN" SG_ 2364712446 Module8OperationalStatus 16054;
BA_ "SigType" SG_ 2364712446 Module7OperationalStatus 5;
BA_ "SPN" SG_ 2364712446 Module7OperationalStatus 16053;
BA_ "SigType" SG_ 2364712446 Module6OperationalStatus 5;
BA_ "SPN" SG_ 2364712446 Module6OperationalStatus 16052;
BA_ "SigType" SG_ 2364712446 Module5OperationalStatus 5;
BA_ "SPN" SG_ 2364712446 Module5OperationalStatus 16051;
BA_ "SigType" SG_ 2364712446 Module4OperationalStatus 5;
BA_ "SPN" SG_ 2364712446 Module4OperationalStatus 16050;
BA_ "SigType" SG_ 2364712446 Module3OperationalStatus 5;
BA_ "SPN" SG_ 2364712446 Module3OperationalStatus 16049;
BA_ "SigType" SG_ 2364712446 Module2OperationalStatus 5;
BA_ "SPN" SG_ 2364712446 Module2OperationalStatus 16048;
BA_ "SigType" SG_ 2364712446 Module1OperationalStatus 5;
BA_ "SPN" SG_ 2364712446 Module1OperationalStatus 16047;
BA_ "SigType" SG_ 2364712190 MaxChargeVLmt 1;
BA_ "SPN" SG_ 2364712190 MaxChargeVLmt 16046;
BA_ "SPN" SG_ 2364712190 ChargeEnergyCapacity 16045;
BA_ "SPN" SG_ 2364712190 DisEnergyCapacity 16044;
BA_ "SigType" SG_ 2364711934 Status1CRC 12;
BA_ "SPN" SG_ 2364711934 Status1CRC 16043;
BA_ "SigType" SG_ 2364711934 Status1Counter 11;
BA_ "SPN" SG_ 2364711934 Status1Counter 16042;
BA_ "SPN" SG_ 2364711934 OperationalStatus 16041;
BA_ "SPN" SG_ 2364711934 HVBusConnectionStatus 16040;
BA_ "SigType" SG_ 2364711934 InternalChargerStatus 5;
BA_ "SPN" SG_ 2364711934 InternalChargerStatus 16039;
BA_ "SigType" SG_ 2364711934 CellBalancingActive 4;
BA_ "SPN" SG_ 2364711934 CellBalancingActive 16038;
BA_ "SigType" SG_ 2364711934 CellBalanceStatus 4;
BA_ "SPN" SG_ 2364711934 CellBalanceStatus 16037;
BA_ "SPN" SG_ 2364711934 StOfChargeStatus 16036;
BA_ "SigType" SG_ 2364711934 InertiaSwStatus 4;
BA_ "SPN" SG_ 2364711934 InertiaSwStatus 16035;
BA_ "SigType" SG_ 2364711934 HVILStatus 4;
BA_ "SPN" SG_ 2364711934 HVILStatus 16034;
BA_ "SPN" SG_ 2364711934 HVBusPassiveIsolTestStatus 16033;
BA_ "SPN" SG_ 2364711934 HVBusActiveIsolTestStatus 16032;
BA_ "SigType" SG_ 2364711934 CenterOfPackContactorSt 4;
BA_ "SPN" SG_ 2364711934 CenterOfPackContactorSt 16031;
BA_ "SigType" SG_ 2364711934 HVBusPreChargeRelaySt 4;
BA_ "SPN" SG_ 2364711934 HVBusPreChargeRelaySt 16030;
BA_ "SPN" SG_ 2364711934 HVBusDisconnectForewarning 16029;
BA_ "SigType" SG_ 2364711934 HVBusContactorSt16028 4;
BA_ "SPN" SG_ 2364711934 HVBusContactorSt16028 16028;
BA_ "SigType" SG_ 2364711934 HVBusContactorSt 4;
BA_ "SPN" SG_ 2364711934 HVBusContactorSt 16027;
BA_ "SigType" SG_ 2364711678 Temp 1;
BA_ "SPN" SG_ 2364711678 Temp 16026;
BA_ "SigType" SG_ 2364711678 ETemp 1;
BA_ "SPN" SG_ 2364711678 ETemp 16025;
BA_ "SigType" SG_ 2364711678 OutCoolantTemp 1;
BA_ "SPN" SG_ 2364711678 OutCoolantTemp 16024;
BA_ "SigType" SG_ 2364711678 InCoolantTemp 1;
BA_ "SPN" SG_ 2364711678 InCoolantTemp 16023;
BA_ "SigType" SG_ 2364711678 IgntV 1;
BA_ "SPN" SG_ 2364711678 IgntV 16022;
BA_ "SigType" SG_ 2364711678 BusV 1;
BA_ "SPN" SG_ 2364711678 BusV 16021;
BA_ "SigType" SG_ 2364711422 HighestCellStOfCharge 1;
BA_ "SPN" SG_ 2364711422 HighestCellStOfCharge 16020;
BA_ "SigType" SG_ 2364711422 LowestCellStOfCharge 1;
BA_ "SPN" SG_ 2364711422 LowestCellStOfCharge 16019;
BA_ "SigType" SG_ 2364711422 ChargeCurLmt 1;
BA_ "GenSigStartValue" SG_ 2364711422 ChargeCurLmt 32000;
BA_ "SPN" SG_ 2364711422 ChargeCurLmt 16018;
BA_ "SigType" SG_ 2364711422 DisCurLmt 1;
BA_ "SPN" SG_ 2364711422 DisCurLmt 16017;
BA_ "SigType" SG_ 2364711166 CellBalancingCount 1;
BA_ "SPN" SG_ 2364711166 CellBalancingCount 16016;
BA_ "SigType" SG_ 2364711166 ChargeCapacity 1;
BA_ "SPN" SG_ 2364711166 ChargeCapacity 16015;
BA_ "SigType" SG_ 2364711166 DisCapacity 1;
BA_ "SPN" SG_ 2364711166 DisCapacity 16014;
BA_ "SigType" SG_ 2364710910 CellTempDiffStatus 4;
BA_ "SPN" SG_ 2364710910 CellTempDiffStatus 16013;
BA_ "SigType" SG_ 2364710910 AvgCellTemp 1;
BA_ "SPN" SG_ 2364710910 AvgCellTemp 16012;
BA_ "SigType" SG_ 2364710910 LowestCellTemp 1;
BA_ "SPN" SG_ 2364710910 LowestCellTemp 16011;
BA_ "SigType" SG_ 2364710910 HighestCellTemp 1;
BA_ "SPN" SG_ 2364710910 HighestCellTemp 16010;
BA_ "SPN" SG_ 2364710654 CellVDiffStatus 16009;
BA_ "SigType" SG_ 2364710654 LowestCellV 1;
BA_ "SPN" SG_ 2364710654 LowestCellV 16008;
BA_ "SigType" SG_ 2364710654 HighestCellV 1;
BA_ "SPN" SG_ 2364710654 HighestCellV 16007;
BA_ "SigType" SG_ 2364710654 FastUpdateStOfCharge 1;
BA_ "SPN" SG_ 2364710654 FastUpdateStOfCharge 16006;
BA_ "SigType" SG_ 2364710398 Cur 1;
BA_ "SPN" SG_ 2364710398 Cur 16005;
BA_ "SigType" SG_ 2364710398 Lvl 1;
BA_ "SPN" SG_ 2364710398 Lvl 16004;
BA_ "SigType" SG_ 2364710398 AvailableChargePwr 1;
BA_ "SPN" SG_ 2364710398 AvailableChargePwr 16003;
BA_ "SigType" SG_ 2364710398 AvailableDisPwr 1;
BA_ "SPN" SG_ 2364710398 AvailableDisPwr 16002;
BA_ "SigType" SG_ 2364710142 ChargePLDueToAnUndefinedCause 4;
BA_ "SPN" SG_ 2364710142 ChargePLDueToAnUndefinedCause 16001;
BA_ "SigType" SG_ 2364710142 ChargePLDueToBatCur 4;
BA_ "SPN" SG_ 2364710142 ChargePLDueToBatCur 16000;
BA_ "SigType" SG_ 2364710142 ChargePLDueToBatOrCellV 4;
BA_ "SPN" SG_ 2364710142 ChargePLDueToBatOrCellV 15999;
BA_ "SigType" SG_ 2364710142 ChargePLDueToBatDiagCondition 4;
BA_ "SPN" SG_ 2364710142 ChargePLDueToBatDiagCondition 15998;
BA_ "SigType" SG_ 2364710142 ChargePLDueToBatTemp 4;
BA_ "SPN" SG_ 2364710142 ChargePLDueToBatTemp 15997;
BA_ "SigType" SG_ 2364710142 ChargePLDueToStOfCharge 4;
BA_ "SPN" SG_ 2364710142 ChargePLDueToStOfCharge 15996;
BA_ "SigType" SG_ 2364710142 DisPLDueToAnUndefinedCause 4;
BA_ "SPN" SG_ 2364710142 DisPLDueToAnUndefinedCause 15995;
BA_ "SigType" SG_ 2364710142 DisPLDueToBatCur 4;
BA_ "SPN" SG_ 2364710142 DisPLDueToBatCur 15994;
BA_ "SigType" SG_ 2364710142 DisPLDueToBatOrCellV 4;
BA_ "SPN" SG_ 2364710142 DisPLDueToBatOrCellV 15993;
BA_ "SigType" SG_ 2364710142 DisPLDueToBatDiagCondition 4;
BA_ "SPN" SG_ 2364710142 DisPLDueToBatDiagCondition 15992;
BA_ "SigType" SG_ 2364710142 DisPLDueToBatTemp 4;
BA_ "SPN" SG_ 2364710142 DisPLDueToBatTemp 15991;
BA_ "SigType" SG_ 2364710142 DisPLDueToStOfCharge 4;
BA_ "SPN" SG_ 2364710142 DisPLDueToStOfCharge 15990;
BA_ "SigType" SG_ 2364709886 ActualChargeRate 1;
BA_ "SPN" SG_ 2364709886 ActualChargeRate 15962;
BA_ "SigType" SG_ 2364709886 LvlNegToChassisGroundV 1;
BA_ "SPN" SG_ 2364709886 LvlNegToChassisGroundV 15961;
BA_ "SigType" SG_ 2364709886 BusVNegToChassisGroundV 1;
BA_ "SPN" SG_ 2364709886 BusVNegToChassisGroundV 15960;
BA_ "SigType" SG_ 2364709630 HVBusPassiveIsolTestResults 1;
BA_ "SPN" SG_ 2364709630 HVBusPassiveIsolTestResults 15959;
BA_ "SigType" SG_ 2364709630 HVBusActiveIsolTestResults 1;
BA_ "SPN" SG_ 2364709630 HVBusActiveIsolTestResults 15958;
BA_ "SigType" SG_ 2364709630 LowestCellStOfChargeCellNum 1;
BA_ "SPN" SG_ 2364709630 LowestCellStOfChargeCellNum 15957;
BA_ "SigType" SG_ 2364709630 LowestCellStOfChargeModuleNum 1;
BA_ "SPN" SG_ 2364709630 LowestCellStOfChargeModuleNum 15956;
BA_ "SigType" SG_ 2364709630 HighestCellStOfChargeCellNum 1;
BA_ "SPN" SG_ 2364709630 HighestCellStOfChargeCellNum 15955;
BA_ "SigType" SG_ 2364709630 HighestCellStOfChargeModuleNum 1;
BA_ "SPN" SG_ 2364709630 HighestCellStOfChargeModuleNum 15954;
BA_ "SigType" SG_ 2364709374 Data9CRC 12;
BA_ "SPN" SG_ 2364709374 Data9CRC 23018;
BA_ "SigType" SG_ 2364709374 Data9Counter 11;
BA_ "SPN" SG_ 2364709374 Data9Counter 23017;
BA_ "SigType" SG_ 2364709374 Data9EmbeddedIntegritySupport 5;
BA_ "SPN" SG_ 2364709374 Data9EmbeddedIntegritySupport 23016;
BA_ "SigType" SG_ 2364709374 HVESS15ThermalEventDetected 4;
BA_ "SPN" SG_ 2364709374 HVESS15ThermalEventDetected 21302;
BA_ "SigType" SG_ 2364709374 LowestCellTempCellNum 1;
BA_ "SPN" SG_ 2364709374 LowestCellTempCellNum 15953;
BA_ "SigType" SG_ 2364709374 LowestCellTempModuleNum 1;
BA_ "SPN" SG_ 2364709374 LowestCellTempModuleNum 15952;
BA_ "SigType" SG_ 2364709374 HighestCellTempCellNum 1;
BA_ "SPN" SG_ 2364709374 HighestCellTempCellNum 15951;
BA_ "SigType" SG_ 2364709374 HighestCellTempModuleNum 1;
BA_ "SPN" SG_ 2364709374 HighestCellTempModuleNum 15950;
BA_ "SigType" SG_ 2364709118 AvgCellV 1;
BA_ "SPN" SG_ 2364709118 AvgCellV 15949;
BA_ "SigType" SG_ 2364709118 LowestCellVCellNum 1;
BA_ "SPN" SG_ 2364709118 LowestCellVCellNum 15948;
BA_ "SigType" SG_ 2364709118 LowestCellVModuleNum 1;
BA_ "SPN" SG_ 2364709118 LowestCellVModuleNum 15947;
BA_ "SigType" SG_ 2364709118 HighestCellVCellNum 1;
BA_ "SPN" SG_ 2364709118 HighestCellVCellNum 15946;
BA_ "SigType" SG_ 2364709118 HighestCellVModuleNum 1;
BA_ "SPN" SG_ 2364709118 HighestCellVModuleNum 15945;
BA_ "SigType" SG_ 2364708862 TMSCoolantLvl 4;
BA_ "SPN" SG_ 2364708862 TMSCoolantLvl 15944;
BA_ "SPN" SG_ 2364708862 TMSMode 15943;
BA_ "SigType" SG_ 2364708862 TMSHVILStatus 4;
BA_ "SPN" SG_ 2364708862 TMSHVILStatus 15942;
BA_ "SigType" SG_ 2364708862 TMSHtrStatus 5;
BA_ "SPN" SG_ 2364708862 TMSHtrStatus 15941;
BA_ "SigType" SG_ 2364708862 TMSRelHumidty 1;
BA_ "SPN" SG_ 2364708862 TMSRelHumidty 15940;
BA_ "SigType" SG_ 2364708862 TMSCompressorSpd 1;
BA_ "SPN" SG_ 2364708862 TMSCompressorSpd 15939;
BA_ "SigType" SG_ 2364708862 TMSHVInputPwr 1;
BA_ "SPN" SG_ 2364708862 TMSHVInputPwr 15938;
BA_ "SigType" SG_ 2364708862 TMSSLIInputPwr 1;
BA_ "SPN" SG_ 2364708862 TMSSLIInputPwr 15937;
BA_ "SigType" SG_ 2364708606 Module32OperationalStatus 5;
BA_ "SPN" SG_ 2364708606 Module32OperationalStatus 15936;
BA_ "SigType" SG_ 2364708606 Module31OperationalStatus 5;
BA_ "SPN" SG_ 2364708606 Module31OperationalStatus 15935;
BA_ "SigType" SG_ 2364708606 Module30OperationalStatus 5;
BA_ "SPN" SG_ 2364708606 Module30OperationalStatus 15934;
BA_ "SigType" SG_ 2364708606 Module29OperationalStatus 5;
BA_ "SPN" SG_ 2364708606 Module29OperationalStatus 15933;
BA_ "SigType" SG_ 2364708606 Module28OperationalStatus 5;
BA_ "SPN" SG_ 2364708606 Module28OperationalStatus 15932;
BA_ "SigType" SG_ 2364708606 Module27OperationalStatus 5;
BA_ "SPN" SG_ 2364708606 Module27OperationalStatus 15931;
BA_ "SigType" SG_ 2364708606 Module26OperationalStatus 5;
BA_ "SPN" SG_ 2364708606 Module26OperationalStatus 15930;
BA_ "SigType" SG_ 2364708606 Module25OperationalStatus 5;
BA_ "SPN" SG_ 2364708606 Module25OperationalStatus 15929;
BA_ "SigType" SG_ 2364708606 Module24OperationalStatus 5;
BA_ "SPN" SG_ 2364708606 Module24OperationalStatus 15928;
BA_ "SigType" SG_ 2364708606 Module23OperationalStatus 5;
BA_ "SPN" SG_ 2364708606 Module23OperationalStatus 15927;
BA_ "SigType" SG_ 2364708606 Module22OperationalStatus 5;
BA_ "SPN" SG_ 2364708606 Module22OperationalStatus 15926;
BA_ "SigType" SG_ 2364708606 Module21OperationalStatus 5;
BA_ "SPN" SG_ 2364708606 Module21OperationalStatus 15925;
BA_ "SigType" SG_ 2364708606 Module20OperationalStatus 5;
BA_ "SPN" SG_ 2364708606 Module20OperationalStatus 15924;
BA_ "SigType" SG_ 2364708606 Module19OperationalStatus 5;
BA_ "SPN" SG_ 2364708606 Module19OperationalStatus 15923;
BA_ "SigType" SG_ 2364708606 Module18OperationalStatus 5;
BA_ "SPN" SG_ 2364708606 Module18OperationalStatus 15922;
BA_ "SigType" SG_ 2364708606 Module17OperationalStatus 5;
BA_ "SPN" SG_ 2364708606 Module17OperationalStatus 15921;
BA_ "SigType" SG_ 2364708606 Module16OperationalStatus 5;
BA_ "SPN" SG_ 2364708606 Module16OperationalStatus 15920;
BA_ "SigType" SG_ 2364708606 Module15OperationalStatus 5;
BA_ "SPN" SG_ 2364708606 Module15OperationalStatus 15919;
BA_ "SigType" SG_ 2364708606 Module14OperationalStatus 5;
BA_ "SPN" SG_ 2364708606 Module14OperationalStatus 15918;
BA_ "SigType" SG_ 2364708606 Module13OperationalStatus 5;
BA_ "SPN" SG_ 2364708606 Module13OperationalStatus 15917;
BA_ "SigType" SG_ 2364708606 Module12OperationalStatus 5;
BA_ "SPN" SG_ 2364708606 Module12OperationalStatus 15916;
BA_ "SigType" SG_ 2364708606 Module11OperationalStatus 5;
BA_ "SPN" SG_ 2364708606 Module11OperationalStatus 15915;
BA_ "SigType" SG_ 2364708606 Module10OperationalStatus 5;
BA_ "SPN" SG_ 2364708606 Module10OperationalStatus 15914;
BA_ "SigType" SG_ 2364708606 Module9OperationalStatus 5;
BA_ "SPN" SG_ 2364708606 Module9OperationalStatus 15913;
BA_ "SigType" SG_ 2364708606 Module8OperationalStatus 5;
BA_ "SPN" SG_ 2364708606 Module8OperationalStatus 15912;
BA_ "SigType" SG_ 2364708606 Module7OperationalStatus 5;
BA_ "SPN" SG_ 2364708606 Module7OperationalStatus 15911;
BA_ "SigType" SG_ 2364708606 Module6OperationalStatus 5;
BA_ "SPN" SG_ 2364708606 Module6OperationalStatus 15910;
BA_ "SigType" SG_ 2364708606 Module5OperationalStatus 5;
BA_ "SPN" SG_ 2364708606 Module5OperationalStatus 15909;
BA_ "SigType" SG_ 2364708606 Module4OperationalStatus 5;
BA_ "SPN" SG_ 2364708606 Module4OperationalStatus 15908;
BA_ "SigType" SG_ 2364708606 Module3OperationalStatus 5;
BA_ "SPN" SG_ 2364708606 Module3OperationalStatus 15907;
BA_ "SigType" SG_ 2364708606 Module2OperationalStatus 5;
BA_ "SPN" SG_ 2364708606 Module2OperationalStatus 15906;
BA_ "SigType" SG_ 2364708606 Module1OperationalStatus 5;
BA_ "SPN" SG_ 2364708606 Module1OperationalStatus 15905;
BA_ "SigType" SG_ 2364708350 MaxChargeVLmt 1;
BA_ "SPN" SG_ 2364708350 MaxChargeVLmt 15904;
BA_ "SPN" SG_ 2364708350 ChargeEnergyCapacity 15903;
BA_ "SPN" SG_ 2364708350 DisEnergyCapacity 15902;
BA_ "SigType" SG_ 2364708094 Status1CRC 12;
BA_ "SPN" SG_ 2364708094 Status1CRC 15901;
BA_ "SigType" SG_ 2364708094 Status1Counter 11;
BA_ "SPN" SG_ 2364708094 Status1Counter 15900;
BA_ "SPN" SG_ 2364708094 OperationalStatus 15899;
BA_ "SPN" SG_ 2364708094 HVBusConnectionStatus 15898;
BA_ "SigType" SG_ 2364708094 InternalChargerStatus 5;
BA_ "SPN" SG_ 2364708094 InternalChargerStatus 15897;
BA_ "SigType" SG_ 2364708094 CellBalancingActive 4;
BA_ "SPN" SG_ 2364708094 CellBalancingActive 15896;
BA_ "SigType" SG_ 2364708094 CellBalanceStatus 4;
BA_ "SPN" SG_ 2364708094 CellBalanceStatus 15895;
BA_ "SPN" SG_ 2364708094 StOfChargeStatus 15894;
BA_ "SigType" SG_ 2364708094 InertiaSwStatus 4;
BA_ "SPN" SG_ 2364708094 InertiaSwStatus 15893;
BA_ "SigType" SG_ 2364708094 HVILStatus 4;
BA_ "SPN" SG_ 2364708094 HVILStatus 15892;
BA_ "SPN" SG_ 2364708094 HVBusPassiveIsolTestStatus 15891;
BA_ "SPN" SG_ 2364708094 HVBusActiveIsolTestStatus 15890;
BA_ "SigType" SG_ 2364708094 CenterOfPackContactorSt 4;
BA_ "SPN" SG_ 2364708094 CenterOfPackContactorSt 15889;
BA_ "SigType" SG_ 2364708094 HVBusPreChargeRelaySt 4;
BA_ "SPN" SG_ 2364708094 HVBusPreChargeRelaySt 15888;
BA_ "SPN" SG_ 2364708094 HVBusDisconnectForewarning 15887;
BA_ "SigType" SG_ 2364708094 HVBusContactorSt15886 4;
BA_ "SPN" SG_ 2364708094 HVBusContactorSt15886 15886;
BA_ "SigType" SG_ 2364708094 HVBusContactorSt 4;
BA_ "SPN" SG_ 2364708094 HVBusContactorSt 15885;
BA_ "SigType" SG_ 2364707838 Temp 1;
BA_ "SPN" SG_ 2364707838 Temp 15884;
BA_ "SigType" SG_ 2364707838 ETemp 1;
BA_ "SPN" SG_ 2364707838 ETemp 15883;
BA_ "SigType" SG_ 2364707838 OutCoolantTemp 1;
BA_ "SPN" SG_ 2364707838 OutCoolantTemp 15882;
BA_ "SigType" SG_ 2364707838 InCoolantTemp 1;
BA_ "SPN" SG_ 2364707838 InCoolantTemp 15881;
BA_ "SigType" SG_ 2364707838 IgntV 1;
BA_ "SPN" SG_ 2364707838 IgntV 15880;
BA_ "SigType" SG_ 2364707838 BusV 1;
BA_ "SPN" SG_ 2364707838 BusV 15879;
BA_ "SigType" SG_ 2364707582 HighestCellStOfCharge 1;
BA_ "SPN" SG_ 2364707582 HighestCellStOfCharge 15878;
BA_ "SigType" SG_ 2364707582 LowestCellStOfCharge 1;
BA_ "SPN" SG_ 2364707582 LowestCellStOfCharge 15877;
BA_ "SigType" SG_ 2364707582 ChargeCurLmt 1;
BA_ "GenSigStartValue" SG_ 2364707582 ChargeCurLmt 32000;
BA_ "SPN" SG_ 2364707582 ChargeCurLmt 15876;
BA_ "SigType" SG_ 2364707582 DisCurLmt 1;
BA_ "SPN" SG_ 2364707582 DisCurLmt 15875;
BA_ "SigType" SG_ 2364707326 CellBalancingCount 1;
BA_ "SPN" SG_ 2364707326 CellBalancingCount 15874;
BA_ "SigType" SG_ 2364707326 ChargeCapacity 1;
BA_ "SPN" SG_ 2364707326 ChargeCapacity 15873;
BA_ "SigType" SG_ 2364707326 DisCapacity 1;
BA_ "SPN" SG_ 2364707326 DisCapacity 15872;
BA_ "SigType" SG_ 2364707070 CellTempDiffStatus 4;
BA_ "SPN" SG_ 2364707070 CellTempDiffStatus 15871;
BA_ "SigType" SG_ 2364707070 AvgCellTemp 1;
BA_ "SPN" SG_ 2364707070 AvgCellTemp 15870;
BA_ "SigType" SG_ 2364707070 LowestCellTemp 1;
BA_ "SPN" SG_ 2364707070 LowestCellTemp 15869;
BA_ "SigType" SG_ 2364707070 HighestCellTemp 1;
BA_ "SPN" SG_ 2364707070 HighestCellTemp 15868;
BA_ "SPN" SG_ 2364706814 CellVDiffStatus 15867;
BA_ "SigType" SG_ 2364706814 LowestCellV 1;
BA_ "SPN" SG_ 2364706814 LowestCellV 15866;
BA_ "SigType" SG_ 2364706814 HighestCellV 1;
BA_ "SPN" SG_ 2364706814 HighestCellV 15865;
BA_ "SigType" SG_ 2364706814 FastUpdateStOfCharge 1;
BA_ "SPN" SG_ 2364706814 FastUpdateStOfCharge 15864;
BA_ "SigType" SG_ 2364706558 Cur 1;
BA_ "SPN" SG_ 2364706558 Cur 15863;
BA_ "SigType" SG_ 2364706558 Lvl 1;
BA_ "SPN" SG_ 2364706558 Lvl 15862;
BA_ "SigType" SG_ 2364706558 AvailableChargePwr 1;
BA_ "SPN" SG_ 2364706558 AvailableChargePwr 15861;
BA_ "SigType" SG_ 2364706558 AvailableDisPwr 1;
BA_ "SPN" SG_ 2364706558 AvailableDisPwr 15860;
BA_ "SigType" SG_ 2364706302 ChargePLDueToAnUndefinedCause 4;
BA_ "SPN" SG_ 2364706302 ChargePLDueToAnUndefinedCause 15859;
BA_ "SigType" SG_ 2364706302 ChargePLDueToBatCur 4;
BA_ "SPN" SG_ 2364706302 ChargePLDueToBatCur 15858;
BA_ "SigType" SG_ 2364706302 ChargePLDueToBatOrCellV 4;
BA_ "SPN" SG_ 2364706302 ChargePLDueToBatOrCellV 15857;
BA_ "SigType" SG_ 2364706302 ChargePLDueToBatDiagCondition 4;
BA_ "SPN" SG_ 2364706302 ChargePLDueToBatDiagCondition 15856;
BA_ "SigType" SG_ 2364706302 ChargePLDueToBatTemp 4;
BA_ "SPN" SG_ 2364706302 ChargePLDueToBatTemp 15855;
BA_ "SigType" SG_ 2364706302 ChargePLDueToStOfCharge 4;
BA_ "SPN" SG_ 2364706302 ChargePLDueToStOfCharge 15854;
BA_ "SigType" SG_ 2364706302 DisPLDueToAnUndefinedCause 4;
BA_ "SPN" SG_ 2364706302 DisPLDueToAnUndefinedCause 15853;
BA_ "SigType" SG_ 2364706302 DisPLDueToBatCur 4;
BA_ "SPN" SG_ 2364706302 DisPLDueToBatCur 15852;
BA_ "SigType" SG_ 2364706302 DisPLDueToBatOrCellV 4;
BA_ "SPN" SG_ 2364706302 DisPLDueToBatOrCellV 15851;
BA_ "SigType" SG_ 2364706302 DisPLDueToBatDiagCondition 4;
BA_ "SPN" SG_ 2364706302 DisPLDueToBatDiagCondition 15850;
BA_ "SigType" SG_ 2364706302 DisPLDueToBatTemp 4;
BA_ "SPN" SG_ 2364706302 DisPLDueToBatTemp 15849;
BA_ "SigType" SG_ 2364706302 DisPLDueToStOfCharge 4;
BA_ "SPN" SG_ 2364706302 DisPLDueToStOfCharge 15848;
BA_ "SigType" SG_ 2364706046 ActualChargeRate 1;
BA_ "SPN" SG_ 2364706046 ActualChargeRate 15820;
BA_ "SigType" SG_ 2364706046 LvlNegToChassisGroundV 1;
BA_ "SPN" SG_ 2364706046 LvlNegToChassisGroundV 15819;
BA_ "SigType" SG_ 2364706046 BusVNegToChassisGroundV 1;
BA_ "SPN" SG_ 2364706046 BusVNegToChassisGroundV 15818;
BA_ "SigType" SG_ 2364705790 HVBusPassiveIsolTestResults 1;
BA_ "SPN" SG_ 2364705790 HVBusPassiveIsolTestResults 15817;
BA_ "SigType" SG_ 2364705790 HVBusActiveIsolTestResults 1;
BA_ "SPN" SG_ 2364705790 HVBusActiveIsolTestResults 15816;
BA_ "SigType" SG_ 2364705790 LowestCellStOfChargeCellNum 1;
BA_ "SPN" SG_ 2364705790 LowestCellStOfChargeCellNum 15815;
BA_ "SigType" SG_ 2364705790 LowestCellStOfChargeModuleNum 1;
BA_ "SPN" SG_ 2364705790 LowestCellStOfChargeModuleNum 15814;
BA_ "SigType" SG_ 2364705790 HighestCellStOfChargeCellNum 1;
BA_ "SPN" SG_ 2364705790 HighestCellStOfChargeCellNum 15813;
BA_ "SigType" SG_ 2364705790 HighestCellStOfChargeModuleNum 1;
BA_ "SPN" SG_ 2364705790 HighestCellStOfChargeModuleNum 15812;
BA_ "SigType" SG_ 2364705534 Data9CRC 12;
BA_ "SPN" SG_ 2364705534 Data9CRC 23015;
BA_ "SigType" SG_ 2364705534 Data9Counter 11;
BA_ "SPN" SG_ 2364705534 Data9Counter 23014;
BA_ "SigType" SG_ 2364705534 Data9EmbeddedIntegritySupport 5;
BA_ "SPN" SG_ 2364705534 Data9EmbeddedIntegritySupport 23013;
BA_ "SigType" SG_ 2364705534 HVESS14ThermalEventDetected 4;
BA_ "SPN" SG_ 2364705534 HVESS14ThermalEventDetected 21301;
BA_ "SigType" SG_ 2364705534 LowestCellTempCellNum 1;
BA_ "SPN" SG_ 2364705534 LowestCellTempCellNum 15811;
BA_ "SigType" SG_ 2364705534 LowestCellTempModuleNum 1;
BA_ "SPN" SG_ 2364705534 LowestCellTempModuleNum 15810;
BA_ "SigType" SG_ 2364705534 HighestCellTempCellNum 1;
BA_ "SPN" SG_ 2364705534 HighestCellTempCellNum 15809;
BA_ "SigType" SG_ 2364705534 HighestCellTempModuleNum 1;
BA_ "SPN" SG_ 2364705534 HighestCellTempModuleNum 15808;
BA_ "SigType" SG_ 2364705278 AvgCellV 1;
BA_ "SPN" SG_ 2364705278 AvgCellV 15807;
BA_ "SigType" SG_ 2364705278 LowestCellVCellNum 1;
BA_ "SPN" SG_ 2364705278 LowestCellVCellNum 15806;
BA_ "SigType" SG_ 2364705278 LowestCellVModuleNum 1;
BA_ "SPN" SG_ 2364705278 LowestCellVModuleNum 15805;
BA_ "SigType" SG_ 2364705278 HighestCellVCellNum 1;
BA_ "SPN" SG_ 2364705278 HighestCellVCellNum 15804;
BA_ "SigType" SG_ 2364705278 HighestCellVModuleNum 1;
BA_ "SPN" SG_ 2364705278 HighestCellVModuleNum 15803;
BA_ "SigType" SG_ 2364705022 TMSCoolantLvl 4;
BA_ "SPN" SG_ 2364705022 TMSCoolantLvl 15802;
BA_ "SPN" SG_ 2364705022 TMSMode 15801;
BA_ "SigType" SG_ 2364705022 TMSHVILStatus 4;
BA_ "SPN" SG_ 2364705022 TMSHVILStatus 15800;
BA_ "SigType" SG_ 2364705022 TMSHtrStatus 5;
BA_ "SPN" SG_ 2364705022 TMSHtrStatus 15799;
BA_ "SigType" SG_ 2364705022 TMSRelHumidty 1;
BA_ "SPN" SG_ 2364705022 TMSRelHumidty 15798;
BA_ "SigType" SG_ 2364705022 TMSCompressorSpd 1;
BA_ "SPN" SG_ 2364705022 TMSCompressorSpd 15797;
BA_ "SigType" SG_ 2364705022 TMSHVInputPwr 1;
BA_ "SPN" SG_ 2364705022 TMSHVInputPwr 15796;
BA_ "SigType" SG_ 2364705022 TMSSLIInputPwr 1;
BA_ "SPN" SG_ 2364705022 TMSSLIInputPwr 15795;
BA_ "SigType" SG_ 2364704766 Module32OperationalStatus 5;
BA_ "SPN" SG_ 2364704766 Module32OperationalStatus 15794;
BA_ "SigType" SG_ 2364704766 Module31OperationalStatus 5;
BA_ "SPN" SG_ 2364704766 Module31OperationalStatus 15793;
BA_ "SigType" SG_ 2364704766 Module30OperationalStatus 5;
BA_ "SPN" SG_ 2364704766 Module30OperationalStatus 15792;
BA_ "SigType" SG_ 2364704766 Module29OperationalStatus 5;
BA_ "SPN" SG_ 2364704766 Module29OperationalStatus 15791;
BA_ "SigType" SG_ 2364704766 Module28OperationalStatus 5;
BA_ "SPN" SG_ 2364704766 Module28OperationalStatus 15790;
BA_ "SigType" SG_ 2364704766 Module27OperationalStatus 5;
BA_ "SPN" SG_ 2364704766 Module27OperationalStatus 15789;
BA_ "SigType" SG_ 2364704766 Module26OperationalStatus 5;
BA_ "SPN" SG_ 2364704766 Module26OperationalStatus 15788;
BA_ "SigType" SG_ 2364704766 Module25OperationalStatus 5;
BA_ "SPN" SG_ 2364704766 Module25OperationalStatus 15787;
BA_ "SigType" SG_ 2364704766 Module24OperationalStatus 5;
BA_ "SPN" SG_ 2364704766 Module24OperationalStatus 15786;
BA_ "SigType" SG_ 2364704766 Module23OperationalStatus 5;
BA_ "SPN" SG_ 2364704766 Module23OperationalStatus 15785;
BA_ "SigType" SG_ 2364704766 Module22OperationalStatus 5;
BA_ "SPN" SG_ 2364704766 Module22OperationalStatus 15784;
BA_ "SigType" SG_ 2364704766 Module21OperationalStatus 5;
BA_ "SPN" SG_ 2364704766 Module21OperationalStatus 15783;
BA_ "SigType" SG_ 2364704766 Module20OperationalStatus 5;
BA_ "SPN" SG_ 2364704766 Module20OperationalStatus 15782;
BA_ "SigType" SG_ 2364704766 Module19OperationalStatus 5;
BA_ "SPN" SG_ 2364704766 Module19OperationalStatus 15781;
BA_ "SigType" SG_ 2364704766 Module18OperationalStatus 5;
BA_ "SPN" SG_ 2364704766 Module18OperationalStatus 15780;
BA_ "SigType" SG_ 2364704766 Module17OperationalStatus 5;
BA_ "SPN" SG_ 2364704766 Module17OperationalStatus 15779;
BA_ "SigType" SG_ 2364704766 Module16OperationalStatus 5;
BA_ "SPN" SG_ 2364704766 Module16OperationalStatus 15778;
BA_ "SigType" SG_ 2364704766 Module15OperationalStatus 5;
BA_ "SPN" SG_ 2364704766 Module15OperationalStatus 15777;
BA_ "SigType" SG_ 2364704766 Module14OperationalStatus 5;
BA_ "SPN" SG_ 2364704766 Module14OperationalStatus 15776;
BA_ "SigType" SG_ 2364704766 Module13OperationalStatus 5;
BA_ "SPN" SG_ 2364704766 Module13OperationalStatus 15775;
BA_ "SigType" SG_ 2364704766 Module12OperationalStatus 5;
BA_ "SPN" SG_ 2364704766 Module12OperationalStatus 15774;
BA_ "SigType" SG_ 2364704766 Module11OperationalStatus 5;
BA_ "SPN" SG_ 2364704766 Module11OperationalStatus 15773;
BA_ "SigType" SG_ 2364704766 Module10OperationalStatus 5;
BA_ "SPN" SG_ 2364704766 Module10OperationalStatus 15772;
BA_ "SigType" SG_ 2364704766 Module9OperationalStatus 5;
BA_ "SPN" SG_ 2364704766 Module9OperationalStatus 15771;
BA_ "SigType" SG_ 2364704766 Module8OperationalStatus 5;
BA_ "SPN" SG_ 2364704766 Module8OperationalStatus 15770;
BA_ "SigType" SG_ 2364704766 Module7OperationalStatus 5;
BA_ "SPN" SG_ 2364704766 Module7OperationalStatus 15769;
BA_ "SigType" SG_ 2364704766 Module6OperationalStatus 5;
BA_ "SPN" SG_ 2364704766 Module6OperationalStatus 15768;
BA_ "SigType" SG_ 2364704766 Module5OperationalStatus 5;
BA_ "SPN" SG_ 2364704766 Module5OperationalStatus 15767;
BA_ "SigType" SG_ 2364704766 Module4OperationalStatus 5;
BA_ "SPN" SG_ 2364704766 Module4OperationalStatus 15766;
BA_ "SigType" SG_ 2364704766 Module3OperationalStatus 5;
BA_ "SPN" SG_ 2364704766 Module3OperationalStatus 15765;
BA_ "SigType" SG_ 2364704766 Module2OperationalStatus 5;
BA_ "SPN" SG_ 2364704766 Module2OperationalStatus 15764;
BA_ "SigType" SG_ 2364704766 Module1OperationalStatus 5;
BA_ "SPN" SG_ 2364704766 Module1OperationalStatus 15763;
BA_ "SigType" SG_ 2364704510 MaxChargeVLmt 1;
BA_ "SPN" SG_ 2364704510 MaxChargeVLmt 15762;
BA_ "SPN" SG_ 2364704510 ChargeEnergyCapacity 15761;
BA_ "SPN" SG_ 2364704510 DisEnergyCapacity 15760;
BA_ "SigType" SG_ 2364704254 Status1CRC 12;
BA_ "SPN" SG_ 2364704254 Status1CRC 15759;
BA_ "SigType" SG_ 2364704254 Status1Counter 11;
BA_ "SPN" SG_ 2364704254 Status1Counter 15758;
BA_ "SPN" SG_ 2364704254 OperationalStatus 15757;
BA_ "SPN" SG_ 2364704254 HVBusConnectionStatus 15756;
BA_ "SigType" SG_ 2364704254 InternalChargerStatus 5;
BA_ "SPN" SG_ 2364704254 InternalChargerStatus 15755;
BA_ "SigType" SG_ 2364704254 CellBalancingActive 4;
BA_ "SPN" SG_ 2364704254 CellBalancingActive 15754;
BA_ "SigType" SG_ 2364704254 CellBalanceStatus 4;
BA_ "SPN" SG_ 2364704254 CellBalanceStatus 15753;
BA_ "SPN" SG_ 2364704254 StOfChargeStatus 15752;
BA_ "SigType" SG_ 2364704254 InertiaSwStatus 4;
BA_ "SPN" SG_ 2364704254 InertiaSwStatus 15751;
BA_ "SigType" SG_ 2364704254 HVILStatus 4;
BA_ "SPN" SG_ 2364704254 HVILStatus 15750;
BA_ "SPN" SG_ 2364704254 HVBusPassiveIsolTestStatus 15749;
BA_ "SPN" SG_ 2364704254 HVBusActiveIsolTestStatus 15748;
BA_ "SigType" SG_ 2364704254 CenterOfPackContactorSt 4;
BA_ "SPN" SG_ 2364704254 CenterOfPackContactorSt 15747;
BA_ "SigType" SG_ 2364704254 HVBusPreChargeRelaySt 4;
BA_ "SPN" SG_ 2364704254 HVBusPreChargeRelaySt 15746;
BA_ "SPN" SG_ 2364704254 HVBusDisconnectForewarning 15745;
BA_ "SigType" SG_ 2364704254 HVBusContactorSt15744 4;
BA_ "SPN" SG_ 2364704254 HVBusContactorSt15744 15744;
BA_ "SigType" SG_ 2364704254 HVBusContactorSt 4;
BA_ "SPN" SG_ 2364704254 HVBusContactorSt 15743;
BA_ "SigType" SG_ 2364703998 Temp 1;
BA_ "SPN" SG_ 2364703998 Temp 15742;
BA_ "SigType" SG_ 2364703998 ETemp 1;
BA_ "SPN" SG_ 2364703998 ETemp 15741;
BA_ "SigType" SG_ 2364703998 OutCoolantTemp 1;
BA_ "SPN" SG_ 2364703998 OutCoolantTemp 15740;
BA_ "SigType" SG_ 2364703998 InCoolantTemp 1;
BA_ "SPN" SG_ 2364703998 InCoolantTemp 15739;
BA_ "SigType" SG_ 2364703998 IgntV 1;
BA_ "SPN" SG_ 2364703998 IgntV 15738;
BA_ "SigType" SG_ 2364703998 BusV 1;
BA_ "SPN" SG_ 2364703998 BusV 15737;
BA_ "SigType" SG_ 2364703742 HighestCellStOfCharge 1;
BA_ "SPN" SG_ 2364703742 HighestCellStOfCharge 15736;
BA_ "SigType" SG_ 2364703742 LowestCellStOfCharge 1;
BA_ "SPN" SG_ 2364703742 LowestCellStOfCharge 15735;
BA_ "SigType" SG_ 2364703742 ChargeCurLmt 1;
BA_ "GenSigStartValue" SG_ 2364703742 ChargeCurLmt 32000;
BA_ "SPN" SG_ 2364703742 ChargeCurLmt 15734;
BA_ "SigType" SG_ 2364703742 DisCurLmt 1;
BA_ "SPN" SG_ 2364703742 DisCurLmt 15733;
BA_ "SigType" SG_ 2364703486 CellBalancingCount 1;
BA_ "SPN" SG_ 2364703486 CellBalancingCount 15732;
BA_ "SigType" SG_ 2364703486 ChargeCapacity 1;
BA_ "SPN" SG_ 2364703486 ChargeCapacity 15731;
BA_ "SigType" SG_ 2364703486 DisCapacity 1;
BA_ "SPN" SG_ 2364703486 DisCapacity 15730;
BA_ "SigType" SG_ 2364703230 CellTempDiffStatus 4;
BA_ "SPN" SG_ 2364703230 CellTempDiffStatus 15729;
BA_ "SigType" SG_ 2364703230 AvgCellTemp 1;
BA_ "SPN" SG_ 2364703230 AvgCellTemp 15728;
BA_ "SigType" SG_ 2364703230 LowestCellTemp 1;
BA_ "SPN" SG_ 2364703230 LowestCellTemp 15727;
BA_ "SigType" SG_ 2364703230 HighestCellTemp 1;
BA_ "SPN" SG_ 2364703230 HighestCellTemp 15726;
BA_ "SPN" SG_ 2364702974 CellVDiffStatus 15725;
BA_ "SigType" SG_ 2364702974 LowestCellV 1;
BA_ "SPN" SG_ 2364702974 LowestCellV 15724;
BA_ "SigType" SG_ 2364702974 HighestCellV 1;
BA_ "SPN" SG_ 2364702974 HighestCellV 15723;
BA_ "SigType" SG_ 2364702974 FastUpdateStOfCharge 1;
BA_ "SPN" SG_ 2364702974 FastUpdateStOfCharge 15722;
BA_ "SigType" SG_ 2364702718 Cur 1;
BA_ "SPN" SG_ 2364702718 Cur 15721;
BA_ "SigType" SG_ 2364702718 Lvl 1;
BA_ "SPN" SG_ 2364702718 Lvl 15720;
BA_ "SigType" SG_ 2364702718 AvailableChargePwr 1;
BA_ "SPN" SG_ 2364702718 AvailableChargePwr 15719;
BA_ "SigType" SG_ 2364702718 AvailableDisPwr 1;
BA_ "SPN" SG_ 2364702718 AvailableDisPwr 15718;
BA_ "SigType" SG_ 2364702462 ChargePLDueToAnUndefinedCause 4;
BA_ "SPN" SG_ 2364702462 ChargePLDueToAnUndefinedCause 15717;
BA_ "SigType" SG_ 2364702462 ChargePLDueToBatCur 4;
BA_ "SPN" SG_ 2364702462 ChargePLDueToBatCur 15716;
BA_ "SigType" SG_ 2364702462 ChargePLDueToBatOrCellV 4;
BA_ "SPN" SG_ 2364702462 ChargePLDueToBatOrCellV 15715;
BA_ "SigType" SG_ 2364702462 ChargePLDueToBatDiagCondition 4;
BA_ "SPN" SG_ 2364702462 ChargePLDueToBatDiagCondition 15714;
BA_ "SigType" SG_ 2364702462 ChargePLDueToBatTemp 4;
BA_ "SPN" SG_ 2364702462 ChargePLDueToBatTemp 15713;
BA_ "SigType" SG_ 2364702462 ChargePLDueToStOfCharge 4;
BA_ "SPN" SG_ 2364702462 ChargePLDueToStOfCharge 15712;
BA_ "SigType" SG_ 2364702462 DisPLDueToAnUndefinedCause 4;
BA_ "SPN" SG_ 2364702462 DisPLDueToAnUndefinedCause 15711;
BA_ "SigType" SG_ 2364702462 DisPLDueToBatCur 4;
BA_ "SPN" SG_ 2364702462 DisPLDueToBatCur 15710;
BA_ "SigType" SG_ 2364702462 DisPLDueToBatOrCellV 4;
BA_ "SPN" SG_ 2364702462 DisPLDueToBatOrCellV 15709;
BA_ "SigType" SG_ 2364702462 DisPLDueToBatDiagCondition 4;
BA_ "SPN" SG_ 2364702462 DisPLDueToBatDiagCondition 15708;
BA_ "SigType" SG_ 2364702462 DisPLDueToBatTemp 4;
BA_ "SPN" SG_ 2364702462 DisPLDueToBatTemp 15707;
BA_ "SigType" SG_ 2364702462 DisPLDueToStOfCharge 4;
BA_ "SPN" SG_ 2364702462 DisPLDueToStOfCharge 15706;
BA_ "SigType" SG_ 2364702206 ActualChargeRate 1;
BA_ "SPN" SG_ 2364702206 ActualChargeRate 15678;
BA_ "SigType" SG_ 2364702206 LvlNegToChassisGroundV 1;
BA_ "SPN" SG_ 2364702206 LvlNegToChassisGroundV 15677;
BA_ "SigType" SG_ 2364702206 BusVNegToChassisGroundV 1;
BA_ "SPN" SG_ 2364702206 BusVNegToChassisGroundV 15676;
VAL_ 2364712446 Module32OperationalStatus 3 "Not Available" 2 "Error" 1 "Operational" 0 "Not Operational" ;
VAL_ 2364712446 Module31OperationalStatus 3 "Not Available" 2 "Error" 1 "Operational" 0 "Not Operational" ;
VAL_ 2364712446 Module30OperationalStatus 3 "Not Available" 2 "Error" 1 "Operational" 0 "Not Operational" ;
VAL_ 2364712446 Module29OperationalStatus 3 "Not Available" 2 "Error" 1 "Operational" 0 "Not Operational" ;
VAL_ 2364712446 Module28OperationalStatus 3 "Not Available" 2 "Error" 1 "Operational" 0 "Not Operational" ;
VAL_ 2364712446 Module27OperationalStatus 3 "Not Available" 2 "Error" 1 "Operational" 0 "Not Operational" ;
VAL_ 2364712446 Module26OperationalStatus 3 "Not Available" 2 "Error" 1 "Operational" 0 "Not Operational" ;
VAL_ 2364712446 Module25OperationalStatus 3 "Not Available" 2 "Error" 1 "Operational" 0 "Not Operational" ;
VAL_ 2364712446 Module24OperationalStatus 3 "Not Available" 2 "Error" 1 "Operational" 0 "Not Operational" ;
VAL_ 2364712446 Module23OperationalStatus 3 "Not Available" 2 "Error" 1 "Operational" 0 "Not Operational" ;
VAL_ 2364712446 Module22OperationalStatus 3 "Not Available" 2 "Error" 1 "Operational" 0 "Not Operational" ;
VAL_ 2364712446 Module21OperationalStatus 3 "Not Available" 2 "Error" 1 "Operational" 0 "Not Operational" ;
VAL_ 2364712446 Module20OperationalStatus 3 "Not Available" 2 "Error" 1 "Operational" 0 "Not Operational" ;
VAL_ 2364712446 Module19OperationalStatus 3 "Not Available" 2 "Error" 1 "Operational" 0 "Not Operational" ;
VAL_ 2364712446 Module18OperationalStatus 3 "Not Available" 2 "Error" 1 "Operational" 0 "Not Operational" ;
VAL_ 2364712446 Module17OperationalStatus 3 "Not Available" 2 "Error" 1 "Operational" 0 "Not Operational" ;
VAL_ 2364712446 Module16OperationalStatus 3 "Not Available" 2 "Error" 1 "Operational" 0 "Not Operational" ;
VAL_ 2364712446 Module15OperationalStatus 3 "Not Available" 2 "Error" 1 "Operational" 0 "Not Operational" ;
VAL_ 2364712446 Module14OperationalStatus 3 "Not Available" 2 "Error" 1 "Operational" 0 "Not Operational" ;
VAL_ 2364712446 Module13OperationalStatus 3 "Not Available" 2 "Error" 1 "Operational" 0 "Not Operational" ;
VAL_ 2364712446 Module12OperationalStatus 3 "Not Available" 2 "Error" 1 "Operational" 0 "Not Operational" ;
VAL_ 2364712446 Module11OperationalStatus 3 "Not Available" 2 "Error" 1 "Operational" 0 "Not Operational" ;
VAL_ 2364712446 Module10OperationalStatus 3 "Not Available" 2 "Error" 1 "Operational" 0 "Not Operational" ;
VAL_ 2364712446 Module9OperationalStatus 3 "Not Available" 2 "Error" 1 "Operational" 0 "Not Operational" ;
VAL_ 2364712446 Module8OperationalStatus 3 "Not Available" 2 "Error" 1 "Operational" 0 "Not Operational" ;
VAL_ 2364712446 Module7OperationalStatus 3 "Not Available" 2 "Error" 1 "Operational" 0 "Not Operational" ;
VAL_ 2364712446 Module6OperationalStatus 3 "Not Available" 2 "Error" 1 "Operational" 0 "Not Operational" ;
VAL_ 2364712446 Module5OperationalStatus 3 "Not Available" 2 "Error" 1 "Operational" 0 "Not Operational" ;
VAL_ 2364712446 Module4OperationalStatus 3 "Not Available" 2 "Error" 1 "Operational" 0 "Not Operational" ;
VAL_ 2364712446 Module3OperationalStatus 3 "Not Available" 2 "Error" 1 "Operational" 0 "Not Operational" ;
VAL_ 2364712446 Module2OperationalStatus 3 "Not Available" 2 "Error" 1 "Operational" 0 "Not Operational" ;
VAL_ 2364712446 Module1OperationalStatus 3 "Not Available" 2 "Error" 1 "Operational" 0 "Not Operational" ;
VAL_ 2364711934 OperationalStatus 15 "Not Available" 14 "Error" 13 "Reserved" 12 "Reserved" 11 "Reserved" 10 "Reserved" 9 "Reserved" 8 "Reserved" 7 "Reserved" 6 "Disabled by internal decision of HVES controller" 5 "Disabled by external command" 4 "Emergency Power-Down In Process" 3 "Normal Power-Down in Process" 2 "Operational." 1 "Initialization Complete" 0 "Initialization in process" ;
VAL_ 2364711934 HVBusConnectionStatus 15 "Not Available" 14 "Error" 13 "Reserved" 12 "Reserved" 11 "Reserved" 10 "Reserved" 9 "Reserved" 8 "Reserved" 7 "Reserved" 6 "Reserved" 5 "Reserved" 4 "Disconnected,  Precharge Failed" 3 "Disconnection in Process" 2 "Connection in Process" 1 "Connected" 0 "Disconnected, One or more contactors are open" ;
VAL_ 2364711934 InternalChargerStatus 3 "Not Available" 2 "Error" 1 "Charging on" 0 "Charging off" ;
VAL_ 2364711934 CellBalancingActive 3 "Not Available" 2 "Error" 1 "Cell balancing is active" 0 "Cell balancing is not active" ;
VAL_ 2364711934 CellBalanceStatus 3 "Not Available" 2 "Error" 1 "Cells are unbalanced" 0 "Cells are balanced" ;
VAL_ 2364711934 StOfChargeStatus 15 "Not  Available" 14 "Error" 13 "Reserved" 12 "Reserved" 11 "Reserved" 10 "Reserved" 9 "Reserved" 8 "Reserved" 7 "Reserved" 6 "SOC is above its recommended upper limit" 5 "SOC is at its recommended upper limit" 4 "SOC is approaching its recommended upper limit" 3 "SOC is below its recommended lower limit" 2 "SOC is at its recommended lower limit" 1 "SOC is approaching its recommended lower limit" 0 "SOC level is acceptable" ;
VAL_ 2364711934 InertiaSwStatus 3 "Not Available" 2 "Error" 1 "Impact sensed" 0 "No impact sensed" ;
VAL_ 2364711934 HVILStatus 3 "Not Available" 2 "Error" 1 "HVIL Open" 0 "HVIL Closed" ;
VAL_ 2364711934 HVBusPassiveIsolTestStatus 15 "Not available" 14 "Error" 13 "Reserved" 12 "Reserved" 11 "Reserved" 10 "Reserved" 9 "Reserved" 8 "Reserved" 7 "Reserved" 6 "Reserved" 5 "Test complete,  isolation fault" 4 "Test complete,  isolation marginal" 3 "Test complete,  isolation acceptable" 2 "Test in process" 1 "Test requested but not yet in process" 0 "No test requested / No test in process" ;
VAL_ 2364711934 HVBusActiveIsolTestStatus 15 "Not available" 14 "Error" 13 "Reserved" 12 "Reserved" 11 "Reserved" 10 "Reserved" 9 "Reserved" 8 "Reserved" 7 "Reserved" 6 "Reserved" 5 "Test complete,  isolation fault" 4 "Test complete,  isolation marginal" 3 "Test complete,  isolation acceptable" 2 "Test in process" 1 "Test requested but not yet in process" 0 "No test requested / No test in process" ;
VAL_ 2364711934 CenterOfPackContactorSt 3 "Not Available" 2 "Error" 1 "Contactor Closed" 0 "Contactor Open" ;
VAL_ 2364711934 HVBusPreChargeRelaySt 3 "Not Available" 2 "Error" 1 "Relay Closed" 0 "Relay Open" ;
VAL_ 2364711934 HVBusDisconnectForewarning 15 "Not Available" 14 "Error" 13 "Disconnect imminent" 12 "Reserved" 11 "Reserved" 10 "Reserved" 9 "Reserved" 8 "Reserved" 7 "Disconnect imminent due to battery pack current approaching maximum acceptable level" 6 "Disconnect imminent due to cell voltage approaching maximum acceptable level" 5 "Disconnect imminent due to cell voltage approaching minimum acceptable level" 4 "Disconnect imminent due to module voltage approaching maximum acceptable level" 3 "Disconnect imminent due to module voltage approaching minimum acceptable level" 2 "Disconnect imminent due to battery pack voltage approaching maximum acceptable level" 1 "Disconnect imminent due to battery pack voltage approaching minimum acceptable level" 0 "Disconnect not pending" ;
VAL_ 2364711934 HVBusContactorSt16028 3 "Not Available" 2 "Error" 1 "Contactor Closed" 0 "Contactor Open" ;
VAL_ 2364711934 HVBusContactorSt 3 "Not Available" 2 "Error" 1 "Contactor Closed" 0 "Contactor Open" ;
VAL_ 2364710910 CellTempDiffStatus 3 "Not Available" 2 "Error" 1 "Cell-to-cell temperature differential exceeds acceptable limits" 0 "Cell-to-cell temperature differential is within acceptable limits" ;
VAL_ 2364710654 CellVDiffStatus 15 "Not Available" 14 "Error" 13 "Reserved" 12 "Reserved" 11 "Reserved" 10 "Reserved" 9 "Reserved" 8 "Reserved" 7 "Reserved" 6 "Reserved" 5 "Reserved" 4 "Exceeds limits and it is not known whether balancing can restore performance" 3 "Exceeds limits and external maintenance balancing cannot restore performance" 2 "Exceeds limits and external maintenance balancing is required" 1 "Exceeds limits and can be corrected via auto-balancing" 0 "Is within acceptable limits" ;
VAL_ 2364710142 ChargePLDueToAnUndefinedCause 3 "Not Available" 2 "Error" 1 "Power limited for this reason" 0 "No power limit for this reason" ;
VAL_ 2364710142 ChargePLDueToBatCur 3 "Not Available" 2 "Error" 1 "Power limited for this reason" 0 "No power limit for this reason" ;
VAL_ 2364710142 ChargePLDueToBatOrCellV 3 "Not Available" 2 "Error" 1 "Power limited for this reason" 0 "No power limit for this reason" ;
VAL_ 2364710142 ChargePLDueToBatDiagCondition 3 "Not Available" 2 "Error" 1 "Power limited for this reason" 0 "No power limit for this reason" ;
VAL_ 2364710142 ChargePLDueToBatTemp 3 "Not Available" 2 "Error" 1 "Power limited for this reason" 0 "No power limit for this reason" ;
VAL_ 2364710142 ChargePLDueToStOfCharge 3 "Not Available" 2 "Error" 1 "Power limited for this reason" 0 "No power limit for this reason" ;
VAL_ 2364710142 DisPLDueToAnUndefinedCause 3 "Not Available" 2 "Error" 1 "Power limited for this reason" 0 "No power limit for this reason" ;
VAL_ 2364710142 DisPLDueToBatCur 3 "Not Available" 2 "Error" 1 "Power limited for this reason" 0 "No power limit for this reason" ;
VAL_ 2364710142 DisPLDueToBatOrCellV 3 "Not Available" 2 "Error" 1 "Power limited for this reason" 0 "No power limit for this reason" ;
VAL_ 2364710142 DisPLDueToBatDiagCondition 3 "Not Available" 2 "Error" 1 "Power limited for this reason" 0 "No power limit for this reason" ;
VAL_ 2364710142 DisPLDueToBatTemp 3 "Not Available" 2 "Error" 1 "Power limited for this reason" 0 "No power limit for this reason" ;
VAL_ 2364710142 DisPLDueToStOfCharge 3 "Not Available" 2 "Error" 1 "Power limited for this reason" 0 "No power limit for this reason" ;
VAL_ 2364709374 Data9EmbeddedIntegritySupport 3 "CRC and Counter are not supported by the sender" 2 "Reserved" 1 "Protection is supported using J1939-76 SHM" 0 "Embedded CRC and Counter are supported by the sender" ;
VAL_ 2364709374 HVESS15ThermalEventDetected 3 "Not available" 2 "Error" 1 "Thermal Event Detected" 0 "No Thermal Event Detected" ;
VAL_ 2364708862 TMSCoolantLvl 3 "Not Available" 2 "Error" 1 "Coolant Level is sufficient" 0 "Coolant Level is not sufficient" ;
VAL_ 2364708862 TMSMode 15 "Not Available" 14 "Faulted" 13 "Reserved" 12 "Reserved" 11 "Reserved" 10 "Reserved" 9 "Reserved" 8 "Reserved" 7 "Reserved" 6 "Reserved" 5 "Maintaining" 4 "Drying" 3 "Heating" 2 "Cooling" 1 "Circulating" 0 "Off" ;
VAL_ 2364708862 TMSHVILStatus 3 "Not Available" 2 "Error" 1 "HVIL Open" 0 "HVIL Closed" ;
VAL_ 2364708862 TMSHtrStatus 3 "Not Available" 2 "Error" 1 "Heater On" 0 "Heater Off" ;
VAL_ 2364708606 Module32OperationalStatus 3 "Not Available" 2 "Error" 1 "Operational" 0 "Not Operational" ;
VAL_ 2364708606 Module31OperationalStatus 3 "Not Available" 2 "Error" 1 "Operational" 0 "Not Operational" ;
VAL_ 2364708606 Module30OperationalStatus 3 "Not Available" 2 "Error" 1 "Operational" 0 "Not Operational" ;
VAL_ 2364708606 Module29OperationalStatus 3 "Not Available" 2 "Error" 1 "Operational" 0 "Not Operational" ;
VAL_ 2364708606 Module28OperationalStatus 3 "Not Available" 2 "Error" 1 "Operational" 0 "Not Operational" ;
VAL_ 2364708606 Module27OperationalStatus 3 "Not Available" 2 "Error" 1 "Operational" 0 "Not Operational" ;
VAL_ 2364708606 Module26OperationalStatus 3 "Not Available" 2 "Error" 1 "Operational" 0 "Not Operational" ;
VAL_ 2364708606 Module25OperationalStatus 3 "Not Available" 2 "Error" 1 "Operational" 0 "Not Operational" ;
VAL_ 2364708606 Module24OperationalStatus 3 "Not Available" 2 "Error" 1 "Operational" 0 "Not Operational" ;
VAL_ 2364708606 Module23OperationalStatus 3 "Not Available" 2 "Error" 1 "Operational" 0 "Not Operational" ;
VAL_ 2364708606 Module22OperationalStatus 3 "Not Available" 2 "Error" 1 "Operational" 0 "Not Operational" ;
VAL_ 2364708606 Module21OperationalStatus 3 "Not Available" 2 "Error" 1 "Operational" 0 "Not Operational" ;
VAL_ 2364708606 Module20OperationalStatus 3 "Not Available" 2 "Error" 1 "Operational" 0 "Not Operational" ;
VAL_ 2364708606 Module19OperationalStatus 3 "Not Available" 2 "Error" 1 "Operational" 0 "Not Operational" ;
VAL_ 2364708606 Module18OperationalStatus 3 "Not Available" 2 "Error" 1 "Operational" 0 "Not Operational" ;
VAL_ 2364708606 Module17OperationalStatus 3 "Not Available" 2 "Error" 1 "Operational" 0 "Not Operational" ;
VAL_ 2364708606 Module16OperationalStatus 3 "Not Available" 2 "Error" 1 "Operational" 0 "Not Operational" ;
VAL_ 2364708606 Module15OperationalStatus 3 "Not Available" 2 "Error" 1 "Operational" 0 "Not Operational" ;
VAL_ 2364708606 Module14OperationalStatus 3 "Not Available" 2 "Error" 1 "Operational" 0 "Not Operational" ;
VAL_ 2364708606 Module13OperationalStatus 3 "Not Available" 2 "Error" 1 "Operational" 0 "Not Operational" ;
VAL_ 2364708606 Module12OperationalStatus 3 "Not Available" 2 "Error" 1 "Operational" 0 "Not Operational" ;
VAL_ 2364708606 Module11OperationalStatus 3 "Not Available" 2 "Error" 1 "Operational" 0 "Not Operational" ;
VAL_ 2364708606 Module10OperationalStatus 3 "Not Available" 2 "Error" 1 "Operational" 0 "Not Operational" ;
VAL_ 2364708606 Module9OperationalStatus 3 "Not Available" 2 "Error" 1 "Operational" 0 "Not Operational" ;
VAL_ 2364708606 Module8OperationalStatus 3 "Not Available" 2 "Error" 1 "Operational" 0 "Not Operational" ;
VAL_ 2364708606 Module7OperationalStatus 3 "Not Available" 2 "Error" 1 "Operational" 0 "Not Operational" ;
VAL_ 2364708606 Module6OperationalStatus 3 "Not Available" 2 "Error" 1 "Operational" 0 "Not Operational" ;
VAL_ 2364708606 Module5OperationalStatus 3 "Not Available" 2 "Error" 1 "Operational" 0 "Not Operational" ;
VAL_ 2364708606 Module4OperationalStatus 3 "Not Available" 2 "Error" 1 "Operational" 0 "Not Operational" ;
VAL_ 2364708606 Module3OperationalStatus 3 "Not Available" 2 "Error" 1 "Operational" 0 "Not Operational" ;
VAL_ 2364708606 Module2OperationalStatus 3 "Not Available" 2 "Error" 1 "Operational" 0 "Not Operational" ;
VAL_ 2364708606 Module1OperationalStatus 3 "Not Available" 2 "Error" 1 "Operational" 0 "Not Operational" ;
VAL_ 2364708094 OperationalStatus 15 "Not Available" 14 "Error" 13 "Reserved" 12 "Reserved" 11 "Reserved" 10 "Reserved" 9 "Reserved" 8 "Reserved" 7 "Reserved" 6 "Disabled by internal decision of HVES controller" 5 "Disabled by external command" 4 "Emergency Power-Down In Process" 3 "Normal Power-Down in Process" 2 "Operational." 1 "Initialization Complete" 0 "Initialization in process" ;
VAL_ 2364708094 HVBusConnectionStatus 15 "Not Available" 14 "Error" 13 "Reserved" 12 "Reserved" 11 "Reserved" 10 "Reserved" 9 "Reserved" 8 "Reserved" 7 "Reserved" 6 "Reserved" 5 "Reserved" 4 "Disconnected,  Precharge Failed" 3 "Disconnection in Process" 2 "Connection in Process" 1 "Connected" 0 "Disconnected, One or more contactors are open" ;
VAL_ 2364708094 InternalChargerStatus 3 "Not Available" 2 "Error" 1 "Charging on" 0 "Charging off" ;
VAL_ 2364708094 CellBalancingActive 3 "Not Available" 2 "Error" 1 "Cell balancing is active" 0 "Cell balancing is not active" ;
VAL_ 2364708094 CellBalanceStatus 3 "Not Available" 2 "Error" 1 "Cells are unbalanced" 0 "Cells are balanced" ;
VAL_ 2364708094 StOfChargeStatus 15 "Not  Available" 14 "Error" 13 "Reserved" 12 "Reserved" 11 "Reserved" 10 "Reserved" 9 "Reserved" 8 "Reserved" 7 "Reserved" 6 "SOC is above its recommended upper limit" 5 "SOC is at its recommended upper limit" 4 "SOC is approaching its recommended upper limit" 3 "SOC is below its recommended lower limit" 2 "SOC is at its recommended lower limit" 1 "SOC is approaching its recommended lower limit" 0 "SOC level is acceptable" ;
VAL_ 2364708094 InertiaSwStatus 3 "Not Available" 2 "Error" 1 "Impact sensed" 0 "No impact sensed" ;
VAL_ 2364708094 HVILStatus 3 "Not Available" 2 "Error" 1 "HVIL Open" 0 "HVIL Closed" ;
VAL_ 2364708094 HVBusPassiveIsolTestStatus 15 "Not available" 14 "Error" 13 "Reserved" 12 "Reserved" 11 "Reserved" 10 "Reserved" 9 "Reserved" 8 "Reserved" 7 "Reserved" 6 "Reserved" 5 "Test complete,  isolation fault" 4 "Test complete,  isolation marginal" 3 "Test complete,  isolation acceptable" 2 "Test in process" 1 "Test requested but not yet in process" 0 "No test requested / No test in process" ;
VAL_ 2364708094 HVBusActiveIsolTestStatus 15 "Not available" 14 "Error" 13 "Reserved" 12 "Reserved" 11 "Reserved" 10 "Reserved" 9 "Reserved" 8 "Reserved" 7 "Reserved" 6 "Reserved" 5 "Test complete,  isolation fault" 4 "Test complete,  isolation marginal" 3 "Test complete,  isolation acceptable" 2 "Test in process" 1 "Test requested but not yet in process" 0 "No test requested / No test in process" ;
VAL_ 2364708094 CenterOfPackContactorSt 3 "Not Available" 2 "Error" 1 "Contactor Closed" 0 "Contactor Open" ;
VAL_ 2364708094 HVBusPreChargeRelaySt 3 "Not Available" 2 "Error" 1 "Relay Closed" 0 "Relay Open" ;
VAL_ 2364708094 HVBusDisconnectForewarning 15 "Not Available" 14 "Error" 13 "Disconnect imminent" 12 "Reserved" 11 "Reserved" 10 "Reserved" 9 "Reserved" 8 "Reserved" 7 "Disconnect imminent due to battery pack current approaching maximum acceptable level" 6 "Disconnect imminent due to cell voltage approaching maximum acceptable level" 5 "Disconnect imminent due to cell voltage approaching minimum acceptable level" 4 "Disconnect imminent due to module voltage approaching maximum acceptable level" 3 "Disconnect imminent due to module voltage approaching minimum acceptable level" 2 "Disconnect imminent due to battery pack voltage approaching maximum acceptable level" 1 "Disconnect imminent due to battery pack voltage approaching minimum acceptable level" 0 "Disconnect not pending" ;
VAL_ 2364708094 HVBusContactorSt15886 3 "Not Available" 2 "Error" 1 "Contactor Closed" 0 "Contactor Open" ;
VAL_ 2364708094 HVBusContactorSt 3 "Not Available" 2 "Error" 1 "Contactor Closed" 0 "Contactor Open" ;
VAL_ 2364707070 CellTempDiffStatus 3 "Not Available" 2 "Error" 1 "Cell-to-cell temperature differential exceeds acceptable limits" 0 "Cell-to-cell temperature differential is within acceptable limits" ;
VAL_ 2364706814 CellVDiffStatus 15 "Not Available" 14 "Error" 13 "Reserved" 12 "Reserved" 11 "Reserved" 10 "Reserved" 9 "Reserved" 8 "Reserved" 7 "Reserved" 6 "Reserved" 5 "Reserved" 4 "Exceeds limits and it is not known whether balancing can restore performance" 3 "Exceeds limits and external maintenance balancing cannot restore performance" 2 "Exceeds limits and external maintenance balancing is required" 1 "Exceeds limits and can be corrected via auto-balancing" 0 "Is within acceptable limits" ;
VAL_ 2364706302 ChargePLDueToAnUndefinedCause 3 "Not Available" 2 "Error" 1 "Power limited for this reason" 0 "No power limit for this reason" ;
VAL_ 2364706302 ChargePLDueToBatCur 3 "Not Available" 2 "Error" 1 "Power limited for this reason" 0 "No power limit for this reason" ;
VAL_ 2364706302 ChargePLDueToBatOrCellV 3 "Not Available" 2 "Error" 1 "Power limited for this reason" 0 "No power limit for this reason" ;
VAL_ 2364706302 ChargePLDueToBatDiagCondition 3 "Not Available" 2 "Error" 1 "Power limited for this reason" 0 "No power limit for this reason" ;
VAL_ 2364706302 ChargePLDueToBatTemp 3 "Not Available" 2 "Error" 1 "Power limited for this reason" 0 "No power limit for this reason" ;
VAL_ 2364706302 ChargePLDueToStOfCharge 3 "Not Available" 2 "Error" 1 "Power limited for this reason" 0 "No power limit for this reason" ;
VAL_ 2364706302 DisPLDueToAnUndefinedCause 3 "Not Available" 2 "Error" 1 "Power limited for this reason" 0 "No power limit for this reason" ;
VAL_ 2364706302 DisPLDueToBatCur 3 "Not Available" 2 "Error" 1 "Power limited for this reason" 0 "No power limit for this reason" ;
VAL_ 2364706302 DisPLDueToBatOrCellV 3 "Not Available" 2 "Error" 1 "Power limited for this reason" 0 "No power limit for this reason" ;
VAL_ 2364706302 DisPLDueToBatDiagCondition 3 "Not Available" 2 "Error" 1 "Power limited for this reason" 0 "No power limit for this reason" ;
VAL_ 2364706302 DisPLDueToBatTemp 3 "Not Available" 2 "Error" 1 "Power limited for this reason" 0 "No power limit for this reason" ;
VAL_ 2364706302 DisPLDueToStOfCharge 3 "Not Available" 2 "Error" 1 "Power limited for this reason" 0 "No power limit for this reason" ;
VAL_ 2364705534 Data9EmbeddedIntegritySupport 3 "CRC and Counter are not supported by the sender" 2 "Reserved" 1 "Protection is supported using J1939-76 SHM" 0 "Embedded CRC and Counter are supported by the sender" ;
VAL_ 2364705534 HVESS14ThermalEventDetected 3 "Not available" 2 "Error" 1 "Thermal Event Detected" 0 "No Thermal Event Detected" ;
VAL_ 2364705022 TMSCoolantLvl 3 "Not Available" 2 "Error" 1 "Coolant Level is sufficient" 0 "Coolant Level is not sufficient" ;
VAL_ 2364705022 TMSMode 15 "Not Available" 14 "Faulted" 13 "Reserved" 12 "Reserved" 11 "Reserved" 10 "Reserved" 9 "Reserved" 8 "Reserved" 7 "Reserved" 6 "Reserved" 5 "Maintaining" 4 "Drying" 3 "Heating" 2 "Cooling" 1 "Circulating" 0 "Off" ;
VAL_ 2364705022 TMSHVILStatus 3 "Not Available" 2 "Error" 1 "HVIL Open" 0 "HVIL Closed" ;
VAL_ 2364705022 TMSHtrStatus 3 "Not Available" 2 "Error" 1 "Heater On" 0 "Heater Off" ;
VAL_ 2364704766 Module32OperationalStatus 3 "Not Available" 2 "Error" 1 "Operational" 0 "Not Operational" ;
VAL_ 2364704766 Module31OperationalStatus 3 "Not Available" 2 "Error" 1 "Operational" 0 "Not Operational" ;
VAL_ 2364704766 Module30OperationalStatus 3 "Not Available" 2 "Error" 1 "Operational" 0 "Not Operational" ;
VAL_ 2364704766 Module29OperationalStatus 3 "Not Available" 2 "Error" 1 "Operational" 0 "Not Operational" ;
VAL_ 2364704766 Module28OperationalStatus 3 "Not Available" 2 "Error" 1 "Operational" 0 "Not Operational" ;
VAL_ 2364704766 Module27OperationalStatus 3 "Not Available" 2 "Error" 1 "Operational" 0 "Not Operational" ;
VAL_ 2364704766 Module26OperationalStatus 3 "Not Available" 2 "Error" 1 "Operational" 0 "Not Operational" ;
VAL_ 2364704766 Module25OperationalStatus 3 "Not Available" 2 "Error" 1 "Operational" 0 "Not Operational" ;
VAL_ 2364704766 Module24OperationalStatus 3 "Not Available" 2 "Error" 1 "Operational" 0 "Not Operational" ;
VAL_ 2364704766 Module23OperationalStatus 3 "Not Available" 2 "Error" 1 "Operational" 0 "Not Operational" ;
VAL_ 2364704766 Module22OperationalStatus 3 "Not Available" 2 "Error" 1 "Operational" 0 "Not Operational" ;
VAL_ 2364704766 Module21OperationalStatus 3 "Not Available" 2 "Error" 1 "Operational" 0 "Not Operational" ;
VAL_ 2364704766 Module20OperationalStatus 3 "Not Available" 2 "Error" 1 "Operational" 0 "Not Operational" ;
VAL_ 2364704766 Module19OperationalStatus 3 "Not Available" 2 "Error" 1 "Operational" 0 "Not Operational" ;
VAL_ 2364704766 Module18OperationalStatus 3 "Not Available" 2 "Error" 1 "Operational" 0 "Not Operational" ;
VAL_ 2364704766 Module17OperationalStatus 3 "Not Available" 2 "Error" 1 "Operational" 0 "Not Operational" ;
VAL_ 2364704766 Module16OperationalStatus 3 "Not Available" 2 "Error" 1 "Operational" 0 "Not Operational" ;
VAL_ 2364704766 Module15OperationalStatus 3 "Not Available" 2 "Error" 1 "Operational" 0 "Not Operational" ;
VAL_ 2364704766 Module14OperationalStatus 3 "Not Available" 2 "Error" 1 "Operational" 0 "Not Operational" ;
VAL_ 2364704766 Module13OperationalStatus 3 "Not Available" 2 "Error" 1 "Operational" 0 "Not Operational" ;
VAL_ 2364704766 Module12OperationalStatus 3 "Not Available" 2 "Error" 1 "Operational" 0 "Not Operational" ;
VAL_ 2364704766 Module11OperationalStatus 3 "Not Available" 2 "Error" 1 "Operational" 0 "Not Operational" ;
VAL_ 2364704766 Module10OperationalStatus 3 "Not Available" 2 "Error" 1 "Operational" 0 "Not Operational" ;
VAL_ 2364704766 Module9OperationalStatus 3 "Not Available" 2 "Error" 1 "Operational" 0 "Not Operational" ;
VAL_ 2364704766 Module8OperationalStatus 3 "Not Available" 2 "Error" 1 "Operational" 0 "Not Operational" ;
VAL_ 2364704766 Module7OperationalStatus 3 "Not Available" 2 "Error" 1 "Operational" 0 "Not Operational" ;
VAL_ 2364704766 Module6OperationalStatus 3 "Not Available" 2 "Error" 1 "Operational" 0 "Not Operational" ;
VAL_ 2364704766 Module5OperationalStatus 3 "Not Available" 2 "Error" 1 "Operational" 0 "Not Operational" ;
VAL_ 2364704766 Module4OperationalStatus 3 "Not Available" 2 "Error" 1 "Operational" 0 "Not Operational" ;
VAL_ 2364704766 Module3OperationalStatus 3 "Not Available" 2 "Error" 1 "Operational" 0 "Not Operational" ;
VAL_ 2364704766 Module2OperationalStatus 3 "Not Available" 2 "Error" 1 "Operational" 0 "Not Operational" ;
VAL_ 2364704766 Module1OperationalStatus 3 "Not Available" 2 "Error" 1 "Operational" 0 "Not Operational" ;
VAL_ 2364704254 OperationalStatus 15 "Not Available" 14 "Error" 13 "Reserved" 12 "Reserved" 11 "Reserved" 10 "Reserved" 9 "Reserved" 8 "Reserved" 7 "Reserved" 6 "Disabled by internal decision of HVES controller" 5 "Disabled by external command" 4 "Emergency Power-Down In Process" 3 "Normal Power-Down in Process" 2 "Operational." 1 "Initialization Complete" 0 "Initialization in process" ;
VAL_ 2364704254 HVBusConnectionStatus 15 "Not Available" 14 "Error" 13 "Reserved" 12 "Reserved" 11 "Reserved" 10 "Reserved" 9 "Reserved" 8 "Reserved" 7 "Reserved" 6 "Reserved" 5 "Reserved" 4 "Disconnected,  Precharge Failed" 3 "Disconnection in Process" 2 "Connection in Process" 1 "Connected" 0 "Disconnected, One or more contactors are open" ;
VAL_ 2364704254 InternalChargerStatus 3 "Not Available" 2 "Error" 1 "Charging on" 0 "Charging off" ;
VAL_ 2364704254 CellBalancingActive 3 "Not Available" 2 "Error" 1 "Cell balancing is active" 0 "Cell balancing is not active" ;
VAL_ 2364704254 CellBalanceStatus 3 "Not Available" 2 "Error" 1 "Cells are unbalanced" 0 "Cells are balanced" ;
VAL_ 2364704254 StOfChargeStatus 15 "Not  Available" 14 "Error" 13 "Reserved" 12 "Reserved" 11 "Reserved" 10 "Reserved" 9 "Reserved" 8 "Reserved" 7 "Reserved" 6 "SOC is above its recommended upper limit" 5 "SOC is at its recommended upper limit" 4 "SOC is approaching its recommended upper limit" 3 "SOC is below its recommended lower limit" 2 "SOC is at its recommended lower limit" 1 "SOC is approaching its recommended lower limit" 0 "SOC level is acceptable" ;
VAL_ 2364704254 InertiaSwStatus 3 "Not Available" 2 "Error" 1 "Impact sensed" 0 "No impact sensed" ;
VAL_ 2364704254 HVILStatus 3 "Not Available" 2 "Error" 1 "HVIL Open" 0 "HVIL Closed" ;
VAL_ 2364704254 HVBusPassiveIsolTestStatus 15 "Not available" 14 "Error" 13 "Reserved" 12 "Reserved" 11 "Reserved" 10 "Reserved" 9 "Reserved" 8 "Reserved" 7 "Reserved" 6 "Reserved" 5 "Test complete,  isolation fault" 4 "Test complete,  isolation marginal" 3 "Test complete,  isolation acceptable" 2 "Test in process" 1 "Test requested but not yet in process" 0 "No test requested / No test in process" ;
VAL_ 2364704254 HVBusActiveIsolTestStatus 15 "Not available" 14 "Error" 13 "Reserved" 12 "Reserved" 11 "Reserved" 10 "Reserved" 9 "Reserved" 8 "Reserved" 7 "Reserved" 6 "Reserved" 5 "Test complete,  isolation fault" 4 "Test complete,  isolation marginal" 3 "Test complete,  isolation acceptable" 2 "Test in process" 1 "Test requested but not yet in process" 0 "No test requested / No test in process" ;
VAL_ 2364704254 CenterOfPackContactorSt 3 "Not Available" 2 "Error" 1 "Contactor Closed" 0 "Contactor Open" ;
VAL_ 2364704254 HVBusPreChargeRelaySt 3 "Not Available" 2 "Error" 1 "Relay Closed" 0 "Relay Open" ;
VAL_ 2364704254 HVBusDisconnectForewarning 15 "Not Available" 14 "Error" 13 "Disconnect imminent" 12 "Reserved" 11 "Reserved" 10 "Reserved" 9 "Reserved" 8 "Reserved" 7 "Disconnect imminent due to battery pack current approaching maximum acceptable level" 6 "Disconnect imminent due to cell voltage approaching maximum acceptable level" 5 "Disconnect imminent due to cell voltage approaching minimum acceptable level" 4 "Disconnect imminent due to module voltage approaching maximum acceptable level" 3 "Disconnect imminent due to module voltage approaching minimum acceptable level" 2 "Disconnect imminent due to battery pack voltage approaching maximum acceptable level" 1 "Disconnect imminent due to battery pack voltage approaching minimum acceptable level" 0 "Disconnect not pending" ;
VAL_ 2364704254 HVBusContactorSt15744 3 "Not Available" 2 "Error" 1 "Contactor Closed" 0 "Contactor Open" ;
VAL_ 2364704254 HVBusContactorSt 3 "Not Available" 2 "Error" 1 "Contactor Closed" 0 "Contactor Open" ;
VAL_ 2364703230 CellTempDiffStatus 3 "Not Available" 2 "Error" 1 "Cell-to-cell temperature differential exceeds acceptable limits" 0 "Cell-to-cell temperature differential is within acceptable limits" ;
VAL_ 2364702974 CellVDiffStatus 15 "Not Available" 14 "Error" 13 "Reserved" 12 "Reserved" 11 "Reserved" 10 "Reserved" 9 "Reserved" 8 "Reserved" 7 "Reserved" 6 "Reserved" 5 "Reserved" 4 "Exceeds limits and it is not known whether balancing can restore performance" 3 "Exceeds limits and external maintenance balancing cannot restore performance" 2 "Exceeds limits and external maintenance balancing is required" 1 "Exceeds limits and can be corrected via auto-balancing" 0 "Is within acceptable limits" ;
VAL_ 2364702462 ChargePLDueToAnUndefinedCause 3 "Not Available" 2 "Error" 1 "Power limited for this reason" 0 "No power limit for this reason" ;
VAL_ 2364702462 ChargePLDueToBatCur 3 "Not Available" 2 "Error" 1 "Power limited for this reason" 0 "No power limit for this reason" ;
VAL_ 2364702462 ChargePLDueToBatOrCellV 3 "Not Available" 2 "Error" 1 "Power limited for this reason" 0 "No power limit for this reason" ;
VAL_ 2364702462 ChargePLDueToBatDiagCondition 3 "Not Available" 2 "Error" 1 "Power limited for this reason" 0 "No power limit for this reason" ;
VAL_ 2364702462 ChargePLDueToBatTemp 3 "Not Available" 2 "Error" 1 "Power limited for this reason" 0 "No power limit for this reason" ;
VAL_ 2364702462 ChargePLDueToStOfCharge 3 "Not Available" 2 "Error" 1 "Power limited for this reason" 0 "No power limit for this reason" ;
VAL_ 2364702462 DisPLDueToAnUndefinedCause 3 "Not Available" 2 "Error" 1 "Power limited for this reason" 0 "No power limit for this reason" ;
VAL_ 2364702462 DisPLDueToBatCur 3 "Not Available" 2 "Error" 1 "Power limited for this reason" 0 "No power limit for this reason" ;
VAL_ 2364702462 DisPLDueToBatOrCellV 3 "Not Available" 2 "Error" 1 "Power limited for this reason" 0 "No power limit for this reason" ;
VAL_ 2364702462 DisPLDueToBatDiagCondition 3 "Not Available" 2 "Error" 1 "Power limited for this reason" 0 "No power limit for this reason" ;
VAL_ 2364702462 DisPLDueToBatTemp 3 "Not Available" 2 "Error" 1 "Power limited for this reason" 0 "No power limit for this reason" ;
VAL_ 2364702462 DisPLDueToStOfCharge 3 "Not Available" 2 "Error" 1 "Power limited for this reason" 0 "No power limit for this reason" ;
